VERSION "hnnbnnnynnnnnnnnnnnnnnnnnnnnnnnnnnnnnnnnnn/4/%%%/4/'%**4nnn///"

NS_ :

BS_:

BU_: BAP_Tester Fahrerdisplay_Kombi HUD ICAS1_X_Gateway ICAS3_Gateway ICC_IO_Node Kombi SmartLight_01 ZR_MIB_TOP_ab_Gen3

BO_ 1153 MainUnit_01: 8 ICAS3_Gateway
	SG_ DSSS_Warning : 16|5@1+ (1,0) [0|31] ""  ICAS1_X_Gateway
	SG_ HMI_WLC1_Systemzustand_intern : 40|3@1+ (1,0) [0|7] ""  ICAS1_X_Gateway
	SG_ HMI_WLC2_Systemzustand_intern : 43|3@1+ (1,0) [0|7] ""  ICAS1_X_Gateway
	SG_ INF_Nachlaufzeit : 52|10@1+ (1,0) [0|509] "Minut"  ICAS1_X_Gateway
	SG_ MIB_ASW_Diagnose : 7|1@1+ (1,0) [0|1] ""  ICAS1_X_Gateway
	SG_ MIB_Tongenerator_PH_verfuegbar : 9|3@1+ (1,0) [0|7] ""  ICAS1_X_Gateway
	SG_ MMI_Counter_Bedienevent : 12|4@1+ (1,0) [0|15] ""  ICAS1_X_Gateway
	SG_ MMI_Gurt_Mic_ref : 28|1@1+ (1,0) [0|1] ""  ICAS1_X_Gateway
	SG_ MMI_SDS_aktiv : 23|1@1+ (1,0) [0|1] ""  ICAS1_X_Gateway
	SG_ MMI_Telefon_aktiv : 27|1@1+ (1,0) [0|1] ""  ICAS1_X_Gateway
	SG_ MU_SecondDisplay : 24|3@1+ (1,0) [0|7] ""  ICAS1_X_Gateway
	SG_ MU_Update_Time : 32|8@1+ (0.1,0) [0|25.5] "Hours"  ICAS1_X_Gateway
	SG_ Nav_FoD_Status : 4|3@1+ (1,0) [0|7] ""  ICAS1_X_Gateway,Kombi
	SG_ ZR_AppConnect_Zustand : 31|1@1+ (1,0) [0|1] ""  ICAS1_X_Gateway
	SG_ ZR_Kindersicherung_RSE : 21|1@1+ (1,0) [0|1] ""  ICAS1_X_Gateway
	SG_ ZR_Lichter_Tag : 8|1@1+ (1,0) [0|1] ""  ICAS1_X_Gateway
	SG_ ZR_LoGeWa_Event_Kombiwarnung : 0|4@1+ (1,0) [0|15] ""  ICAS1_X_Gateway,Kombi
	SG_ ZR_Parken_Sondermodus : 48|4@1+ (1,0) [0|15] ""  ICAS1_X_Gateway
	SG_ ZR_RSE_aktivieren : 22|1@1+ (1,0) [0|1] ""  ICAS1_X_Gateway

BO_ 1639 Mem_BFS_01: 8 ICAS1_X_Gateway
	SG_ BFS_Fond_Bed_Ack : 12|1@1+ (1,0) [0|1] ""  Vector__XXX
	SG_ BFS_FSV_ausgeklappt : 42|1@1+ (1,0) [0|1] ""  Vector__XXX
	SG_ BFS_GHV_aktiv : 27|1@1+ (1,0) [0|1] ""  Vector__XXX
	SG_ BFS_Gurtbringer_Sperre : 15|1@1+ (1,0) [0|1] ""  Vector__XXX
	SG_ BFS_Klapptisch_offen : 14|1@1+ (1,0) [0|1] ""  Vector__XXX
	SG_ BFS_KSS_Fahrt_aktiv : 28|1@1+ (1,0) [0|1] ""  Vector__XXX
	SG_ BFS_KSV_aktiv : 22|1@1+ (1,0) [0|1] ""  Vector__XXX
	SG_ BFS_Lehne_nicht_verriegelt : 13|1@1+ (1,0) [0|1] ""  Vector__XXX
	SG_ BFS_LHV_aktiv : 25|1@1+ (1,0) [0|1] ""  Vector__XXX
	SG_ BFS_LKV_aktiv : 23|1@1+ (1,0) [0|1] ""  Vector__XXX
	SG_ BFS_LNV_aktiv : 20|1@1+ (1,0) [0|1] ""  Vector__XXX
	SG_ BFS_LWV_aktiv : 26|1@1+ (1,0) [0|1] ""  Vector__XXX
	SG_ BFS_MMB_glob_stop : 41|1@1+ (1,0) [0|1] ""  Vector__XXX
	SG_ BFS_MMB_lokal_Stop : 29|1@1+ (1,0) [0|1] ""  Vector__XXX
	SG_ BFS_MMB_storage : 32|4@1+ (1,0) [0|15] ""  Vector__XXX
	SG_ BFS_MMB_storage_beep : 39|1@1+ (1,0) [0|1] ""  Kombi
	SG_ BFS_MMB_store : 40|1@1+ (1,0) [0|1] ""  Vector__XXX
	SG_ BFS_MMB_store_LED_on : 38|1@1+ (1,0) [0|1] ""  Vector__XXX
	SG_ BFS_MMB_tast : 37|1@1+ (1,0) [0|1] ""  Vector__XXX
	SG_ BFS_MMB_tipp : 36|1@1+ (1,0) [0|1] ""  Vector__XXX
	SG_ BFS_Ruhestellung_Status : 30|1@1+ (1,0) [0|1] ""  Vector__XXX
	SG_ BFS_Seat_Locked : 31|1@1+ (1,0) [0|1] ""  Vector__XXX
	SG_ BFS_SHV_aktiv : 19|1@1+ (1,0) [0|1] ""  Vector__XXX
	SG_ BFS_Sitzfahrt_aktiv : 17|1@1+ (1,0) [0|1] ""  Vector__XXX
	SG_ BFS_Sitzsym_Fahrt_aktiv : 16|1@1+ (1,0) [0|1] ""  Vector__XXX
	SG_ BFS_SLV_aktiv : 18|1@1+ (1,0) [0|1] ""  Vector__XXX
	SG_ BFS_SNV_aktiv : 21|1@1+ (1,0) [0|1] ""  Vector__XXX
	SG_ BFS_STV_aktiv : 24|1@1+ (1,0) [0|1] ""  Vector__XXX

BO_ 1178 Mem_FS_01: 8 ICAS1_X_Gateway
	SG_ FS_BFS_Fond_Verst_enable : 44|1@1+ (1,0) [0|1] ""  Vector__XXX
	SG_ FS_BFS_KSS_Anfahrt : 28|1@1+ (1,0) [0|1] ""  Vector__XXX
	SG_ FS_BFS_Sitzsym_Anfahrt : 16|1@1+ (1,0) [0|1] ""  Vector__XXX
	SG_ FS_EE_BFS_enable : 45|1@1+ (1,0) [0|1] ""  Vector__XXX
	SG_ FS_EE_Fond_BFS_enable : 43|1@1+ (1,0) [0|1] ""  Vector__XXX
	SG_ FS_EE_Fond_FS_enable : 42|1@1+ (1,0) [0|1] ""  Vector__XXX
	SG_ FS_Fond_Bed_enable : 12|1@1+ (1,0) [0|1] ""  Vector__XXX
	SG_ FS_GHV_aktiv : 27|1@1+ (1,0) [0|1] ""  Vector__XXX
	SG_ FS_Gurtbringer_Sperre : 15|1@1+ (1,0) [0|1] ""  Vector__XXX
	SG_ FS_KSV_aktiv : 22|1@1+ (1,0) [0|1] ""  Vector__XXX
	SG_ FS_Lehne_nicht_verriegelt : 13|1@1+ (1,0) [0|1] ""  Vector__XXX
	SG_ FS_LHV_aktiv : 25|1@1+ (1,0) [0|1] ""  Vector__XXX
	SG_ FS_LKV_aktiv : 23|1@1+ (1,0) [0|1] ""  Vector__XXX
	SG_ FS_LNV_aktiv : 20|1@1+ (1,0) [0|1] ""  Vector__XXX
	SG_ FS_LWV_aktiv : 26|1@1+ (1,0) [0|1] ""  Vector__XXX
	SG_ FS_MMB_glob_stop : 41|1@1+ (1,0) [0|1] ""  Vector__XXX
	SG_ FS_MMB_lokal_Stop : 29|1@1+ (1,0) [0|1] ""  Vector__XXX
	SG_ FS_MMB_storage : 32|4@1+ (1,0) [0|15] ""  Vector__XXX
	SG_ FS_MMB_storage_beep : 39|1@1+ (1,0) [0|1] ""  Kombi
	SG_ FS_MMB_store : 40|1@1+ (1,0) [0|1] ""  Vector__XXX
	SG_ FS_MMB_store_LED_on : 38|1@1+ (1,0) [0|1] ""  Vector__XXX
	SG_ FS_MMB_tast : 37|1@1+ (1,0) [0|1] ""  Vector__XXX
	SG_ FS_MMB_tipp : 36|1@1+ (1,0) [0|1] ""  Vector__XXX
	SG_ FS_SHV_aktiv : 19|1@1+ (1,0) [0|1] ""  Vector__XXX
	SG_ FS_Sitzfahrt_aktiv : 17|1@1+ (1,0) [0|1] ""  Vector__XXX
	SG_ FS_SLV_aktiv : 18|1@1+ (1,0) [0|1] ""  Vector__XXX
	SG_ FS_SNV_aktiv : 21|1@1+ (1,0) [0|1] ""  Vector__XXX
	SG_ FS_Spezialposition_anfahren : 14|1@1+ (1,0) [0|1] ""  Vector__XXX
	SG_ FS_STV_aktiv : 24|1@1+ (1,0) [0|1] ""  Vector__XXX

BO_ 1171 MFG_01: 8 ICAS1_X_Gateway
	SG_ MF_Abzugssperre : 14|1@1+ (1,0) [0|1] ""  Vector__XXX
	SG_ MF_Alarm_Blinker : 50|1@1+ (1,0) [0|1] ""  Vector__XXX
	SG_ MF_Alarm_Blinkertakt : 49|1@1+ (1,0) [0|1] ""  Vector__XXX
	SG_ MF_Anlassersperre : 15|1@1+ (1,0) [0|1] ""  Vector__XXX
	SG_ MF_Blk_li : 32|1@1+ (1,0) [0|1] ""  Vector__XXX
	SG_ MF_Blk_re : 33|1@1+ (1,0) [0|1] ""  Vector__XXX
	SG_ MF_BT_entriegeln : 63|1@1+ (1,0) [0|1] ""  Vector__XXX
	SG_ MF_BT_verriegeln : 62|1@1+ (1,0) [0|1] ""  Vector__XXX
	SG_ MF_Fahrlicht : 25|1@1+ (1,0) [0|1] ""  Vector__XXX
	SG_ MF_Fernbed_ein : 23|1@1+ (1,0) [0|1] ""  Vector__XXX
	SG_ MF_Fernlicht : 35|1@1+ (1,0) [0|1] ""  Vector__XXX
	SG_ MF_FH_BT_hoch : 58|1@1+ (1,0) [0|1] ""  Vector__XXX
	SG_ MF_FH_BT_tief : 59|1@1+ (1,0) [0|1] ""  Vector__XXX
	SG_ MF_FH_FT_hoch : 56|1@1+ (1,0) [0|1] ""  Vector__XXX
	SG_ MF_FH_FT_tief : 57|1@1+ (1,0) [0|1] ""  Vector__XXX
	SG_ MF_Frontintervall : 41|1@1+ (1,0) [0|1] ""  Vector__XXX
	SG_ MF_Frontwaschen : 44|1@1+ (1,0) [0|1] ""  Vector__XXX
	SG_ MF_FT_entriegeln : 61|1@1+ (1,0) [0|1] ""  Vector__XXX
	SG_ MF_FT_verriegeln : 60|1@1+ (1,0) [0|1] ""  Vector__XXX
	SG_ MF_Fussraumbel : 28|1@1+ (1,0) [0|1] ""  Vector__XXX
	SG_ MF_HBFS_entriegeln : 39|1@1+ (1,0) [0|1] ""  Vector__XXX
	SG_ MF_HBFS_verriegeln : 38|1@1+ (1,0) [0|1] ""  Vector__XXX
	SG_ MF_Heckintervall : 46|1@1+ (1,0) [0|1] ""  Vector__XXX
	SG_ MF_Heckwaschen : 47|1@1+ (1,0) [0|1] ""  Vector__XXX
	SG_ MF_HFS_entriegeln : 37|1@1+ (1,0) [0|1] ""  Vector__XXX
	SG_ MF_HFS_verriegeln : 36|1@1+ (1,0) [0|1] ""  Vector__XXX
	SG_ MF_Innenraumbel : 29|1@1+ (1,0) [0|1] ""  Vector__XXX
	SG_ MF_Innenraumbel_Unterdrueck : 30|1@1+ (1,0) [0|1] ""  SmartLight_01
	SG_ MF_interm_Fahrlicht : 54|1@1+ (1,0) [0|1] ""  Vector__XXX
	SG_ MF_interm_Fernlicht : 26|1@1+ (1,0) [0|1] ""  Vector__XXX
	SG_ MF_interm_Takt : 52|1@1+ (1,0) [0|1] ""  Vector__XXX
	SG_ MF_Laderelais : 20|1@1+ (1,0) [0|1] ""  Vector__XXX
	SG_ MF_Lichthupe : 34|1@1+ (1,0) [0|1] ""  Vector__XXX
	SG_ MF_Motorweiterlauf : 13|1@1+ (1,0) [0|1] ""  Vector__XXX
	SG_ MF_nachtr_Stopp_Anf : 45|1@1+ (1,0) [0|1] ""  Vector__XXX
	SG_ MF_Notstart : 31|1@1+ (1,0) [0|1] ""  Vector__XXX
	SG_ MF_Schluessel_scan : 19|1@1+ (1,0) [0|1] ""  Vector__XXX
	SG_ MF_Signalhorn : 55|1@1+ (1,0) [0|1] ""  Vector__XXX
	SG_ MF_Standlicht : 24|1@1+ (1,0) [0|1] ""  Vector__XXX
	SG_ MF_StartStopp_Info : 21|2@1+ (1,0) [0|3] ""  Vector__XXX
	SG_ MF_Summer : 48|1@1+ (1,0) [0|1] ""  Kombi
	SG_ MF_TFL_Abschaltung : 51|1@1+ (1,0) [0|1] ""  Vector__XXX
	SG_ MF_Tippwischen : 40|1@1+ (1,0) [0|1] ""  Vector__XXX
	SG_ MF_Tuerentriegelung_hinten : 53|1@1+ (1,0) [0|1] ""  Vector__XXX
	SG_ MF_Variante : 16|3@1+ (1,0) [0|7] ""  Vector__XXX
	SG_ MF_Warnblinker : 27|1@1+ (1,0) [0|1] ""  Vector__XXX
	SG_ MF_Wischerstufe_1 : 42|1@1+ (1,0) [0|1] ""  Vector__XXX
	SG_ MF_Wischerstufe_2 : 43|1@1+ (1,0) [0|1] ""  Vector__XXX
	SG_ MF_ZV_Lock : 12|1@1+ (1,0) [0|1] ""  Vector__XXX
	SG_ MFG_01_BZ : 8|4@1+ (1,0) [0|15] ""  Vector__XXX
	SG_ MFG_01_CRC : 0|8@1+ (1,0) [0|255] ""  Vector__XXX

BO_ 1164 MFG_03: 8 ICAS1_X_Gateway
	SG_ MF_2BatSOCzugering : 42|1@1+ (1,0) [0|1] ""  Vector__XXX
	SG_ MF_2BattAb : 48|1@1+ (1,0) [0|1] ""  Vector__XXX
	SG_ MF_2BattHlkAnf : 49|1@1+ (1,0) [0|1] ""  Vector__XXX
	SG_ MF_2BattLadWarn : 50|1@1+ (1,0) [0|1] ""  Vector__XXX
	SG_ MF_2BattLlaAnf : 51|1@1+ (1,0) [0|1] ""  Vector__XXX
	SG_ MF_2BattSpannungsAnf : 52|2@1+ (1,0) [0|3] ""  Vector__XXX
	SG_ MF_Batteriediagnose : 29|3@1+ (1,0) [0|7] ""  Vector__XXX
	SG_ MF_Blinker_L_Sta : 35|1@1+ (1,0) [0|1] ""  Vector__XXX
	SG_ MF_Blinker_R_Sta : 36|1@1+ (1,0) [0|1] ""  Vector__XXX
	SG_ MF_ExterneLadungWarn : 55|1@1+ (1,0) [0|1] ""  Vector__XXX
	SG_ MF_Fahrerhinweis : 43|3@1+ (1,0) [0|7] ""  Vector__XXX
	SG_ MF_Generatordiagnose : 38|2@1+ (1,0) [0|3] ""  Vector__XXX
	SG_ MF_Heck_entriegeln : 40|1@1+ (1,0) [0|1] ""  Vector__XXX
	SG_ MF_Heck_verriegeln : 41|1@1+ (1,0) [0|1] ""  Vector__XXX
	SG_ MF_interm_Nebelscheinwerfer : 37|1@1+ (1,0) [0|1] ""  Vector__XXX
	SG_ MF_Lampenausfall : 34|1@1+ (1,0) [0|1] ""  Vector__XXX
	SG_ MF_LSH_Abschaltstufe : 60|3@1+ (1,0) [0|7] ""  Vector__XXX
	SG_ MF_LSH_Einschaltverbot : 63|1@1+ (1,0) [0|1] ""  Vector__XXX
	SG_ MF_LSH_Zielzeit : 56|4@1+ (10,0) [0|130] "Minut"  Vector__XXX
	SG_ MF_NotStartAktiv : 54|1@1+ (1,0) [0|1] ""  Vector__XXX
	SG_ MF_Radiomute : 27|1@1+ (1,0) [0|1] ""  ICAS3_Gateway
	SG_ MF_Relais_2_Batterie : 28|1@1+ (1,0) [0|1] ""  Vector__XXX
	SG_ MF_Tuerverriegelung_hinten : 47|1@1+ (1,0) [0|1] ""  Vector__XXX
	SG_ MF_ZV_Unlock : 46|1@1+ (1,0) [0|1] ""  Vector__XXX
	SG_ MFG_AppConnect_Anf : 32|2@1+ (1,0) [0|3] ""  Vector__XXX
	SG_ MFG_Klappe_Status : 13|3@1+ (1,0) [0|7] ""  Vector__XXX

BO_ 817 MFL_01: 8 ICAS1_X_Gateway
	SG_ MFL_Dummy_0_Signal_1 : 40|8@1+ (1,0) [0|255] ""  Vector__XXX
	SG_ MFL_Dummy_0_Signal_3 : 53|1@1+ (1,0) [0|1] ""  Vector__XXX
	SG_ MFL_ECU_Err : 62|1@1+ (1,0) [0|1] ""  Vector__XXX
	SG_ MFL_Eventcode_1 : 24|4@1+ (1,0) [0|15] ""  Vector__XXX
	SG_ MFL_Eventcode_2 : 28|4@1+ (1,0) [0|15] ""  Vector__XXX
	SG_ MFL_Fehler_Codierung : 52|1@1+ (1,0) [0|1] ""  Vector__XXX
	SG_ MFL_Lokalaktiv : 5|1@1+ (1,0) [0|1] ""  Vector__XXX
	SG_ MFL_LR_HZG_Err : 55|1@1+ (1,0) [0|1] ""  Vector__XXX
	SG_ MFL_LR_HZG_Status : 54|1@1+ (1,0) [0|1] ""  Vector__XXX
	SG_ MFL_M_Taste : 6|1@1+ (1,0) [0|1] ""  Vector__XXX
	SG_ MFL_Marke : 32|4@1+ (1,0) [0|15] ""  Vector__XXX
	SG_ MFL_Paddle_Verbau : 7|1@1+ (1,0) [0|1] ""  Kombi
	SG_ MFL_Response_Err : 63|1@1+ (1,0) [0|1] ""  Vector__XXX
	SG_ MFL_SatModul_links_Err : 50|1@1+ (1,0) [0|1] ""  Vector__XXX
	SG_ MFL_SatModul_rechts_Err : 51|1@1+ (1,0) [0|1] ""  Vector__XXX
	SG_ MFL_Signalhorn : 56|1@1+ (1,0) [0|1] ""  Vector__XXX
	SG_ MFL_Signalhorn_Err : 57|1@1+ (1,0) [0|1] ""  Vector__XXX
	SG_ MFL_Taste_links_Err : 60|1@1+ (1,0) [0|1] ""  Vector__XXX
	SG_ MFL_Taste_rechts_Err : 61|1@1+ (1,0) [0|1] ""  Vector__XXX
	SG_ MFL_Tastencode_1 : 8|8@1+ (1,0) [0|255] ""  Vector__XXX
	SG_ MFL_Tastencode_2 : 16|8@1+ (1,0) [0|255] ""  Vector__XXX
	SG_ MFL_Tip_Down : 48|1@1+ (1,0) [0|1] ""  Vector__XXX
	SG_ MFL_Tip_links_Err : 58|1@1+ (1,0) [0|1] ""  Vector__XXX
	SG_ MFL_Tip_rechts_Err : 59|1@1+ (1,0) [0|1] ""  Vector__XXX
	SG_ MFL_Tip_Up : 49|1@1+ (1,0) [0|1] ""  Vector__XXX
	SG_ MFL_Toggle : 4|1@1+ (1,0) [0|1] ""  Vector__XXX
	SG_ MFL_Variante : 36|4@1+ (1,0) [0|15] ""  Vector__XXX
	SG_ MFL_Zaehler : 0|4@1+ (1,0) [0|15] ""  Vector__XXX

BO_ 560 MFL_02: 8 ICAS1_X_Gateway
	SG_ MFL_Beruehrungserkennung : 12|2@1+ (1,0) [0|3] ""  ICAS3_Gateway
	SG_ MFL_Touch_Event : 14|4@1+ (1,0) [0|15] ""  ICAS3_Gateway

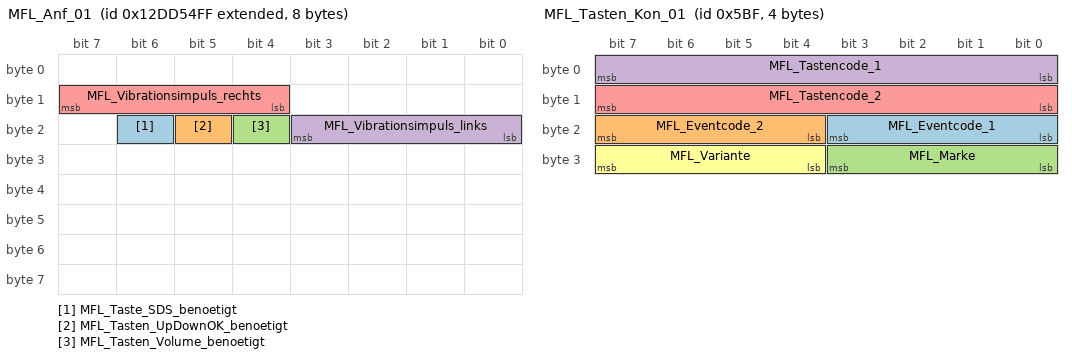
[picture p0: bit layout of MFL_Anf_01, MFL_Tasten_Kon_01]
BO_ 2463978751 MFL_Anf_01: 8 ICAS3_Gateway
	SG_ MFL_Taste_SDS_benoetigt : 22|1@1+ (1,0) [0|1] ""  ICAS1_X_Gateway
	SG_ MFL_Tasten_UpDownOK_benoetigt : 21|1@1+ (1,0) [0|1] ""  ICAS1_X_Gateway
	SG_ MFL_Tasten_Volume_benoetigt : 20|1@1+ (1,0) [0|1] ""  ICAS1_X_Gateway
	SG_ MFL_Vibrationsimpuls_links : 16|4@1+ (1,0) [0|15] ""  ICAS1_X_Gateway
	SG_ MFL_Vibrationsimpuls_rechts : 12|4@1+ (1,0) [0|15] ""  ICAS1_X_Gateway

BO_ 1471 MFL_Tasten_Kon_01: 4 ICAS1_X_Gateway
	SG_ MFL_Eventcode_1 : 16|4@1+ (1,0) [0|15] ""  ICAS3_Gateway,ICC_IO_Node,Kombi,ZR_MIB_TOP_ab_Gen3
	SG_ MFL_Eventcode_2 : 20|4@1+ (1,0) [0|15] ""  ICAS3_Gateway,ICC_IO_Node,Kombi,ZR_MIB_TOP_ab_Gen3
	SG_ MFL_Marke : 24|4@1+ (1,0) [0|15] ""  ICAS3_Gateway,ICC_IO_Node,Kombi,ZR_MIB_TOP_ab_Gen3
	SG_ MFL_Tastencode_1 : 0|8@1+ (1,0) [0|255] ""  ICAS3_Gateway,ICC_IO_Node,Kombi,ZR_MIB_TOP_ab_Gen3
	SG_ MFL_Tastencode_2 : 8|8@1+ (1,0) [0|255] ""  ICAS3_Gateway,ICC_IO_Node,Kombi,ZR_MIB_TOP_ab_Gen3
	SG_ MFL_Variante : 28|4@1+ (1,0) [0|15] ""  ICAS3_Gateway,ICC_IO_Node,Kombi,ZR_MIB_TOP_ab_Gen3

BO_ 958 Motor_14: 8 ICAS1_X_Gateway
	SG_ MO_Aussp_Anlass : 35|1@1+ (1,0) [0|1] ""  Vector__XXX
	SG_ MO_BKV_Unterdruckwarnung : 45|1@1+ (1,0) [0|1] ""  Vector__XXX
	SG_ MO_BLS : 30|1@1+ (1,0) [0|1] ""  Vector__XXX
	SG_ MO_BMS_NV_Anf_stuetzen : 58|1@1+ (1,0) [0|1] ""  Vector__XXX
	SG_ MO_EKlKomLeiRed : 42|2@1+ (1,0) [0|3] ""  Vector__XXX
	SG_ MO_Ext_E_Fahrt_aktiv : 27|1@1+ (1,0) [0|1] ""  Vector__XXX
	SG_ MO_Fahrer_bremst : 28|1@1+ (1,0) [0|1] ""  ZR_MIB_TOP_ab_Gen3
	SG_ MO_FMAus_aktiv : 55|1@1+ (1,0) [0|1] ""  Vector__XXX
	SG_ MO_FMAus_Startvariante : 56|2@1+ (1,0) [0|3] ""  Vector__XXX
	SG_ MO_Freig_Anlass : 36|1@1+ (1,0) [0|1] ""  Vector__XXX
	SG_ MO_Freig_Reku : 16|2@1+ (1,0) [0|3] ""  Vector__XXX
	SG_ MO_Freigabe_Segeln : 46|1@1+ (1,0) [0|1] ""  Vector__XXX
	SG_ MO_Gangposition : 20|4@1+ (1,0) [0|15] ""  Vector__XXX
	SG_ MO_Handshake_STH : 44|1@1+ (1,0) [0|1] ""  Vector__XXX
	SG_ MO_HYB_Fahrbereitschaft : 26|1@1+ (1,0) [0|1] ""  ICAS3_Gateway,Kombi
	SG_ MO_HYB_VM_aktiv : 61|1@1+ (1,0) [0|1] ""  Vector__XXX
	SG_ MO_Interlock : 38|1@1+ (1,0) [0|1] ""  Vector__XXX
	SG_ MO_Kickdown : 40|1@1+ (1,0) [0|1] ""  ZR_MIB_TOP_ab_Gen3
	SG_ MO_Kl_50 : 19|1@1+ (1,0) [0|1] ""  ZR_MIB_TOP_ab_Gen3
	SG_ MO_Kl_75 : 18|1@1+ (1,0) [0|1] ""  ZR_MIB_TOP_ab_Gen3
	SG_ MO_Klima_Eingr : 33|2@1+ (1,0) [0|3] ""  Vector__XXX
	SG_ MO_Konsistenz_Bremsped : 31|1@1+ (1,0) [0|1] ""  Vector__XXX
	SG_ MO_Kuppl_schalter : 37|1@1+ (1,0) [0|1] ""  Vector__XXX
	SG_ MO_Motor_laeuft : 39|1@1+ (1,0) [0|1] ""  Vector__XXX
	SG_ MO_PTC_Status : 47|3@1+ (1,0) [0|7] ""  Vector__XXX
	SG_ MO_QBit_Fahrer_bremst : 29|1@1+ (1,0) [0|1] ""  ZR_MIB_TOP_ab_Gen3
	SG_ MO_QBit_Gangposition : 50|1@1+ (1,0) [0|1] ""  Vector__XXX
	SG_ MO_QBit_KL_75 : 41|1@1+ (1,0) [0|1] ""  Vector__XXX
	SG_ MO_Remotestart_Betrieb : 52|1@1+ (1,0) [0|1] ""  Vector__XXX
	SG_ MO_Remotestart_moeglich : 53|1@1+ (1,0) [0|1] ""  Vector__XXX
	SG_ MO_Signalquelle_Gangposition : 51|1@1+ (1,0) [0|1] ""  Vector__XXX
	SG_ MO_StartStopp_Fahrerwunsch : 24|2@1+ (1,0) [0|3] ""  Vector__XXX
	SG_ MO_StartStopp_Motorstopp : 15|1@1+ (1,0) [0|1] ""  Vector__XXX
	SG_ MO_StartStopp_Status : 12|2@1+ (1,0) [0|3] ""  Vector__XXX
	SG_ MO_StartStopp_Wiederstart : 14|1@1+ (1,0) [0|1] ""  ZR_MIB_TOP_ab_Gen3
	SG_ MO_StartVorauss_erfuellt : 62|2@1+ (1,0) [0|3] ""  Vector__XXX
	SG_ MO_Timeout_ESP : 32|1@1+ (1,0) [0|1] ""  Vector__XXX
	SG_ MO_Zylinderabschaltung : 59|2@1+ (1,0) [0|3] ""  Vector__XXX
	SG_ Motor_14_BZ : 8|4@1+ (1,0) [0|15] ""  Vector__XXX
	SG_ Motor_14_CRC : 0|8@1+ (1,0) [0|255] ""  Vector__XXX

BO_ 1648 Motor_18: 8 ICAS1_X_Gateway
	SG_ MO1_Freigabe_Info_WFS : 12|1@1+ (1,0) [0|1] ""  Vector__XXX
	SG_ MO1_Freigabe_Verfallsinfo_WFS : 42|1@1+ (1,0) [0|1] ""  Vector__XXX
	SG_ MO1_Sperr_Info_WFS : 11|1@1+ (1,0) [0|1] ""  Vector__XXX
	SG_ MO_Abstellzeit : 32|8@1+ (8,0) [0|2024] "Minut"  Vector__XXX
	SG_ MO_Abstellzeit_Status : 40|2@1+ (1,0) [0|3] ""  Vector__XXX
	SG_ MO_ANC_Kennfeld_Anf : 6|2@1+ (1,0) [0|3] ""  Vector__XXX
	SG_ MO_Anzahl_Abgesch_Zyl : 47|3@1+ (1,0) [0|7] ""  Vector__XXX
	SG_ MO_Bremslicht_Reku : 8|1@1+ (1,0) [0|1] ""  Vector__XXX
	SG_ MO_Drehzahl_Warnung : 55|1@1+ (1,0) [0|1] ""  Vector__XXX
	SG_ MO_EPCL : 13|3@1+ (1,0) [0|7] ""  Fahrerdisplay_Kombi,Kombi
	SG_ MO_Ethanol_BS_Texte : 52|3@1+ (1,0) [0|7] ""  Vector__XXX
	SG_ MO_Fahrzeugtyp : 20|3@1+ (1,0) [0|7] ""  Fahrerdisplay_Kombi,Kombi
	SG_ MO_Fehler_Zylabsch : 45|2@1+ (1,0) [0|3] ""  Vector__XXX
	SG_ MO_Hybrid_StartStopp_LED : 43|2@1+ (1,0) [0|3] ""  Vector__XXX
	SG_ MO_max_Ladedruck : 0|6@1+ (0.1,0) [0|6.3] "Bar"  Vector__XXX
	SG_ MO_NMAX_Schaltanzeige : 23|9@1+ (25,0) [0|12775] "MinutInver"  Vector__XXX
	SG_ MO_obere_Drehzahlgrenze : 56|8@1+ (50,0) [50|12750] "MinutInver"  Vector__XXX
	SG_ MO_StartStopp_PopUp : 9|2@1+ (1,0) [0|3] ""  Vector__XXX
	SG_ MO_Zylabsch_Texte : 50|2@1+ (1,0) [0|3] ""  Vector__XXX
	SG_ MO_Zylabsch_Texte_02 : 16|4@1+ (1,0) [0|15] ""  Vector__XXX

BO_ 967 Motor_26: 8 ICAS1_X_Gateway
	SG_ MO_E_Mode : 61|3@1+ (1,0) [0|7] ""  Vector__XXX
	SG_ MO_E_Texte : 36|4@1+ (1,0) [0|15] ""  Vector__XXX
	SG_ MO_E_Warnungen : 28|4@1+ (1,0) [0|15] ""  Vector__XXX
	SG_ MO_EFLEX_Lampe : 8|2@1+ (1,0) [0|3] ""  Vector__XXX
	SG_ MO_Heissleuchte : 50|1@1+ (1,0) [0|1] ""  Vector__XXX
	SG_ MO_ITM_Warnung_Pumpe : 11|1@1+ (1,0) [0|1] ""  Vector__XXX
	SG_ MO_KJS_nicht_bereit : 10|1@1+ (1,0) [0|1] ""  Vector__XXX
	SG_ MO_Kuehlerluefter_1 m0 : 1|7@1+ (1,0) [0|100] "PerCent"  Vector__XXX
	SG_ MO_Kuehlerluefter_2 m1 : 1|7@1+ (1,0) [0|100] "PerCent"  Vector__XXX
	SG_ MO_Kuehlerluefter_MUX M : 0|1@1+ (1,0) [0|1] ""  Vector__XXX
	SG_ MO_OBD2_Lampe : 49|1@1+ (1,0) [0|1] ""  Fahrerdisplay_Kombi,Kombi
	SG_ MO_Oelwarnung_max : 23|1@1+ (1,0) [0|1] ""  Vector__XXX
	SG_ MO_Partikel_Lampe : 51|1@1+ (1,0) [0|1] ""  Vector__XXX
	SG_ MO_RedFahrleistung_Lampe : 52|1@1+ (1,0) [0|1] ""  Kombi
	SG_ MO_Systemlampe : 48|1@1+ (1,0) [0|1] ""  Vector__XXX
	SG_ MO_Tankdeckel_Lampe : 57|1@1+ (1,0) [0|1] ""  Vector__XXX
	SG_ MO_Text_Motorstart : 32|4@1+ (1,0) [0|15] ""  Vector__XXX
	SG_ MO_Text_Partikelfil_Reg : 41|1@1+ (1,0) [0|1] ""  Vector__XXX
	SG_ MO_Text_Tankdeckelwarn : 58|1@1+ (1,0) [0|1] ""  Vector__XXX
	SG_ MO_Vorglueh_Lampe : 59|1@1+ (1,0) [0|1] ""  Vector__XXX
	SG_ MO_Zustand_HWP : 20|2@1+ (1,0) [0|3] ""  Vector__XXX
	SG_ OLEV_Oelstand_nicht_vorhanden : 42|1@1+ (1,0) [0|1] ""  Vector__XXX
	SG_ OLEV_Systemstoerung : 22|1@1+ (1,0) [0|1] ""  Vector__XXX
	SG_ WIV_Anzeige_aktiv : 12|1@1+ (1,0) [0|1] ""  Vector__XXX
	SG_ WIV_laufender_Motor : 27|1@1+ (1,0) [0|1] ""  Vector__XXX
	SG_ WIV_nachfuellanzeige_ein : 54|1@1+ (1,0) [0|1] ""  Vector__XXX
	SG_ WIV_nicht_betriebswarm : 25|1@1+ (1,0) [0|1] ""  Vector__XXX
	SG_ WIV_Oeldr_Warn_Motor : 60|1@1+ (1,0) [0|1] ""  Vector__XXX
	SG_ WIV_Oeldyn_avl : 40|1@1+ (1,0) [0|1] ""  Vector__XXX
	SG_ WIV_Oelmenge : 43|5@1+ (125,0) [0|3875] "MilliLiter"  Vector__XXX
	SG_ WIV_Oelmin_Warn : 13|1@1+ (1,0) [0|1] ""  Vector__XXX
	SG_ WIV_Oelstand : 16|4@1+ (12.5,0) [0|100] "PerCent"  Vector__XXX
	SG_ WIV_Oelstand_nicht_vorhanden : 53|1@1+ (1,0) [0|1] ""  Vector__XXX
	SG_ WIV_Oelsystem_aktiv : 24|1@1+ (1,0) [0|1] ""  Vector__XXX
	SG_ WIV_Schieflage : 15|1@1+ (1,0) [0|1] ""  Vector__XXX
	SG_ WIV_Sensorfehler : 14|1@1+ (1,0) [0|1] ""  Vector__XXX
	SG_ WIV_Ueberfuell_deaktiv : 55|1@1+ (1,0) [0|1] ""  Vector__XXX
	SG_ WIV_Ueberfuell_Warn : 26|1@1+ (1,0) [0|1] ""  Vector__XXX
	SG_ WIV_Unterfuell_Warn : 56|1@1+ (1,0) [0|1] ""  Vector__XXX

BO_ 966 Motor_26_SOK_Signatur: 8 ICAS1_X_Gateway
	SG_ SOK_Motor_26_Signatur : 0|64@1+ (1,0) [0|18446744073709551616] ""  Vector__XXX

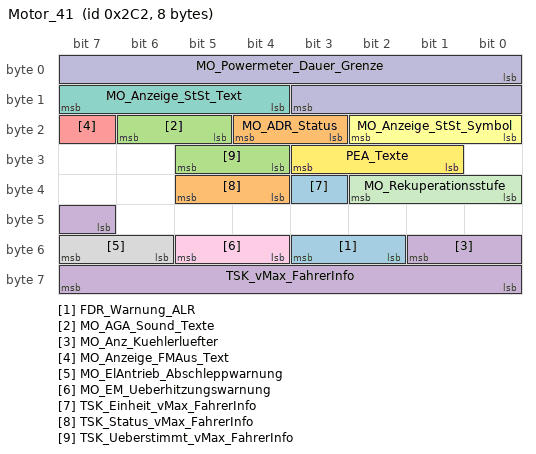
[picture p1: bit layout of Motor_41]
BO_ 706 Motor_41: 8 ICAS1_X_Gateway
	SG_ FDR_Warnung_ALR : 50|2@1+ (1,0) [0|3] ""  Kombi
	SG_ MO_ADR_Status : 19|2@1+ (1,0) [0|3] ""  Vector__XXX
	SG_ MO_AGA_Sound_Texte : 21|2@1+ (1,0) [0|3] ""  Vector__XXX
	SG_ MO_Anz_Kuehlerluefter : 47|3@1+ (1,0) [0|7] ""  Vector__XXX
	SG_ MO_Anzeige_FMAus_Text : 23|1@1+ (1,0) [0|1] ""  Vector__XXX
	SG_ MO_Anzeige_StSt_Symbol : 16|3@1+ (1,0) [0|7] ""  Vector__XXX
	SG_ MO_Anzeige_StSt_Text : 12|4@1+ (1,0) [0|15] ""  Vector__XXX
	SG_ MO_ElAntrieb_Abschleppwarnung : 54|2@1+ (1,0) [0|3] ""  Kombi
	SG_ MO_EM_Ueberhitzungswarnung : 52|2@1+ (1,0) [0|3] ""  Kombi
	SG_ MO_Powermeter_Dauer_Grenze : 0|12@1+ (1,0) [0|4093] "None"  Vector__XXX
	SG_ MO_Rekuperationsstufe : 32|3@1+ (1,0) [0|7] ""  Kombi
	SG_ PEA_Texte : 25|3@1+ (1,0) [0|7] ""  Vector__XXX
	SG_ TSK_Einheit_vMax_FahrerInfo : 35|1@1+ (1,0) [0|1] ""  Vector__XXX
	SG_ TSK_Status_vMax_FahrerInfo : 36|2@1+ (1,0) [0|3] ""  Vector__XXX
	SG_ TSK_Ueberstimmt_vMax_FahrerInfo : 28|2@1+ (1,0) [0|3] ""  Vector__XXX
	SG_ TSK_vMax_FahrerInfo : 56|8@1+ (1,15) [16|270] ""  Vector__XXX

BO_ 267 Motor_51_Auth: 48 ICAS1_X_Gateway
	SG_ MO_Entkopplung_Sollschlupf : 48|7@1+ (20,0) [0|2480] "MinutInver"  Vector__XXX
	SG_ MO_Fahrpedalgradient : 21|8@1+ (25,0) [0|6350] "PerCentPerSecon"  Vector__XXX
	SG_ MO_Fahrpedalrohwert_01 : 12|8@1+ (0.4,0) [0|101.6] "PerCent"  ZR_MIB_TOP_ab_Gen3
	SG_ MO_Moment_im_Leerlauf : 37|1@1+ (1,0) [0|1] ""  Vector__XXX
	SG_ MO_QBit_Fahrpedalwerte_01 : 20|1@1+ (1,0) [0|1] ""  Vector__XXX
	SG_ MO_rel_Saugrohrdruck : 30|6@1+ (18,0) [0|1116] "MilliBar"  Vector__XXX
	SG_ MO_rel_Saugrohrdruck_gem_err : 36|1@1+ (1,0) [0|1] ""  Vector__XXX
	SG_ MO_Schubabschaltung : 38|1@1+ (1,0) [0|1] ""  Vector__XXX
	SG_ MO_Sig_Fahrpedalgradient : 29|1@1+ (1,0) [0|1] ""  Vector__XXX
	SG_ MO_Solldrehz_Leerlauf : 40|8@1+ (10,0) [0|2540] "MinutInver"  Vector__XXX
	SG_ MO_StartStopp_StoppVorbereitung : 39|1@1+ (1,0) [0|1] ""  Vector__XXX
	SG_ MO_Status_MaxDrzEingriff : 238|3@1+ (1,0) [0|7] ""  Vector__XXX
	SG_ MO_Status_MaxDrzEingriff_sek : 244|3@1+ (1,0) [0|7] ""  Vector__XXX
	SG_ MO_Status_MinDrzEingriff : 235|3@1+ (1,0) [0|7] ""  Vector__XXX
	SG_ MO_Status_MinDrzEingriff_sek : 241|3@1+ (1,0) [0|7] ""  Vector__XXX
	SG_ MO_temporaere_Fahrerabwesenheit : 55|1@1+ (1,0) [0|1] ""  Vector__XXX
	SG_ Motor_51_BZ : 8|4@1+ (1,0) [0|15] ""  Vector__XXX
	SG_ Motor_51_CRC : 0|8@1+ (1,0) [0|255] ""  Vector__XXX
	SG_ SOK_Motor_51_Signatur : 352|32@1+ (1,0) [0|4294967295] ""  Vector__XXX
	SG_ TSK_a_Soll_gradientenbegrenzt : 57|7@1+ (0.1,-7.2) [-7.2|5.4] "MeterPerSeconSquar"  Vector__XXX
	SG_ TSK_ax_Getriebe_02 : 112|9@1+ (0.024,-2.016) [-2.016|10.224] "MeterPerSeconSquar"  Vector__XXX
	SG_ TSK_Freig_Verzoeg_Anf : 94|1@1+ (1,0) [0|1] ""  Vector__XXX
	SG_ TSK_Hauptschalter_GRA_ACC : 106|2@1+ (1,0) [0|3] ""  Kombi
	SG_ TSK_Kategorie_Verzoegerungsfkt : 144|2@1+ (1,0) [0|3] ""  Vector__XXX
	SG_ TSK_Limiter_ausgewaehlt : 95|1@1+ (1,0) [0|1] ""  Vector__XXX
	SG_ TSK_Notstopp_Anf : 233|2@1+ (1,0) [0|3] ""  Vector__XXX
	SG_ TSK_Radbremsmom : 76|12@1+ (8,0) [0|32760] "NewtoMeter"  Vector__XXX
	SG_ TSK_Radsollmoment : 128|16@1+ (0.5,-16383) [-16383|16383.5] "NewtoMeter"  Vector__XXX
	SG_ TSK_SRBM_Anf_ASIL : 108|3@1+ (1,0) [0|7] ""  Vector__XXX
	SG_ TSK_SRBM_max_Gradient : 248|7@1+ (50,0) [0|6250] "NewtoMeterPerSecon"  Vector__XXX
	SG_ TSK_Standby_Anf_ESP : 92|1@1+ (1,0) [0|1] ""  Vector__XXX
	SG_ TSK_Status : 88|3@1+ (1,0) [0|7] ""  Vector__XXX
	SG_ TSK_v_Begrenzung_aktiv : 91|1@1+ (1,0) [0|1] ""  Vector__XXX
	SG_ TSK_zul_Regelabw : 122|6@1+ (0.024,0) [0|1.512] "MeterPerSeconSquar"  Vector__XXX
	SG_ TSK_Zwangszusch_ESP : 121|1@1+ (1,0) [0|1] ""  Vector__XXX

BO_ 330 Motor_52: 32 ICAS1_X_Gateway
	SG_ Ladezustand_02 : 152|8@1+ (0.5,0) [0|100] "PerCent"  Kombi,ZR_MIB_TOP_ab_Gen3
	SG_ Ladezustand_gering : 160|2@1+ (1,0) [0|3] ""  Kombi
	SG_ MO_Anzeige_Drehmoment : 42|11@1+ (1,0) [0|2045] "NewtoMeter"  Vector__XXX
	SG_ MO_Anzeige_Leistung : 53|11@1+ (0.6,0) [0|1227] "KiloWatt"  Vector__XXX
	SG_ MO_Anzeige_Verbr_Einheit : 33|2@1+ (1,0) [0|3] ""  Vector__XXX
	SG_ MO_Anzeigedrehz : 88|12@1+ (3,0) [0|12282] "MinutInver"  Vector__XXX
	SG_ MO_Effizienzmodus : 100|1@1+ (1,0) [0|1] ""  Vector__XXX
	SG_ MO_ePerformance : 136|8@1+ (0.4,-0.4) [0|100.8] "PerCent"  Kombi
	SG_ MO_ePowermeter : 128|8@1+ (0.4,-0.4) [0|100.8] "PerCent"  Vector__XXX
	SG_ MO_Fehler_Oeldrucksensor : 101|1@1+ (1,0) [0|1] ""  Vector__XXX
	SG_ MO_Hochschaltdrehz : 21|12@1+ (3,0) [3|12282] "MinutInver"  Vector__XXX
	SG_ MO_Istgang : 72|4@1+ (1,0) [0|15] ""  Vector__XXX
	SG_ MO_KVS : 112|15@1+ (1,0) [0|32767] "MicroLiter"  Vector__XXX
	SG_ MO_KVS_Ueberlauf : 127|1@1+ (1,0) [0|1] ""  Vector__XXX
	SG_ MO_Ladedruck : 103|9@1+ (0.01,0) [0|5.1] "Bar"  Vector__XXX
	SG_ MO_Oeldruck : 80|8@1+ (0.04,0) [0|10] "Bar"  Vector__XXX
	SG_ MO_OnePedalDriving_Warnung : 192|2@1+ (1,0) [0|3] ""  Fahrerdisplay_Kombi,Kombi
	SG_ MO_Powermeter : 180|12@1+ (1,0) [0|4092] ""  Kombi
	SG_ MO_Powermeter_Elm_02 : 168|12@1+ (0.05,-102.4) [-100|100] "PerCent"  Vector__XXX
	SG_ MO_rel_Ladedruck : 64|8@1+ (0.4,0) [0|100] "PerCent"  Vector__XXX
	SG_ MO_Schaltblitz_Anz : 35|7@1+ (1,0) [0|100] "PerCent"  Vector__XXX
	SG_ MO_Schaltempf_verfbar : 102|1@1+ (1,0) [0|1] ""  Vector__XXX
	SG_ MO_Sollgang : 76|4@1+ (1,0) [0|15] ""  Vector__XXX
	SG_ MO_Zust_Antrieb : 144|4@1+ (1,0) [0|15] ""  Vector__XXX
	SG_ MO_Zust_Betriebsstrategie : 148|3@1+ (1,0) [0|7] ""  Vector__XXX
	SG_ Motor_52_BZ : 8|4@1+ (1,0) [0|15] ""  Kombi
	SG_ Motor_52_CRC : 0|8@1+ (1,0) [0|255] ""  Kombi

BO_TX_BU_ 1153 :ICAS3_Gateway,ZR_MIB_TOP_ab_Gen3;
BO_TX_BU_ 1639 :ICAS1_X_Gateway;
BO_TX_BU_ 1178 :ICAS1_X_Gateway;
BO_TX_BU_ 1171 :ICAS1_X_Gateway;
BO_TX_BU_ 1164 :ICAS1_X_Gateway;
BO_TX_BU_ 817 :ICAS1_X_Gateway;
BO_TX_BU_ 560 :ICAS1_X_Gateway;
BO_TX_BU_ 2463978751 :ICAS3_Gateway;
BO_TX_BU_ 1471 :ICAS1_X_Gateway;
BO_TX_BU_ 958 :ICAS1_X_Gateway;
BO_TX_BU_ 1648 :ICAS1_X_Gateway;
BO_TX_BU_ 967 :ICAS1_X_Gateway;
BO_TX_BU_ 966 :ICAS1_X_Gateway;
BO_TX_BU_ 706 :ICAS1_X_Gateway;
BO_TX_BU_ 267 :ICAS1_X_Gateway;
BO_TX_BU_ 330 :ICAS1_X_Gateway;
CM_ BO_ 1639 "MLBevo";
CM_ BO_ 1178 "ab MQB 7.2";
CM_ BO_ 1171 "ab MQB 7.2 gï?½ltig";
CM_ BO_ 1648 "Kombischnittstelle";
CM_ BO_ 967 "MQB - vorher Motor_06 / Umbenennung wg. ID-Wechsel";
CM_ SG_ 1153 DSSS_Warning "DSSS - Driving Safety Support System Meldungen";
CM_ SG_ 1153 HMI_WLC1_Systemzustand_intern "ï?½bertragung der HMI Einstellung fï?½r den WLC1 Systemzustand";
CM_ SG_ 1153 HMI_WLC2_Systemzustand_intern "ï?½bertragung der HMI Einstellung fï?½r den WLC2 Systemzustand";
CM_ SG_ 1153 INF_Nachlaufzeit "signal from ICAS3 to ICAS1 to request a prolonged shutdown of HV";
CM_ SG_ 1153 MIB_ASW_Diagnose "Diagnose Rï?½ckmeldung vom MIB zu Heckradar Entry. ASW Warnton Verfï?½gbarkeit.";
CM_ SG_ 1153 MIB_Tongenerator_PH_verfuegbar "Verfï?½gbarkeit des Tongenerators im MIB fï?½r die Nutzung durch die Parkhilfe";
CM_ SG_ 1153 MMI_Counter_Bedienevent "Signal wird inkrementiert, wenn Bedienevent stattgefunden hat.";
CM_ SG_ 1153 MMI_Gurt_Mic_ref "Referenzsignal fï?½r das Gurtmikrofon Steuergerï?½t zur Signalisierung ob der Downlink aktiv oder inaktiv ist";
CM_ SG_ 1153 MMI_SDS_aktiv "Signal wird gesetzt, solange die Sprachbedienung aktiv ist.";
CM_ SG_ 1153 MU_SecondDisplay "Dient zur ï?½berwachung der zweiten LVDS Leitung.";
CM_ SG_ 1153 MU_Update_Time "Ermï?½glicht auslesen der Historiendaten, wann ein Update lief";
CM_ SG_ 1153 Nav_FoD_Status "FoD Status der Navigation";
CM_ SG_ 1153 ZR_AppConnect_Zustand "Ist Zustand des AppConnect Kontextes im MIB";
CM_ SG_ 1153 ZR_Kindersicherung_RSE "Sperren der Rearseat Unit (Komplette Weckfï?½higkeit)";
CM_ SG_ 1153 ZR_Lichter_Tag "Berechnete Kennzeichnung des Sonnenstandes ï?½ber bzw. oder unter Horizont.";
CM_ SG_ 1153 ZR_LoGeWa_Event_Kombiwarnung "Event fï?½r Kombiwarnung";
CM_ SG_ 1153 ZR_Parken_Sondermodus "Rï?½ckkanal zum pilotierten Parken zur Signalisierung Status Sondermodus";
CM_ SG_ 1153 ZR_RSE_aktivieren "Weckfï?½higkeit der RSE";
CM_ SG_ 1639 BFS_Fond_Bed_Ack "Bestï?½tigung Beifahrersitzverstellung vom Fond";
CM_ SG_ 1639 BFS_FSV_ausgeklappt "Zustandssignalisierung der el. mech. Fuï?½stï?½tze (eingeklappt oder ausgeklappt)";
CM_ SG_ 1639 BFS_GHV_aktiv "Verstellung Gurthoehe\n";
CM_ SG_ 1639 BFS_Gurtbringer_Sperre "Freigabesignal fï?½r den Gurtzubringer";
CM_ SG_ 1639 BFS_Klapptisch_offen "Signalisiert eine Verstelleinschrï?½nkung des Beifahrersitz  (fï?½r BAP Visualisierung)";
CM_ SG_ 1639 BFS_KSS_Fahrt_aktiv "Komfortseitensichtfahrt (BFS)";
CM_ SG_ 1639 BFS_KSV_aktiv "Kopfstuetzenverstellung BFS\n";
CM_ SG_ 1639 BFS_Lehne_nicht_verriegelt "Fahrer Sitz Lehne Verstellung Verriegelt Status\n\nVerwendung nur im  Bentley";
CM_ SG_ 1639 BFS_LHV_aktiv "Verstellung Lordose Hï?½he\n";
CM_ SG_ 1639 BFS_LKV_aktiv "Verstellung Lehnenkopf\n";
CM_ SG_ 1639 BFS_LNV_aktiv "Verstellung Lehnenneigung\n";
CM_ SG_ 1639 BFS_LWV_aktiv "Lordose W Verstellung\n";
CM_ SG_ 1639 BFS_MMB_glob_stop "Abbruch Memoryverstellung";
CM_ SG_ 1639 BFS_MMB_lokal_Stop "mit dem lokal Stop moechte man, dass ein Sitz mit Pneumatik - Lordose sich im Memoryfall wie ein Sitz mit elektromechanischer Lordose verhaelt. Nur lokler Abbruch im TIP-Betrieb.";
CM_ SG_ 1639 BFS_MMB_storage "Speichern auf Memoryposition";
CM_ SG_ 1639 BFS_MMB_storage_beep "Quittierungston Sitzmemory BFS (Anforderung Kombi)\n\n";
CM_ SG_ 1639 BFS_MMB_store "Speichern der Sitzposition\n";
CM_ SG_ 1639 BFS_MMB_store_LED_on "LED fï?½r Speichern\n";
CM_ SG_ 1639 BFS_MMB_tast "Memoryverstellung im Tastbetrieb";
CM_ SG_ 1639 BFS_MMB_tipp "Memoryverstellung im Tippbetrieb";
CM_ SG_ 1639 BFS_Ruhestellung_Status "dient der Signalisierung fï?½r eine Verstelleinschrï?½nkung, da der Sitz sich in Ruhestellung befindet.";
CM_ SG_ 1639 BFS_Seat_Locked "Anzeige des gesperrten Beifahrersitzes aufgrund ungï?½ltiger Sitzposition.";
CM_ SG_ 1639 BFS_SHV_aktiv "Sitzhï?½henverstellung\n";
CM_ SG_ 1639 BFS_Sitzfahrt_aktiv "Aktive Sitzfahrt";
CM_ SG_ 1639 BFS_Sitzsym_Fahrt_aktiv "Sitzsymetriefahrt\n";
CM_ SG_ 1639 BFS_SLV_aktiv "Sitzlï?½ngsverstellung\n";
CM_ SG_ 1639 BFS_SNV_aktiv "Verstellung Sitzneigung\n";
CM_ SG_ 1639 BFS_STV_aktiv "Sitztiefeverstellung\n";
CM_ SG_ 1178 FS_BFS_Fond_Verst_enable "Verstellung Fond (vom MMI)\n";
CM_ SG_ 1178 FS_BFS_KSS_Anfahrt "Komfortseitensicht Anfahrt BFS";
CM_ SG_ 1178 FS_BFS_Sitzsym_Anfahrt "Sitzsymetrie Anfahrt BFS";
CM_ SG_ 1178 FS_EE_BFS_enable "EasyEntry Freigabe fï?½r Befahrersitz.";
CM_ SG_ 1178 FS_EE_Fond_BFS_enable "EE Fond rechts\n\n";
CM_ SG_ 1178 FS_EE_Fond_FS_enable "EE Fond links\n";
CM_ SG_ 1178 FS_Fond_Bed_enable "Freigabe fï?½r Fondsitzverstellungen";
CM_ SG_ 1178 FS_GHV_aktiv "Verstellung Gurthï?½he\n";
CM_ SG_ 1178 FS_Gurtbringer_Sperre "Freigabesignal fï?½r den Gurtzubringer";
CM_ SG_ 1178 FS_KSV_aktiv "Verstellung Kopfstï?½tze\n";
CM_ SG_ 1178 FS_Lehne_nicht_verriegelt "Fahrer Sitz Lehne Verstellung Verriegelt Status\n\nVerwendung nur im Bentley";
CM_ SG_ 1178 FS_LHV_aktiv "Verstellung Lordose Hï?½he\n";
CM_ SG_ 1178 FS_LKV_aktiv "Verstellung Lehnenkopf\n";
CM_ SG_ 1178 FS_LNV_aktiv "Verstellung Lehnenneigung\n";
CM_ SG_ 1178 FS_LWV_aktiv "Verstellung Lordose W\n";
CM_ SG_ 1178 FS_MMB_glob_stop "Abbruch Memoryverstellung";
CM_ SG_ 1178 FS_MMB_lokal_Stop "mit dem lokal Stop moechte man, dass ein Sitz mit Pneumatik - Lordose sich im Memoryfall wie ein Sitz mit elektromechanischer Lordose verhaelt. Nur lokler Abbruch im TIP-Betrieb.";
CM_ SG_ 1178 FS_MMB_storage "Memory-Positionstaste, Funkschlï?½ssel-Memory-ID, Benutzerkonto-Nummer";
CM_ SG_ 1178 FS_MMB_storage_beep "Quittierungston Sitzmemory FS (Anforderung Kombi)";
CM_ SG_ 1178 FS_MMB_store "Memoryposition Speichern";
CM_ SG_ 1178 FS_MMB_store_LED_on "LED fï?½r Speichern\n";
CM_ SG_ 1178 FS_MMB_tast "Memoryverstellung im Tastbetrieb";
CM_ SG_ 1178 FS_MMB_tipp "Memoryverstellung im Tippbetrieb";
CM_ SG_ 1178 FS_SHV_aktiv "Verstellung Sitzhï?½he\n\n";
CM_ SG_ 1178 FS_Sitzfahrt_aktiv "Aktive Sitzfahrt Fahrersitz\n";
CM_ SG_ 1178 FS_SLV_aktiv "Sitzlï?½ngsverstellung\n";
CM_ SG_ 1178 FS_SNV_aktiv "Verstellung Sitzneigung\n";
CM_ SG_ 1178 FS_Spezialposition_anfahren "paralell zu diesem Signal wird eine Botschaft auf den KCAN gesendet in der spezielle Anforderungen fï?½r den Empfï?½nger stehen. \nDieses Signal dient zusï?½tzlich der Checksummenabsicherung bei einer Remotverstellung ";
CM_ SG_ 1178 FS_STV_aktiv "Verstellung Sitztiefe\n";
CM_ SG_ 1171 MF_Abzugssperre "Schlï?½sselabzugssperre";
CM_ SG_ 1171 MF_Alarm_Blinker "Taxialarmblinken, wie DWA ohne Fanfare";
CM_ SG_ 1171 MF_Alarm_Blinkertakt "Ansteuerung Blinker bei Alarm. Signal wird getaktet.\n0 = Blinker fï?½r Alarm aus\n1 = Blinker fï?½r Alarm ein";
CM_ SG_ 1171 MF_Anlassersperre "Notarzt 230V-Steckdose";
CM_ SG_ 1171 MF_Blk_li "Versehrte oder Fahrschule; Prio ï?½ber Fernbedienung ein";
CM_ SG_ 1171 MF_Blk_re "Versehrte oder Fahrschule; Prio ï?½ber Fernbedienung ein";
CM_ SG_ 1171 MF_BT_entriegeln "Beifahrertï?½r entriegeln";
CM_ SG_ 1171 MF_BT_verriegeln "Beifahrertï?½r verriegeln";
CM_ SG_ 1171 MF_Fahrlicht "statisch oder auch mit Blink_modi fï?½r interm.  Fahrlicht";
CM_ SG_ 1171 MF_Fernbed_ein "Fernbedienung fï?½r Petri+Lehr; Versehrte und Fahrschule";
CM_ SG_ 1171 MF_Fernlicht "Versehrte oder Fahrschule; Oder-Verknï?½pfung";
CM_ SG_ 1171 MF_FH_BT_hoch "Versehrte";
CM_ SG_ 1171 MF_FH_BT_tief "Versehrte";
CM_ SG_ 1171 MF_FH_FT_hoch "Versehrte";
CM_ SG_ 1171 MF_FH_FT_tief "Versehrte";
CM_ SG_ 1171 MF_Frontintervall "Versehrte oder Fahrschule; Oder-Verknï?½pfung";
CM_ SG_ 1171 MF_Frontwaschen "Versehrte oder Fahrschule; Oder-Verknï?½pfung";
CM_ SG_ 1171 MF_FT_entriegeln "Fahrertï?½r entriegeln";
CM_ SG_ 1171 MF_FT_verriegeln "Fahrertï?½r verriegeln";
CM_ SG_ 1171 MF_Fussraumbel "Fussraumbeleuchtung, Fahrschule";
CM_ SG_ 1171 MF_HBFS_entriegeln "Hinten Beifahrertï?½r entriegeln";
CM_ SG_ 1171 MF_HBFS_verriegeln "Hinten Beifahrertï?½r verriegeln";
CM_ SG_ 1171 MF_Heckintervall "Versehrte oder Fahrschule; Oder-Verknï?½pfung";
CM_ SG_ 1171 MF_Heckwaschen "Versehrte oder Fahrschule; Oder-Verknï?½pfung";
CM_ SG_ 1171 MF_HFS_entriegeln "Hinten Fahrertï?½r entriegeln";
CM_ SG_ 1171 MF_HFS_verriegeln "Hinten Fahrertï?½r verriegeln";
CM_ SG_ 1171 MF_Innenraumbel "sï?½mtliche Beleuchtungen akitivieren (Fussraum, Tï?½r u.a.)";
CM_ SG_ 1171 MF_Innenraumbel_Unterdrueck "Unterdrï?½ckung des Innenlichts/Fussraumbeleuchtung, sowie Schlieï?½blinken";
CM_ SG_ 1171 MF_interm_Fahrlicht "Ansteuerung intermittierendes Abblendlicht";
CM_ SG_ 1171 MF_interm_Fernlicht "mit Blink_modi fï?½r SoSi oder Taxialarm";
CM_ SG_ 1171 MF_interm_Takt "Taktung von intermittierenden Fernlicht/Fahrlicht bei einer Einsatzfahrt\n0 = Licht aus\n1 = Licht ein";
CM_ SG_ 1171 MF_Laderelais "Signal fï?½r die Auswertung zur Anzeige der Batterie-Schwach-Anzeige im Kombi";
CM_ SG_ 1171 MF_Lichthupe "Versehrte oder Fahrschule; Oder-Verknuepfung\n";
CM_ SG_ 1171 MF_Motorweiterlauf "Motorstop Behoerdenfahrzeug";
CM_ SG_ 1171 MF_nachtr_Stopp_Anf "Dieses Signal dient dem Motor als Trigger, dass ein nachtrï?½glicher Motorstopp eingeleitet werden kann, wenn es die Bedingungen des StSt Koordinators dies zulassen.";
CM_ SG_ 1171 MF_Notstart "Signal zeigt an, dass ein Notstart ï?½ber DBMC erfolgte.\n\nVerwendung in Verbindung mit Signal MF_Variante = DBMC.";
CM_ SG_ 1171 MF_Schluessel_scan "Anforderung eines Innenraumscans - Schlï?½sselsuche";
CM_ SG_ 1171 MF_Signalhorn "Versehrte, Fahrschule oder Taxi (bei Alarm)";
CM_ SG_ 1171 MF_Standlicht "statisch oder auch mit Blink_modi fï?½r Taxialarm";
CM_ SG_ 1171 MF_StartStopp_Info "Stopp-Freigabe und Start-Anforderung an den Start-Stopp-Koordinator";
CM_ SG_ 1171 MF_Summer "Warnsummer fï?½r Funkhauptschalter und Fahrschulpedal";
CM_ SG_ 1171 MF_TFL_Abschaltung "Abschaltung des Tagfahrlicht\n0 = keine Auswirkung\n1 = Tagfahrlicht deaktiviert";
CM_ SG_ 1171 MF_Tippwischen "Versehrte oder Fahrschule; Oder-Verknï?½pfung";
CM_ SG_ 1171 MF_Tuerentriegelung_hinten "Bei von innen verriegelten Fahrzeug Tï?½ren hinten entriegeln\n0 = keine Auswirkung\n1 = Tï?½ren hinten entriegeln\n";
CM_ SG_ 1171 MF_Variante "Sonderfahrzeugvariante\n0 = keine Sonderfunktion \n1 = Sondersignalfahrzeug\n2 = Taxi \n3 = Fahrhilfe \n4 = Fahrschule+Extra \n5 = SSF\n6 =  DBMC\n7 = Arbeitsmaschine";
CM_ SG_ 1171 MF_Warnblinker "Versehrte";
CM_ SG_ 1171 MF_Wischerstufe_1 "Versehrte oder Fahrschule; Oder-Verknï?½pfung";
CM_ SG_ 1171 MF_Wischerstufe_2 "Versehrte oder Fahrschule; Oder-Verknï?½pfung";
CM_ SG_ 1171 MF_ZV_Lock "Verriegelungsanforderung durch MFG analog Meldung einer Locktasterbetï?½tigung durch TSG.";
CM_ SG_ 1171 MFG_01_BZ "4bit Botschaftszï?½hler, wird in jeder Sendebotschaft inkrementiert\n";
CM_ SG_ 1171 MFG_01_CRC "Fï?½r MLB:\n'Berechnung siehe Lastenheft 'Kommunikationsabsicherung fï?½r FlexRay und CAN''\n\nAb MQB und MLBevo:\n'Berechnung siehe Lastenheft 'End-to-End Kommunikationsabsicherung''\n\nEndwerte siehe Begleitdokument 'S-PDU Kennungsfolgen'";
CM_ SG_ 1164 MF_2BatSOCzugering "Anzeige bei geringer Ladung der Zweitbatterie";
CM_ SG_ 1164 MF_2BattAb "Batterie Ab Warnung der Zweitbatterie";
CM_ SG_ 1164 MF_2BattHlkAnf "Anforderung einer HLK - Stufe an das BEM";
CM_ SG_ 1164 MF_2BattLadWarn "Anzeige das bei Motorlauf die Zweitbatterie entladen wird im KI";
CM_ SG_ 1164 MF_2BattLlaAnf "Anforderung einer Drehzahlanhebung an das BEM";
CM_ SG_ 1164 MF_2BattSpannungsAnf "Mindestspannugnsanforderung der Zusatbatterie an den BEM";
CM_ SG_ 1164 MF_Batteriediagnose "Erstellt fï?½r Zusatzbatterie Crafter";
CM_ SG_ 1164 MF_Blinker_L_Sta "Status Blinker links Sonderaufbauten";
CM_ SG_ 1164 MF_Blinker_R_Sta "Status Blinker rechts Sonderaufbauten";
CM_ SG_ 1164 MF_ExterneLadungWarn "Warnung bei Motorlauf das externer Ladestecker gesteckt ist im KI";
CM_ SG_ 1164 MF_Fahrerhinweis "Fahrerhinweis Kombiinstrument";
CM_ SG_ 1164 MF_Generatordiagnose "Neu erstellt fï?½r Crafter";
CM_ SG_ 1164 MF_Heck_entriegeln "Entriegelung Heck ï?½ber KFG";
CM_ SG_ 1164 MF_Heck_verriegeln "Verriegelung Heck ï?½ber KFG";
CM_ SG_ 1164 MF_interm_Nebelscheinwerfer "Intermittierender Nebelscheinwerfer bei einer Einsatzfahrt";
CM_ SG_ 1164 MF_Lampenausfall "Meldung Lampenausfall Aufbauhersteller";
CM_ SG_ 1164 MF_LSH_Abschaltstufe "Abschaltstufen der Luftstandheizung an der Zweitbatterie. Das Signal dient der Steuerung des Klima SG an der ersten Batterie und der LSH an der zweiten Batterie durch das Zweitbatterie Em im KFG";
CM_ SG_ 1164 MF_LSH_Einschaltverbot "Statussignal fï?½r das Einschaltverbot der Luftstandheizung an der Zweitbatterie, Steuerung durch das Zweitbatterie EM im KFG.\n0 volle Verfuegbarkeit Standheizung/-lueftung\n1 Standheizung/-lueftung nicht aktivierbar";
CM_ SG_ 1164 MF_LSH_Zielzeit "Definition der Zielzeit fï?½r die Luftstandheizung an der zweiten Batterie, Steuerung durch das Zweitbatterie EM im KFG.";
CM_ SG_ 1164 MF_NotStartAktiv "Anzeige Notstart Aktiv fï?½r den Zeitraum der Schlieï?½ung des Notstartrelais";
CM_ SG_ 1164 MF_Radiomute "Wird bei Sonderfahrzeugen wie Polizei dafï?½r verwendet, um das Radio bei einem eingehenden Funkspruch zu muten.";
CM_ SG_ 1164 MF_Relais_2_Batterie "Zeigt den Zustand des vom KFG angesteuerten Laderelais einer verbauten 2. Batterie an";
CM_ SG_ 1164 MF_Tuerverriegelung_hinten "Internes Verriegeln der hinteren Tï?½ren";
CM_ SG_ 1164 MF_ZV_Unlock "Globales entriegeln ï?½ber KFG";
CM_ SG_ 1164 MFG_AppConnect_Anf "AppConnect Anforderung durch das KFG";
CM_ SG_ 1164 MFG_Klappe_Status "Einstellung der Luftklappenposition an der Luftstandheizung";
CM_ SG_ 817 MFL_ECU_Err "MFL-ï?½C Fehler";
CM_ SG_ 817 MFL_Eventcode_1 "Siehe Q-LAH MFL-Protokoll";
CM_ SG_ 817 MFL_Eventcode_2 "Siehe Q-LAH MFL-Protokoll";
CM_ SG_ 817 MFL_Fehler_Codierung "Erkennung dass MFL nicht codiert ist.";
CM_ SG_ 817 MFL_Lokalaktiv "Zeigt an ob das SG nach Klemme15 AUS und nach entsprechender MAX Aktivzeit noch aktiv war";
CM_ SG_ 817 MFL_LR_HZG_Err "Lenkradheizung Fehler";
CM_ SG_ 817 MFL_LR_HZG_Status "Status Lenkradheizung";
CM_ SG_ 817 MFL_M_Taste "Taster fï?½r Umschaltung Automatik/manuelles Schalten (Tiptronic)";
CM_ SG_ 817 MFL_Marke "Marke fï?½r markenspezifische Variantennummer des MFL";
CM_ SG_ 817 MFL_Paddle_Verbau "Signalisiert den Zustand des Tipp-Paddle-Verbaus";
CM_ SG_ 817 MFL_Response_Err "siehe LIN2.0-Specification\n(Darf nicht ï?½ber ein Fehlergueltigkeitsbit abgesichtert werden!)";
CM_ SG_ 817 MFL_SatModul_links_Err "Schalter Tastermodul links Fehler";
CM_ SG_ 817 MFL_SatModul_rechts_Err "Schalter Tastermodul rechts Fehler";
CM_ SG_ 817 MFL_Signalhorn "Signalhorn nicht betaetigt/betaetigt";
CM_ SG_ 817 MFL_Signalhorn_Err "Signalhorn Fehler";
CM_ SG_ 817 MFL_Taste_links_Err "MFL_Tastenblock links Fehler";
CM_ SG_ 817 MFL_Taste_rechts_Err "MFL_Tastenblock rechts Fehler";
CM_ SG_ 817 MFL_Tastencode_1 "Beschreibt die Funktion einer fest zugeordneten Taste/Walze auf dem MFL. Bei Betï?½tigung ï?½ndert sich der Wert von 0x0 auf den jeweiligen Tastencode.";
CM_ SG_ 817 MFL_Tastencode_2 "Beschreibt die Funktion einer fest zugeordneten Taste/Walze auf dem MFL. Ist MFL_Tastencode_1 wegen Betï?½tigung einer Taste/Walze bereits mit einem Wert ungleich 0x0 belegt, so ï?½ndert sich bei Betï?½tigung einer weiteren Taste/Walze der Wert dieses Signals v";
CM_ SG_ 817 MFL_Tip_Down "MFL-Tiptronic Tasten vom MFL fï?½r Getriebe\n0x0 = kein Tip_Down\n0x1 = Tip_Down";
CM_ SG_ 817 MFL_Tip_links_Err "Tiptronic links Fehler";
CM_ SG_ 817 MFL_Tip_rechts_Err "Tiptronic rechts Fehler";
CM_ SG_ 817 MFL_Tip_Up "MFL-Tiptronic Tasten vom MFL fï?½r Getriebe\n0x0 = kein Tip_Up\n0x1 = Tip_Up";
CM_ SG_ 817 MFL_Toggle "Watchdog Toggle-Bit";
CM_ SG_ 817 MFL_Variante "Markenspezifische Variantennummer des MFL";
CM_ SG_ 560 MFL_Beruehrungserkennung "Das Signal beschreibt die Berï?½hrung der Bedieninseln des Touch-MFL (nicht berï?½hrt = Init, links, rechts oder beidseitig).";
CM_ SG_ 560 MFL_Touch_Event "Touch_Events fï?½r Informationen einer Funktionsauslï?½sung auf dem MFL, welches dann fï?½r bspw. ein akustisches Signal zentral umgesetzt werden kï?½nnen.";
CM_ SG_ 2463978751 MFL_Taste_SDS_benoetigt "Taste beleuchtet, Tastencode wird gesendet";
CM_ SG_ 2463978751 MFL_Tasten_UpDownOK_benoetigt "Taste beleuchtet, Tastencodes werden gesendet";
CM_ SG_ 2463978751 MFL_Tasten_Volume_benoetigt "Taste beleuchtet, Tastencodes werden gesendet";
CM_ SG_ 2463978751 MFL_Vibrationsimpuls_links "Fï?½r haptisches Feedback zur Bedienung der MFL-Tasteninsel.\nWird zyklisch abgespielt, solange Signal anliegt. Die Zeit bis zu den nï?½chsten vollen 100ms ist im MFL mit Pause gespeichert. Ist die Impulsanforderung kï?½rzer als die Lï?½nge des Impulses, wird der";
CM_ SG_ 2463978751 MFL_Vibrationsimpuls_rechts "Als haptisches Feedback zur Bedienung der MFL-Tasteninsel.\nWird zyklisch abgespielt, solange Signal anliegt. Die Zeit bis zu den nï?½chsten vollen 100ms ist im MFL mit Pause gespeichert. Ist die Impulsanforderung kï?½rzer als die Lï?½nge des Impulses, wird der";
CM_ SG_ 1471 MFL_Eventcode_1 "Siehe Q-LAH MFL-Protokoll";
CM_ SG_ 1471 MFL_Eventcode_2 "Siehe Q-LAH MFL-Protokoll";
CM_ SG_ 1471 MFL_Marke "Marke fï?½r markenspezifische Variantennummer des MFL";
CM_ SG_ 1471 MFL_Tastencode_1 "Beschreibt die Funktion einer fest zugeordneten Taste/Walze auf dem MFL. Bei Betï?½tigung ï?½ndert sich der Wert von 0x0 auf den jeweiligen Tastencode.";
CM_ SG_ 1471 MFL_Tastencode_2 "Beschreibt die Funktion einer fest zugeordneten Taste/Walze auf dem MFL. Ist MFL_Tastencode_1 wegen Betï?½tigung einer Taste/Walze bereits mit einem Wert ungleich 0x0 belegt, so ï?½ndert sich bei Betï?½tigung einer weiteren Taste/Walze der Wert dieses Signals v";
CM_ SG_ 1471 MFL_Variante "Markenspezifische Variantennummer des MFL";
CM_ SG_ 958 MO_Aussp_Anlass "Das Signal zeigt an, ob die Wiederholstartsperre aktiv ist. D. h. eine Ansteuerung des Anlassers wird auch bei erfï?½llten Startvoraussetzungen (HS: Interlock betï?½tigt bzw. AT: P/N eingelegt und Bremse betï?½tigt) nicht erfolgen.";
CM_ SG_ 958 MO_BKV_Unterdruckwarnung "ï?½ber die Unterdruckwarnung signalisiert das MSG dem ESP, dass kein ausreichender Unterdruck fï?½r den BKV zur Verfï?½gung gestellt werden kann.";
CM_ SG_ 958 MO_BLS "Ungefiltertes Rohsignal des Bremslichtschalters, nur wenn HW-Eingang bestï?½ckt und ausgewertet wird. Bei Motoren ohne genutzten HW-Eingang wird kein Ersatzwert (bspw. SW-Signal ï?½ber CAN) ausgegeben!\nBei AUDI muss das Signal wg. Bremslichtfunktion immer be";
CM_ SG_ 958 MO_BMS_NV_Anf_stuetzen "Garantierte Unterstï?½tzung des Zusatzspeichers ist erforderlich. Zusatzspeicher muss an das Versorgungsnezt angebunden werden. ";
CM_ SG_ 958 MO_EKlKomLeiRed "Anforderung an die Klimasteuerung, die Leistungsaufnahme des E-Kompressors bei schlechtem SOC und in bestimmten Fahrsituationen zu begrenzen. (Das bereits bestehende Signal 'Klimakompressor aus' als stets umzusetzende Anforderung bleibt unverï?½ndert besteh";
CM_ SG_ 958 MO_Ext_E_Fahrt_aktiv "Funktionsrï?½ckmeldung zum erw. E-Fahr-Betrieb ï?½ber Lampe/LED im E-Mode-Taster";
CM_ SG_ 958 MO_Fahrer_bremst "Redundante Bremsinformation vom Motor.\n\nMLB:\nAUDI D4: Zykluszeit: 10ms (siehe Zykluszeit schnell/Cycletime Fast)\nIm AUDI B8 wird in diesem Bit der Wert der ESP-CAN-Information 'ESP_Fahrer_bremst' ausgegeben.\n\nAchtung:\nReduktion der Zykluszeit Motor";
CM_ SG_ 958 MO_FMAus_aktiv "Das Signal gibt Rï?½ckmeldung ob Freilauf Motor aus aktiv ist. Beleibt auch 0km/h (unterhalb der StartStopp Schwelle) weiterhin aktiv.";
CM_ SG_ 958 MO_FMAus_Startvariante "Startvariante beim Motorstart aus der Freilauf-Motor-AUS Phase";
CM_ SG_ 958 MO_Freig_Anlass "Bit wird gesetzt, wenn der Motor beim Automatikstart gestartet werden darf (Motorstillstand, Emissionsmaï?½nahmen sind erfï?½llt).";
CM_ SG_ 958 MO_Freig_Reku "Empfehlung des Motor-SG's zur Spannungsabsenkung/-anhebung fï?½r den Rekuperationsbetrieb";
CM_ SG_ 958 MO_Freigabe_Segeln "Freigabebit des Segelbetriebs im Getriebe. Bedingt durch bestimmte Diagnosen und Adaptionen des MSGs, die nur im Schub mï?½glich sind, darf nicht jede Schubphase fï?½r einen Segelbetrieb genutzt werden. Eine Freigabe bleibt auch auï?½erhalb einer Schubphase bes";
CM_ SG_ 958 MO_Gangposition "MLB:\nStellung des Wï?½hlhebels in der Schaltgasse des Handschaltgetriebes.\nMLBevo: \nAusweitung der Bedienung auch auf Automatikgetriebe;\nRouting des Signals GE_Fahrstufe: \n1. Position_R (dez. 6) auf MO_Gangposition: Gang_R (dez. 13) wegen Entfall Signa";
CM_ SG_ 958 MO_Handshake_STH "Es gilt: Signalspec MO_Handshake v1.0\n\nHandshake zwischen MSG und STH. Wenn das MSG die EKP aufgrund einer STH-Anforderung ansteuert und kein Fehlereintrag bzgl. EKP/KPE/NDR vorliegt, wird das Bit gesetzt.";
CM_ SG_ 958 MO_HYB_Fahrbereitschaft "Signal steuert u.a. in der Lenkhilfe zusammen mit weiteren Informationen den Modewechsel in den 'Drivemode'\nGrï?½ne Anzeige im Kombiinstrument zur Signalisierung der Bereitschaft des Hybridsystems.";
CM_ SG_ 958 MO_HYB_VM_aktiv "0 = VMotor wird nicht aktiv gehalten (nVM < n_min und keine LL-Regelung aktiv)\n1 = VMotor aktiv (ab der ersten Einspritzung; gilt auch fï?½r Schubbetrieb, wenn VMotor spï?½testens durch LLRegelung befeuert wï?½rde)\nVerwendet zur Bestimmung des Ist-Zustandes";
CM_ SG_ 958 MO_Interlock "Das Motorsteuergerï?½t gibt die Information aus, ab wann der Kupplungsschalter durch das Motorsteuergerï?½t als getreten gesehen wird.\nBei Systemen fï?½r Start Stopp muss das Interlocksignal fï?½r einen Start durch das MSG generiert werden, sobald der Schalthebe";
CM_ SG_ 958 MO_Kickdown "Es gilt: Signalspec MO_Kickdown v1.0";
CM_ SG_ 958 MO_Kl_50 "Klemme 50: Startausfï?½hrung durch Ritzelstarter\n\nMLB: nicht von allen Motoren gesendet\nMQB/MLBevo: gesendet von allen Motoren";
CM_ SG_ 958 MO_Kl_75 "Klemme X\n";
CM_ SG_ 958 MO_Klima_Eingr "Eingriffe des Motor bei der Klima";
CM_ SG_ 958 MO_Konsistenz_Bremsped "MLB:\n\nAUDI D4: Zykluszeit: 10ms (siehe Zykluszeit schnell/Cycletime Fast)\nSiehe 'Funktionsspezifikation Bremslichtinfo B8'\n\nAchtung:\nReduktion der Zykluszeit Motor_03 auf 10ms geplant.\nProjektabhï?½ngig soll kï?½nftig mit 10ms gesendet werden.\nEmpfï?½ng";
CM_ SG_ 958 MO_Kuppl_schalter "MLB:\nDas Motorsteuergerï?½t gibt die Information aus, ab wann der Kupplungsschalter durch das Motorsteuergerï?½t als getreten gesehen wird\n0x0: Schalter sagt betï?½tigt (Ausgekuppelt)\n0x1: Schalter sagt nicht betï?½tigt (Eingekuppelt)\n\nMQB:\nNur Handschalter";
CM_ SG_ 958 MO_Motor_laeuft "Das Motorsteuergerï?½t gibt die Information aus, ab wann der Motor verbrennungsbedingt autark lï?½uft und durch zuschaltbare Nebenaggregate mechanisch belastbar ist (z.B. durch Generator, Klimakompressor, etc.).\n\nDie 'Motor lï?½uft' Information wird ausgegebe";
CM_ SG_ 958 MO_PTC_Status "Status-Rï?½ckmeldung vom MSG zum aktuellen PTC-Status (stufiges PTC, Relais am MSG). Bei Ansteuerung eines stufigen PTC durch ein anderes SG beschreibt das Signal die vom MSG freigegebene PTC-Stufe.";
CM_ SG_ 958 MO_QBit_Fahrer_bremst "MLB:\nAUDI D4: Zykluszeit: 10ms (siehe Zykluszeit schnell/Cycletime Fast)\n\nAchtung:\nReduktion der Zykluszeit Motor_03 auf 10ms geplant.\nProjektabhï?½ngig soll kï?½nftig mit 10ms gesendet werden.\nEmpfï?½nger die in weiteren Konzern-Projekten eingesetzt werd";
CM_ SG_ 958 MO_QBit_Gangposition "Qualitï?½tsbit zum Signal MO_Gangposition";
CM_ SG_ 958 MO_QBit_KL_75 "Q - Bit fï?½r das KL 75 Signal zur Vermeidung der fehlerhaften Erkennung von Motorstarts. \nWird auf 1 gesetzt, solange das Motorsteuergerï?½t KL15 = AUS erkannt hat.";
CM_ SG_ 958 MO_Remotestart_Betrieb "Das MSG ist fï?½r den Remotestart-Betrieb bereit. Nach Empfang der Motorstartanforderung fï?½r RSt-Betrieb durch BCM wird der Fahrzeugmotor gestartet und solange der Motor lï?½uft, bleibt dieses Bit aktiv. Dieses Signal ist nur zur Verwendung durch das BCM zur ";
CM_ SG_ 958 MO_Remotestart_moeglich "Wenn Bit gesetzt, wï?½rde das MSG bei entsprechender Anforderung durch das BCM den Remotestartbetrieb einleiten, d.h. das MSG ist remotestartfï?½hig und es liegen aktuell keine relevanten Fehler oder andere Abbruchgrï?½nde vor.";
CM_ SG_ 958 MO_Signalquelle_Gangposition "Signalquelle des Signals MO_Gangposition\n0: Signalquelle Gangpositionssensor\n1: Signalquelle Modellwert (v/n)";
CM_ SG_ 958 MO_StartStopp_Fahrerwunsch "Fahreraktivitï?½t Start/Stop";
CM_ SG_ 958 MO_StartStopp_Motorstopp "Motor-Stopp durch Start/Stopp-Koordinator\nHYBRID:\nWenn MO_Hybridfahrzeug = 1 gilt:\nVerbrennungsmotor durch Hybrid-Koordinator im MSG ausgeschaltet. \nDie definierten Start/Stopp-Signale beziehen sich nur auf den Verbrennungsmotor!";
CM_ SG_ 958 MO_StartStopp_Status "Aktivitï?½tsstatus Start/Stopp-Koordinator\nHYBRID:\nWenn MO_Hybridfahrzeug = 1 gilt:\nSignal bezieht sich nur auf den Verbrennungsmotor, nicht auf den Hybridantrieb\n";
CM_ SG_ 958 MO_StartStopp_Wiederstart "Motorwiederstart durch Start/Stopp-Koordinator\nHYBRID:\nWenn MO_Hybridfahrzeug =1 gilt:\nWarnung vor Spannungseinbruch beim Zustart des Verbrennungsmotors. \n-nicht relevant, da derzeit kein Start ï?½ber 12V-Starter geplant-\nDieses Signal wird nur vom Hyb";
CM_ SG_ 958 MO_StartVorauss_erfuellt "Dient der Fallunterscheidung bei ZAT-Betï?½tigung im Zustand 'KL15 ein' (bei nicht gesetztem Signal folgt KL15 aus, bei gesetztem Signal folgt setzen KL50-Anf.)\n\n0: Signal nicht bedient \n1: Voraussetzungen zur Antriebsstrangaktivierung / Startvoraussetzu";
CM_ SG_ 958 MO_Timeout_ESP "500 ms Timeout auf Bremsen-Botschaft ist >= 1 mal aufgelaufen, Lï?½schen des Bits nach Neustart (KL15).\n\nMLB:\nAUDI D4: Zykluszeit: 10ms (siehe Zykluszeit schnell/Cycletime Fast)\n\nAchtung:\nReduktion der Zykluszeit Motor_03 auf 10ms geplant.\nProjektabh";
CM_ SG_ 958 MO_Zylinderabschaltung "Status Zylinderabschaltung Motor";
CM_ SG_ 958 Motor_14_CRC "Ab MQB und MLBevo:\n'Berechnung siehe Lastenheft 'End-to-End Kommunikationsabsicherung'\n\nEndwerte siehe Begleitdokument 'S-PDU Kennungsfolgen'";
CM_ SG_ 1648 MO1_Freigabe_Info_WFS "WFS-Freigabeinformation";
CM_ SG_ 1648 MO1_Freigabe_Verfallsinfo_WFS "WFS-Freigabeverfallsinformation";
CM_ SG_ 1648 MO1_Sperr_Info_WFS "WFS-Sperrinformation";
CM_ SG_ 1648 MO_Abstellzeit "Abstelldauer nach letztem KL15 aus\n\nHinweis: \nEhemaliger Fehlerwert 0xFF wird senderseitig nicht unterstï?½tzt. \nDiesen Wert aus Kompatibilitï?½tsgrï?½nden nicht neu belegen!";
CM_ SG_ 1648 MO_Abstellzeit_Status "Statusinformation zur Abstellzeit\n0: Die dem Status zugeordnete Variable konnte noch nicht berechnet werden. \n1: Die dem Status zugehï?½rige Variable wurde korrekt berechnet. \n2: Der Wert der zugehï?½rigen Variablen ist nur ein Minimalwert. \n3: Der Wert d";
CM_ SG_ 1648 MO_ANC_Kennfeld_Anf "Anforderung ANC Kennfeldumschaltung";
CM_ SG_ 1648 MO_Anzahl_Abgesch_Zyl "Gibt die Anzahl der abgeschalteten Zylinder an. In ï?½bergangszustï?½nden wird der Zielbetriebszustand angezeigt.";
CM_ SG_ 1648 MO_Bremslicht_Reku "Bremslicht (ggf. bei Rekuperation durch E-Motor) wird angesteuert";
CM_ SG_ 1648 MO_Drehzahl_Warnung "Warnhinweis zum Kombi im Fall einer fehlerbehafteten Drehzahlbegrenzung";
CM_ SG_ 1648 MO_EPCL "Die Anforderung der EPC-Lampe vom MSG ans Kombi soll durch das Bus-Signal MO_EPCL gemï?½ï?½ folgender Logik erfolgen:\nMO_EPCL = 0 dez -> EPC Lampe aus, kein Text\nMO_EPCL = 1 dez -> gelbe EPC-Symbolik, Text ï?½Antrieb: Stï?½rung! Bitte Service aufsuchenï?½\nMO_EPC";
CM_ SG_ 1648 MO_Ethanol_BS_Texte "Ethanol Brennstoff-Texte im Kombi\n\n0 = kein Text\n1 = E85 Warm_Up\n2 = FlexFuel Warnung 3.Stufe (Too cold for ethanol)\n3 = Warmfahrempfehlung MQB / FlexFuel Warnung 1.Stufe (Refuel with gasoline)\n4 = FlexFuel Warnung 2. Stufe (Refuel with gasoline)\n5";
CM_ SG_ 1648 MO_Fahrzeugtyp "Unterscheidet die Fahrzeugtypen bzgl. der Antriebsart";
CM_ SG_ 1648 MO_Fehler_Zylabsch "Fehlerstatus der Funktion Zylinderabschaltung ";
CM_ SG_ 1648 MO_Hybrid_StartStopp_LED "Ansteuerung der Funktions-LED der Hybrid Taste bzw. Start/Stop Deaktivierungstaste.\nDer Start/Stopp-Master (derzeit im MSG) (oder ein kï?½nftiger Hybrid-Master) soll die Ansteuerung senden.";
CM_ SG_ 1648 MO_max_Ladedruck "maximal mï?½glicher Ladedruck (zur Anpassung des Anzeigebereichs bei absoluter Ladedruckanzeige)";
CM_ SG_ 1648 MO_NMAX_Schaltanzeige "Maximaldrehzahl fï?½r Schaltanzeige";
CM_ SG_ 1648 MO_obere_Drehzahlgrenze "obere Drehzahlgrenze des Motors";
CM_ SG_ 1648 MO_StartStopp_PopUp "Das Signal zeigt an, ob der StSt-Status mittels Deaktivierungstaster geï?½ndert wurde. Ein Wechsel auf die Werte 01 oder 10 lï?½st im Kombi ein entsprechendes PopUp aus. Bei einem Statuswechsel durch andere Signalquellen (z.B. Charisma, fehlerbedingte Abschal";
CM_ SG_ 1648 MO_Zylabsch_Texte "Zylinderabschaltung mode in Kombi, fuer Zylinderabschaltung";
CM_ SG_ 1648 MO_Zylabsch_Texte_02 "ZAS-Anzeige fï?½r den Fahrer im Kombi\n0: kein ZAS (generell keinerlei ZAS-Anzeigen)  (Init fï?½r nicht ZAS-Motor)\n1: ZAS im Vollmotorbetrieb  (Init fï?½r ZAS-Motor)\n2: ZAS im Abschaltbetrieb: 1 Zyl aktiv\n3: ZAS im Abschaltbetrieb: 2 Zyl aktiv\n4: ZAS im Abs";
CM_ SG_ 967 MO_E_Mode "Anforderung der E-Mode Statusanzeige";
CM_ SG_ 967 MO_E_Texte "Anforderung von Hinweistexten des E-Systems separat fï?½r HEV/BEV bzw. erweiterbar fï?½r PHEV";
CM_ SG_ 967 MO_E_Warnungen "Anforderung von Warnanzeigen des E-Systems separat fï?½r HEV/BEV bzw. erweiterbar fï?½r PHEV";
CM_ SG_ 967 MO_EFLEX_Lampe "Um ein Starten mit E100 zu ermï?½glichen, wird Kraftstoff ggf. vorgeheizt. Das Signal dient der Anzeige des Heizungsstatus.\n\nHeizung aus -> Lampe aus\nHeizung ein -> Lampe ein\nHeizung ein und Startversuch -> Lampe blinkend\nHeizung nicht mï?½glich -> Lampe";
CM_ SG_ 967 MO_Heissleuchte "Ansteuerung der Kï?½hlwassertemperatur-Heiï?½leuchte (Sensor nur noch am Motorsteuergerï?½t): Temperaturschaltschwellen mit Hysterese (bei VW D1/Colorado Kombi derzeit noch nicht genutzt).";
CM_ SG_ 967 MO_ITM_Warnung_Pumpe "Textanzeige: 'Motor sofort abstellen, geschaltete Wasserpumpe defekt / klemmt'";
CM_ SG_ 967 MO_KJS_nicht_bereit "Dieses Signal zeigen einen Fehler der Kï?½hlerjalousie mit unbekannter Stellung der Lamellen. ";
CM_ SG_ 967 MO_Kuehlerluefter_1 "Ansteuertastverhaeltnis (PWM) der Kuehlerluefterendstufe 1";
CM_ SG_ 967 MO_Kuehlerluefter_2 "Ansteuertastverhaeltnis (PWM) der Kuehlerluefterendstufe 2";
CM_ SG_ 967 MO_Kuehlerluefter_MUX "Multiplexer fï?½r das Signal 'MO_Kuehlerlï?½fter'";
CM_ SG_ 967 MO_OBD2_Lampe "OBD bzw. MIL-Lampe wird vom Motorsteuergerï?½t angesteuert, die Information im Signal GE_OBD_Status wird vom Motorsteuergerï?½t an das Kombi weitergereicht";
CM_ SG_ 967 MO_Oelwarnung_max "ï?½lstandswarnung mit der Aufforderung zum ï?½lwechsel.\nHintergrund: Bei Kraftstoffeintrag (B20) ins ï?½l verbleibt der RME-Anteil irreversibel im ï?½l.";
CM_ SG_ 967 MO_Partikel_Lampe "Partikelfilter-Lampe wird eingeschaltet";
CM_ SG_ 967 MO_RedFahrleistung_Lampe "Ansteuerung der Turtle-Mode Lampe fï?½r E-Traktion Fahrzeuge";
CM_ SG_ 967 MO_Systemlampe "EGas Systemlampe (EPC) oder Vorglï?½hlampe im Kombi, Kombi steuert immer gleiche\nLED an, nur ï?½ber Ziffernblatt wird die EPC von der Vorglï?½hlampe differenziert";
CM_ SG_ 967 MO_Tankdeckel_Lampe "Ansteuerung Tankdeckel-Warnlampe Kombiinstrument (nur Ottomotoren) z.Zt. Vorhalt VW";
CM_ SG_ 967 MO_Text_Motorstart "Anzeigetexte fï?½r Start/Stopp und Motor-Start\n0xB Fehler_Kupplungsschalter nur fï?½r PAG-MLB";
CM_ SG_ 967 MO_Text_Partikelfil_Reg "ï?½ber dieses Bit im Kombi wird ein Klartextanzeige erzeugt werden: 'Partikelfilter benï?½tigt Regeneration'.\n";
CM_ SG_ 967 MO_Text_Tankdeckelwarn "Textbit der Tankdeckelwarnung, z.Zt. Vorhalt VW";
CM_ SG_ 967 MO_Vorglueh_Lampe "Vorglï?½hlampe im Kombi, Kombi steuert immer gleiche LED an. \nMit Einfï?½hrung des Einheits-Kombis sind getrennte Signalwege fï?½r Vorglï?½hlampe und EPCL notwendig.";
CM_ SG_ 967 MO_Zustand_HWP "Rï?½ckmeldung des  Ansteuerzustand der Hauptwasserpumpe an das Klima-SG .\nDer Zustand 'HWP fï?½rdert' wird ï?½bermittelt, wenn die Schaufeln der Hauptwasserpumpe frei drehen kï?½nnen und die Motordrehzahl und damit die Wasserpumpendrehzahl grï?½ï?½er als Null ist. B";
CM_ SG_ 967 OLEV_Oelstand_nicht_vorhanden "Kein aktueller ï?½lstand vorhanden";
CM_ SG_ 967 OLEV_Systemstoerung "Systemstï?½rung im ï?½lsystem";
CM_ SG_ 967 WIV_Anzeige_aktiv "Peilstabsanzeigefunktion aktiv";
CM_ SG_ 967 WIV_laufender_Motor "Messung bei laufendem Motor nicht mï?½glich";
CM_ SG_ 967 WIV_nachfuellanzeige_ein "Steuert das Aufblenden der Nachfï?½llanzeige im Kombi, nach Klemme 15 ein und geï?½ffneter Motorhaube";
CM_ SG_ 967 WIV_nicht_betriebswarm "Motor nicht betriebswarm, Messung ungenau";
CM_ SG_ 967 WIV_Oeldr_Warn_Motor "Lï?½st im Kombiinstrument die rote Prio1-ï?½ldruckwarnung (inkl. 3xBeep) aus.\nnur MLB: die Warnauslï?½sung erfolgt nur bei gleichzeitig gesetztem 'WIV_Enable_Oeldr_Motor'";
CM_ SG_ 967 WIV_Oeldyn_avl "ï?½lstand aus dynamischer Messung vorhanden";
CM_ SG_ 967 WIV_Oelmenge "ï?½lmenge zwischen Min und Max";
CM_ SG_ 967 WIV_Oelmin_Warn "Signal gibt an wenn der ï?½lstand die Min-Schwelle unterschritten hat";
CM_ SG_ 967 WIV_Oelstand "8 Segmente zur Balkenanzeige des ï?½lstands";
CM_ SG_ 967 WIV_Oelstand_nicht_vorhanden "Kein aktueller ï?½lstand vorhanden";
CM_ SG_ 967 WIV_Oelsystem_aktiv "Gesamtï?½lsystem aktiv (entspricht ï?½lsensor verbaut) und das ï?½lstand-Untermenu im MMI aktiv";
CM_ SG_ 967 WIV_Schieflage "Fahrzeug steht nicht waagerecht, Messung ungenau";
CM_ SG_ 967 WIV_Sensorfehler "ï?½lstand/ï?½ltemperatursensor (TOG) defekt";
CM_ SG_ 967 WIV_Ueberfuell_deaktiv "Unterdrï?½ckung der Warnung im Kombi die durch Signal WIV_Ueberfuel_Warn ausgelï?½st wird";
CM_ SG_ 967 WIV_Ueberfuell_Warn "ï?½lstand hat die ï?½berfï?½llschwelle ï?½berschritten";
CM_ SG_ 967 WIV_Unterfuell_Warn "ï?½lstand hat die Unterfï?½llschwelle unterschritten";
CM_ SG_ 966 SOK_Motor_26_Signatur "Signatur im Rahmen der durch SOK geschï?½tzten Broadcast-Kommunikation\n\nGeschï?½tzte Funktion: ORU\nGeschï?½tzte Botschaft: Motor_26";
CM_ SG_ 706 FDR_Warnung_ALR "Warnmeldungen der Allradverteilung";
CM_ SG_ 706 MO_ADR_Status "Status der Arbeitsdrehzahlregelung";
CM_ SG_ 706 MO_AGA_Sound_Texte "Textausgabe des aktuellen Sound-Zustandes der Abgasklappensteuerung";
CM_ SG_ 706 MO_Anz_Kuehlerluefter "Signal bei aktivem Kï?½hlerlï?½fternachlauf (Motor aus) im Allgemeinen fï?½r die Anzeige im Kombi-Instument zur Information des Kunden ï?½ber diesen Lï?½fterlauf";
CM_ SG_ 706 MO_Anzeige_FMAus_Text "Fehlerstatus des FMAus-Systems (z.B. Fehler im Zusatzspeicher)";
CM_ SG_ 706 MO_Anzeige_StSt_Symbol "Steuert die Anzeige der StSt-Symbolik im Kombi";
CM_ SG_ 706 MO_Anzeige_StSt_Text "Steuert die Anzeige der StSt-Texte im Kombi";
CM_ SG_ 706 MO_ElAntrieb_Abschleppwarnung "Warnung, wenn ein Mitschleppen der jeweils bezeichneten Achse zu einer Beschï?½digung des elektrischen Antriebs fï?½hren kann.";
CM_ SG_ 706 MO_EM_Ueberhitzungswarnung "Der elektrische Antrieb ist aufgrund eines Fehlers oder dauerhaft sehr hoher Drehzahl ï?½berhitzt.";
CM_ SG_ 706 MO_Powermeter_Dauer_Grenze "Vortrieb Dauer?Leistung\n? dauerhaft verfï?½gbare Vortriebsleistung\n? abhï?½ngig von SOC und Temperatur";
CM_ SG_ 706 MO_Rekuperationsstufe "In Projekten mit variablen oder anwï?½hlbaren Rekuperationsstufen soll dem Fahrer die aktuell ausgewï?½hlte Stufe ï?½ber ein Icon in den Anzeigeinstrumenten visualisiert werden kï?½nnen. Dies dient der Nachvollziehbarkeit fï?½r den Kunden in Bezug auf eine zukï?½nfti";
CM_ SG_ 706 PEA_Texte "Status der Funktion PEA";
CM_ SG_ 706 TSK_Einheit_vMax_FahrerInfo "Einheit zu TSK_vMax_FahrerInfo. Das MSG spiegelt hier KBI_MFA_v_Einheit und stellt den Anzeigewert in dieser Einheit zur Verfï?½gung (kein zyklisches Mux)";
CM_ SG_ 706 TSK_Status_vMax_FahrerInfo "Status der TSK_vMax_FahrerInfo zur Steuerung von PopUps, Fahrzeugstatus und ggf. einer LED. Bei Wert 0 in TSK_vMax_Fahrerinfo soll auf eine unspezifische Begrenzung hingewiesen werden (z.B. wegen Momentenbegrenzung), bei allen anderen Werten soll dieser a";
CM_ SG_ 706 TSK_Ueberstimmt_vMax_FahrerInfo "Information ueber den Zustand wann die vMax-Limitierung vom Fahrer ueberstimmt wird.";
CM_ SG_ 706 TSK_vMax_FahrerInfo "anzuzeigende Begrenzungsgeschwindigkeit bei aktiver HGB";
CM_ SG_ 267 MO_Entkopplung_Sollschlupf "MSG fordert von GSG an, das Anfahrelement (Fahr-/Wandlerkupplung) zu entkoppeln; das GSG soll die gesendete Drehzahl als Schlupf einstellen und ggf. die Regler-Parameter umschalten, damit Rucke aus dem Antrieb nicht im Fahrzeug spï?½rbar werden; nutzbar z.B";
CM_ SG_ 267 MO_Fahrpedalgradient "Das Motorsteuergerï?½t besitzt 2 analoge Fahrpedalsignale. Das Signal des ersten Kanals wird alle 4ms abgetastet. Um Bitschwankungen des A/D-Wandler herauszufiltern wird das Signal entjittert. Anschlieï?½end wird der Gradient berechnet. Entsprechend der Zyklu";
CM_ SG_ 267 MO_Fahrpedalrohwert_01 "AUDI D4: Zykluszeit: 10ms (siehe Zykluszeit schnell/Cycletime Fast)\n\nStellung des Fahrpedales (Rohwert, ohne ï?½berlagerung durch GRA-Eingriffe etc.)\n\nDie Funktionen zur Berechung des Fahrpedalrohwerts laufen im 10ms Raster. Der Fahrpedalwert berechnet ";
CM_ SG_ 267 MO_Moment_im_Leerlauf "Fahrerwunschmoment ist minimal: keine Momentenanforderung durch Fahrpedal, ACC oder GRA+; (Das Signal ist unabhï?½ngig von Momentenerhï?½hungen durch Leerlaufregler oder MSR).\n\nAUDI D4: Zykluszeit: 10ms (siehe Zykluszeit schnell/Cycletime Fast)\n\nAchtung:";
CM_ SG_ 267 MO_QBit_Fahrpedalwerte_01 "AUDI D4: Zykluszeit: 10ms (siehe Zykluszeit schnell/Cycletime Fast)\n\nQBit fï?½r beide Fahrpedalwerte des Motors (Fahrpedalrohsignal fï?½r ESP, EPB, ACC; Fahrpedalwert fï?½r Getriebe)\n\nAchtung:\nReduktion der Zykluszeit Motor_03 auf 10ms geplant.\nProjektabh";
CM_ SG_ 267 MO_rel_Saugrohrdruck "Der Wert gibt an, um wieviel mbar der Saugrohrdruck unterhalb des Umgebungsdrucks liegt. ï?½berdruck im Saugrohr wird nicht ausgegeben.\n0: Saugrohrdruck=Umgebungsdruck";
CM_ SG_ 267 MO_rel_Saugrohrdruck_gem_err "0: mind. eine Modellrechnung wird zur Berechnung des relativen Saugdrucks herangezogen\n1: Relativer Saugrohrdruck wird ausschlieï?½lich ï?½ber Messgrï?½ï?½en bestimmt";
CM_ SG_ 267 MO_Schubabschaltung "ESP plausibilisiert Unterdrucksensor nur bei aktiver Schubabschaltung\n\nMLBevo:\nSignal wird nur in MLBevo Projekten mit PDKII Getriebe bedient. In allen anderen MLBevo Projekten wird das Signal mit '0' bedient\nPDKII berï?½cksichtigt Verzugszeiten, die in";
CM_ SG_ 267 MO_Sig_Fahrpedalgradient "Kennzeichnet das Vorzeichen des Signal 'Fahrpedalgradient'. Die Ausgabe erfolgt nur parallel statisch mit gesendetem Signal: 'Steuerungsbit Fahrpedalgradient' ";
CM_ SG_ 267 MO_Solldrehz_Leerlauf "Leerlaufsolldrehzahl, die im Motor eingestellt ist (Bei Parallelhybrid im E-Fahr-Betrieb Leerlaufsolldrehzahl der E-Maschine). Der Motor paï?½t aufgrund der Anforderung von anderen Steuergerï?½ten seine Leerlaufsolldrehzahl an, bspw. Kat-Heizen, Anforderung v";
CM_ SG_ 267 MO_StartStopp_StoppVorbereitung "Zeigt allen aktiven Start-/Stoppteilnehmern einen mï?½glichen Motorstopp im Anhaltevorgang an (Empfï?½nger notwendige Vorbereitungen treffen)\nEs liegen keine Vetos vor.";
CM_ SG_ 267 MO_Status_MaxDrzEingriff "Aktuell drehzahlfï?½hrender Anforderer der Maximaldrehzahl (Begrenzungsregelung) des Pulswechselrichters der Primï?½rachse.";
CM_ SG_ 267 MO_Status_MaxDrzEingriff_sek "Aktuell drehzahlfï?½hrender Anforderer der Maximaldrehzahl (Begrenzungsregelung) des Pulswechselrichters der Sekundï?½rachse.";
CM_ SG_ 267 MO_Status_MinDrzEingriff "Aktuell drehzahlfï?½hrender Anforderer der Minimaldrehzahl (Begrenzungsregelung) des Pulswechselrichters der Primï?½rachse.";
CM_ SG_ 267 MO_Status_MinDrzEingriff_sek "Aktuell drehzahlfï?½hrender Anforderer der Minimaldrehzahl (Begrenzungsregelung) des Pulswechselrichters der Sekundï?½rachse.";
CM_ SG_ 267 MO_temporaere_Fahrerabwesenheit "Das Signal dient zur Signalisierung einer temporï?½ren Abwesenheit des Fahrers. In dieser Zeit ist es ihm mï?½glich, sich durch gewisse ï?½ im Verlassenskonzept definierte ï?½ Fahreraktionen im aktuellen Fahrzyklus zurï?½ckzumelden.\nDas Signal wird gesetzt, sobald";
CM_ SG_ 267 Motor_51_BZ "4bit Botschaftszï?½hler, wird mit jeder Sendebotschaft inkrementiert";
CM_ SG_ 267 Motor_51_CRC "Fï?½r MLB:\nBerechnung siehe Lastenheft 'Kommunikationsabsicherung fï?½r FlexRay und CAN'\nAb MQB und MLBevo:\nBerechnung siehe Lastenheft 'End-to-End Kommunikationsabsicherung'\n\nEndwerte siehe Begleitdokument 'S-PDU Kennungsfolgen'";
CM_ SG_ 267 SOK_Motor_51_Signatur "Signatur im Rahmen der durch SOK geschï?½tzten Broadcast-Kommunikation\n\nGeschï?½tzte Funktion: Bremsfunktion HDC und Airbag-Funktionen \nGeschï?½tzte Botschaft: Motor_51";
CM_ SG_ 267 TSK_a_Soll_gradientenbegrenzt "TSK Sollbeschleunigung fï?½r Fahrerassistenzsysteme mit aktiver Lï?½ngsfï?½hrung (GRA, ACC, IPA...). Der Wert stellt den ruckbegrenzten Sollwert der TSK-Regelung dar und ist Basis der TSK-Antriebs- und Bremsmomentenvorsteuerung.";
CM_ SG_ 267 TSK_ax_Getriebe_02 "Beschleunigungsanforderung des Beschleunigungsreglers (u. a. fï?½r ACC, GRA, Speed Limiter). Das Signal wird vom Getriebe benutzt, um die von GRA/ACC geforderte Sollbeschleunigung in dem verbrauchsgï?½nstigsten Gang einzustellen.\nMQB: Im MQB wird die Sollbes";
CM_ SG_ 267 TSK_Freig_Verzoeg_Anf "Freigabe der Verzï?½gerungsanforderung der ACC oder ggf. GRA+ Funktion fï?½r ECD Regelung im ESP";
CM_ SG_ 267 TSK_Hauptschalter_GRA_ACC "Stellung des GRA/ACC Hauptschalters. Das Signal wird auch bei Fehlerabschaltungen von GRA/ACC weiterhin bedient und ermï?½glicht fï?½r ACC die Steuerung der ACC-Anzeige auch in Fehlerfï?½llen.";
CM_ SG_ 267 TSK_Kategorie_Verzoegerungsfkt "Zeigt der Bremslichtfunktion an, ob die aktuell verzï?½gerungswirksame Teilnehmerfunktion am TSK als Fahrerassistenzsystem oder als Schubrekuperation zu interpretieren ist.";
CM_ SG_ 267 TSK_Limiter_ausgewaehlt "ACC/GRA-Betrieb nur bei nicht ausgewï?½hltem Limiter mï?½glich";
CM_ SG_ 267 TSK_Notstopp_Anf "Anforderung Notstopp des TSK";
CM_ SG_ 267 TSK_Radbremsmom "Bei der Schnittstelle vom TSK zum ESP soll in Folgeprojekten des B8 und insbesondere bei VW-Projekten die Ansteuerung der Bremse nicht ï?½ber Sollbeschleunigung sondern Bremsmoment erfolgen.  Es handelt sich genauer um das Summenradbremsmoment, welches die ";
CM_ SG_ 267 TSK_Radsollmoment "Sollradmoment vom TSK";
CM_ SG_ 267 TSK_SRBM_Anf_ASIL "ASIL-Level des TSK-Anforderers, der aktuell eine Bremsmomentenanforderung auslï?½st";
CM_ SG_ 267 TSK_SRBM_max_Gradient "In diesem Signal wird der vom TSK maximal geforderte SummenRadBremsMomentengradient gesendet, der von der Bremse bei der Umsetzung der TSK-Verzï?½gerung nicht ï?½berschritten werden darf.";
CM_ SG_ 267 TSK_Standby_Anf_ESP "Mit diesem Bit wird das aktive Bremssystem auf eine anstehende TSK-Verzï?½gerungsanforderung vorbereitet (ï?½berfahren Leerweg, Anlegen Bremsbelï?½ge)";
CM_ SG_ 267 TSK_Status "Betriebszustand des TSK-Reglers";
CM_ SG_ 267 TSK_v_Begrenzung_aktiv "Limiter oder HGB begrenzen die Beschleunigung/das Moment";
CM_ SG_ 267 TSK_zul_Regelabw "Anforderung der zulï?½ssigen Regelabweichung vom Triebstrangkoordinator. Zulï?½ssiger Betrag der Abweichung zwischen angeforderter 'TSK_Sollbeschleunigung_Getriebe' und umzusetzender Sollbeschleunigung  im Getriebe. Im TSK wird, abhï?½ngig vom Arbeitspunkt die ";
CM_ SG_ 267 TSK_Zwangszusch_ESP "Mit diesem Bit wird das ESP/ASR zwangsweise aktiviert. Bei gesetztem Bit ist ein ausgetastetes ESP (oder ASR) wieder aktiviert bzw. wird die Austastung verhindert.";
CM_ SG_ 330 Ladezustand_02 "Aktueller relativer Ladezustand der HV-Batterie\n";
CM_ SG_ 330 Ladezustand_gering "Fahrerwarnung bezï?½glich geringem Ladezustand der HV-Batterie";
CM_ SG_ 330 MO_Anzeige_Drehmoment "Drehmomentssignal fï?½r Sport-HMI im Kombi.";
CM_ SG_ 330 MO_Anzeige_Leistung "Leistungssignal fï?½r Sport-HMI im Kombi.";
CM_ SG_ 330 MO_Anzeige_Verbr_Einheit "Signal steht im Kontext MO_Anzeige_Verbrauch und ï?½bertrï?½gt die Verbrauchseinheit der aktuellen Antriebsart. Signal muss in der gleichen Botschaft wie MO_Anzeige_Verbrauch ï?½bertragen werden";
CM_ SG_ 330 MO_Anzeigedrehz "Optimierte Anzeigedrehzahl wegen sportlicherem Drehzahlmesser im Kombi. \nBei Parallelhybrid: Anzeige VKM- Drehzahl nach Anzeigekonzept\n\nHinweis: Ehemaliger Fehlerwert 0xFFF wird senderseitig nicht unterstï?½tzt. Diesen Wert aus Kompatibilitï?½tsgrï?½nden nic";
CM_ SG_ 330 MO_Effizienzmodus "Bei Handschaltern wird  das Fahrprogramm Effizienz signalisiert. \nBei Automatikgetrieben wird das Fahrprogramm 'D' durch 'E' ersetzt.";
CM_ SG_ 330 MO_ePerformance "Zeigt die elektrische Leistungreserve bei BEV und PHEV Projekten an.\nBei Init und Fehler soll keine Anzeige erfolgen. ";
CM_ SG_ 330 MO_ePowermeter "Anzeige ePowermeter (Fahrreserve elektrisch bis Start Verbrennungsmotor (Verbrenner startet bei 100%))";
CM_ SG_ 330 MO_Fehler_Oeldrucksensor "Steuert  im Kombiinstrument die gelbe zentrale Warnlampe und das Symbol 'gelbe ï?½lkanne'  mit der Textmeldung 'Sensorfehler: Werkstatt aufsuchen' an\n";
CM_ SG_ 330 MO_Hochschaltdrehz "Hochschaltdrehzahl bei manuellem Gangwechsel ï?½ber Lenkrad Tip-Up oder Gangwahlhebel falls dieser in Tippgasse.\nNur AUDI RS-Modelle!";
CM_ SG_ 330 MO_Istgang "Aktueller Gang fï?½r Anzeige Hochschaltempfehlung (gï?½ltig, wenn MO_Schaltempf_verfbar = 1).\n\nAnzeige im Kombi:\nSollgang == Istgang         ==> Anzeige Istgang\nSollgang !=   Istgang         ==> Schaltempfehlung\nSollgang == Istgang == 0 ==> keine Anzeige";
CM_ SG_ 330 MO_KVS "Motorsteuergerï?½tinterner Verbrauchszï?½hler, der vom Kombi zyklisch ausgelesen wird, um die Einspritzmenge zur Verbrauchsmessung aufzusummieren; aus diesem Zï?½hlerstand werden Momentan- und Durchschnittsverbrauch berechnet; das ï?½berlauf-Bit ist zu berï?½cksich";
CM_ SG_ 330 MO_KVS_Ueberlauf "Der motorsteuergerï?½teinterne Verbrauchszï?½hler ist mindestens einmal ï?½bergelaufen. Dieses Bit wird genutzt, um erkennen zu kï?½nnen, daï?½ das Motorsteuergerï?½t aus dem Reset-Zustand hochlï?½uft.";
CM_ SG_ 330 MO_Ladedruck "absoluter Ladedruck";
CM_ SG_ 330 MO_Oeldruck "ï?½ldruck analog zur Anzeige";
CM_ SG_ 330 MO_Powermeter "Anzeigewerte im Kombi\n0       = Unteres Ende Bremsen/grau;\n340   = Unteres Ende CHARGE;\n1020 = READY;\n1870 = Oberes Ende EFFICIENCY;\n3400 = 100%;\n4080 = MAX;";
CM_ SG_ 330 MO_Powermeter_Elm_02 "relatives Moment / relative Leistung der elektrischen Maschine";
CM_ SG_ 330 MO_rel_Ladedruck "relativer Ladedruck (fï?½r Boostanzeige)";
CM_ SG_ 330 MO_Schaltblitz_Anz "Signalisierung der drehzahlabhï?½ngigen Schaltblitzanzeige im Kombiinstrument (0-100%)";
CM_ SG_ 330 MO_Schaltempf_verfbar "Info, ob Schaltempfehlung im Fzg. verfï?½gbar. Statischer Wert, ï?½ndert sich fï?½r ein Fzg. nicht!";
CM_ SG_ 330 MO_Sollgang "Motor sendet den Sollgang in den der Fahrer schalten soll. Wird im Kombi als Hochschaltempfehlung hervorgehoben (gï?½ltig, wenn MO_Schaltempf_verfbar = 1).\n\nAnzeige im Kombi:\nSollgang == Istgang          ==> Anzeige Istgang\nSollgang !=  Istgang         ";
CM_ SG_ 330 MO_Zust_Antrieb "Signalisiert die Zuordnung der Antriebsverbrï?½uche zu den Antriebsmaschinen fï?½r die Restreichweitenberechnung, nicht gleichbedeutend mit Motorlauf EM oder VM bzw. Brennstoffzelle";
CM_ SG_ 330 MO_Zust_Betriebsstrategie "Signalisiert den aktuellen Zustand der Betriebsstrategie";
CM_ SG_ 330 Motor_52_BZ "4bit Botschaftszï?½hler, wird mit jeder Sendebotschaft inkrementiert";
CM_ SG_ 330 Motor_52_CRC "Fï?½r MLB:\nBerechnung siehe Lastenheft 'Kommunikationsabsicherung fï?½r FlexRay und CAN'\nAb MQB und MLBevo:\nBerechnung siehe Lastenheft 'End-to-End Kommunikationsabsicherung'\n\nEndwerte siehe Begleitdokument 'S-PDU Kennungsfolgen'";
BA_DEF_ BO_ "CANFD_BRS" ENUM "0", "1";
BA_DEF_ BO_ "DiagRequest" ENUM "No", "Yes";
BA_DEF_ BO_ "DiagResponse" ENUM "No", "Yes";
BA_DEF_ BO_ "DiagState" ENUM "No", "Yes";
BA_DEF_ BO_ "GenMsgChkConstant" HEX 0 4095;
BA_DEF_ BO_ "GenMsgCycleTime" INT 0 65535;
BA_DEF_ BO_ "GenMsgCycleTimeFast" INT 0 65535;
BA_DEF_ BO_ "GenMsgDelayTime" INT 0 100000;
BA_DEF_ BO_ "GenMsgILSupport" ENUM "No", "Yes";
BA_DEF_ BO_ "GenMsgNrOfRepetition" INT 0 100;
BA_DEF_ BO_ "GenMsgPDUConstants" STRING;
BA_DEF_ BO_ "GenMsgSendType" ENUM "Cyclic", "not_used", "not_used", "not_used", "not_used", "not_used", "not_used", "IfActive", "NoMsgSendType";
BA_DEF_ BO_ "GenMsgStartDelayTime" INT 0 100000;
BA_DEF_ BO_ "MsgType" ENUM "Application", "NM ", "NMH", "TP2.0", "ISO-TP ", "BAP", "EID", "KS", "XCP_PRE_CONFIGURED", "XCP_RUNTIME_CONFIGURED";
BA_DEF_ BO_ "NmMessage" ENUM "No", "Yes";
BA_DEF_ BO_ "NmhMessage" ENUM "No", "Yes";
BA_DEF_ BO_ "VAGTP20_API" HEX 0 255;
BA_DEF_ BO_ "VAGTP20_DynConnection" ENUM "No", "Yes";
BA_DEF_ BO_ "VAGTP20_DynSetup" ENUM "No", "Yes";
BA_DEF_ BO_ "VAGTP20_StatConnection" ENUM "No", "Yes";
BA_DEF_ BO_ "VFrameFormat" ENUM "StandardCAN", "ExtendedCAN", "reserved", "reserved", "reserved", "reserved", "reserved", "reserved", "reserved", "reserved", "reserved", "reserved", "reserved", "reserved", "StandardCAN_FD", "ExtendedCAN_FD";
BA_DEF_ SG_ "Fehlerwert" HEX 0 2147483647;
BA_DEF_ SG_ "GenSigActiveRepetitions" INT -2147483648 2147483647;
BA_DEF_ SG_ "GenSigFuncType" ENUM "NoFunction", "MsgCounter", "CRC-8", "XOR", "XOR-2", "DatedBit", "SW-Kl15", "CHK", "Constant", "Protocol", "CRC-8-SAE_J1850", "CRC-32", "DataLength", "DataID", "MsgCounter16", "SOK-Signatur", "Cluster";
BA_DEF_ SG_ "GenSigInactiveValue" INT -2147483648 2147483647;
BA_DEF_ SG_ "GenSigMissingSourceValue" HEX 0 2147483647;
BA_DEF_ SG_ "GenSigSendType" ENUM "Cyclic", "OnWrite", "OnWriteWithRepetition", "OnChange", "OnChangeWithRepetition", "IfActive", "IfActiveWithRepetition", "NoSigSendType", "OnChangeAndIfActive", "OnChangeAndIfActiveWithRepetition";
BA_DEF_ SG_ "GenSigStartValue" INT -2147483648 2147483647;
BA_DEF_ SG_ "GenSigSwitchedByIgnition" ENUM "No", "Yes";
BA_DEF_ SG_ "NWM-WakeupAllowed" ENUM "No", "Yes";

BA_DEF_REL_ BU_SG_REL_ "GenSigTimeoutTime" INT 0 65535;
BA_DEF_DEF_ "CANFD_BRS" "1";
BA_DEF_DEF_ "DiagRequest" "No";
BA_DEF_DEF_ "DiagResponse" "No";
BA_DEF_DEF_ "DiagState" "No";
BA_DEF_DEF_ "Fehlerwert" 0;
BA_DEF_DEF_ "GenMsgChkConstant" 0;
BA_DEF_DEF_ "GenMsgCycleTime" 0;
BA_DEF_DEF_ "GenMsgCycleTimeFast" 0;
BA_DEF_DEF_ "GenMsgDelayTime" 0;
BA_DEF_DEF_ "GenMsgILSupport" "No";
BA_DEF_DEF_ "GenMsgNrOfRepetition" 0;
BA_DEF_DEF_ "GenMsgPDUConstants" "";
BA_DEF_DEF_ "GenMsgSendType" "NoMsgSendType";
BA_DEF_DEF_ "GenMsgStartDelayTime" 0;
BA_DEF_DEF_ "GenSigActiveRepetitions" 0;
BA_DEF_DEF_ "GenSigFuncType" "NoFunction";
BA_DEF_DEF_ "GenSigInactiveValue" 0;
BA_DEF_DEF_ "GenSigMissingSourceValue" 0;
BA_DEF_DEF_ "GenSigSendType" "NoSigSendType";
BA_DEF_DEF_ "GenSigStartValue" 0;
BA_DEF_DEF_ "GenSigSwitchedByIgnition" "Yes";
BA_DEF_DEF_ "MsgType" "Application";
BA_DEF_DEF_ "NWM-WakeupAllowed" "No";
BA_DEF_DEF_ "NmMessage" "No";
BA_DEF_DEF_ "NmhMessage" "No";
BA_DEF_DEF_ "VAGTP20_API" 0;
BA_DEF_DEF_ "VAGTP20_DynConnection" "No";
BA_DEF_DEF_ "VAGTP20_DynSetup" "No";
BA_DEF_DEF_ "VAGTP20_StatConnection" "No";
BA_DEF_DEF_ "VFrameFormat" "StandardCAN";
BA_DEF_DEF_REL_ "GenSigTimeoutTime" 0;
BA_ "GenMsgCycleTime" BO_ 1153 500;
BA_ "GenMsgCycleTimeFast" BO_ 1153 50;
BA_ "GenMsgDelayTime" BO_ 1153 50;
BA_ "GenMsgILSupport" BO_ 1153 1;
BA_ "GenMsgNrOfRepetition" BO_ 1153 5;
BA_ "GenMsgSendType" BO_ 1153 0;
BA_ "VFrameFormat" BO_ 1153 14;
BA_ "GenMsgCycleTime" BO_ 1639 100;
BA_ "GenMsgDelayTime" BO_ 1639 50;
BA_ "GenMsgILSupport" BO_ 1639 1;
BA_ "GenMsgSendType" BO_ 1639 0;
BA_ "VFrameFormat" BO_ 1639 14;
BA_ "GenMsgCycleTime" BO_ 1178 100;
BA_ "GenMsgDelayTime" BO_ 1178 50;
BA_ "GenMsgILSupport" BO_ 1178 1;
BA_ "GenMsgSendType" BO_ 1178 0;
BA_ "VFrameFormat" BO_ 1178 14;
BA_ "GenMsgChkConstant" BO_ 1171 151;
BA_ "GenMsgCycleTime" BO_ 1171 200;
BA_ "GenMsgDelayTime" BO_ 1171 20;
BA_ "GenMsgILSupport" BO_ 1171 1;
BA_ "GenMsgPDUConstants" BO_ 1171 "0x97,0x97,0x97,0x97,0x97,0x97,0x97,0x97,0x97,0x97,0x97,0x97,0x97,0x97,0x97,0x97";
BA_ "GenMsgSendType" BO_ 1171 0;
BA_ "VFrameFormat" BO_ 1171 14;
BA_ "GenMsgCycleTime" BO_ 1164 200;
BA_ "GenMsgCycleTimeFast" BO_ 1164 50;
BA_ "GenMsgDelayTime" BO_ 1164 20;
BA_ "GenMsgILSupport" BO_ 1164 1;
BA_ "GenMsgNrOfRepetition" BO_ 1164 5;
BA_ "GenMsgSendType" BO_ 1164 0;
BA_ "VFrameFormat" BO_ 1164 14;
BA_ "GenMsgCycleTime" BO_ 817 500;
BA_ "GenMsgCycleTimeFast" BO_ 817 30;
BA_ "GenMsgILSupport" BO_ 817 1;
BA_ "GenMsgSendType" BO_ 817 0;
BA_ "VFrameFormat" BO_ 817 14;
BA_ "GenMsgCycleTime" BO_ 560 100;
BA_ "GenMsgDelayTime" BO_ 560 10;
BA_ "GenMsgILSupport" BO_ 560 1;
BA_ "GenMsgSendType" BO_ 560 0;
BA_ "VFrameFormat" BO_ 560 14;
BA_ "GenMsgCycleTime" BO_ 2463978751 1000;
BA_ "GenMsgCycleTimeFast" BO_ 2463978751 100;
BA_ "GenMsgDelayTime" BO_ 2463978751 50;
BA_ "GenMsgILSupport" BO_ 2463978751 1;
BA_ "GenMsgNrOfRepetition" BO_ 2463978751 5;
BA_ "GenMsgSendType" BO_ 2463978751 0;
BA_ "VFrameFormat" BO_ 2463978751 15;
BA_ "GenMsgDelayTime" BO_ 1471 10;
BA_ "GenMsgILSupport" BO_ 1471 1;
BA_ "VFrameFormat" BO_ 1471 14;
BA_ "GenMsgCycleTime" BO_ 958 100;
BA_ "GenMsgDelayTime" BO_ 958 10;
BA_ "GenMsgILSupport" BO_ 958 1;
BA_ "GenMsgPDUConstants" BO_ 958 "0x1f,0x28,0xc6,0x85,0xe6,0xf8,0xb0,0x19,0x5b,0x64,0x35,0x21,0xe4,0xf7,0x9c,0x24";
BA_ "GenMsgSendType" BO_ 958 0;
BA_ "VFrameFormat" BO_ 958 14;
BA_ "GenMsgCycleTime" BO_ 1648 500;
BA_ "GenMsgDelayTime" BO_ 1648 20;
BA_ "GenMsgILSupport" BO_ 1648 1;
BA_ "GenMsgSendType" BO_ 1648 0;
BA_ "VFrameFormat" BO_ 1648 14;
BA_ "GenMsgCycleTime" BO_ 967 100;
BA_ "GenMsgILSupport" BO_ 967 1;
BA_ "GenMsgSendType" BO_ 967 0;
BA_ "VFrameFormat" BO_ 967 14;
BA_ "GenMsgCycleTime" BO_ 966 100;
BA_ "GenMsgILSupport" BO_ 966 1;
BA_ "GenMsgSendType" BO_ 966 0;
BA_ "VFrameFormat" BO_ 966 14;
BA_ "GenMsgCycleTime" BO_ 706 500;
BA_ "GenMsgDelayTime" BO_ 706 100;
BA_ "GenMsgILSupport" BO_ 706 1;
BA_ "GenMsgSendType" BO_ 706 0;
BA_ "VFrameFormat" BO_ 706 14;
BA_ "GenMsgCycleTime" BO_ 267 20;
BA_ "GenMsgILSupport" BO_ 267 1;
BA_ "GenMsgPDUConstants" BO_ 267 "0x2c,0xb1,0x1a,0x75,0xbb,0x65,0x79,0x47,0x81,0x2b,0xcc,0x96,0x17,0xdb,0xc0,0x94";
BA_ "GenMsgSendType" BO_ 267 0;
BA_ "VFrameFormat" BO_ 267 14;
BA_ "GenMsgCycleTime" BO_ 330 20;
BA_ "GenMsgILSupport" BO_ 330 1;
BA_ "GenMsgSendType" BO_ 330 0;
BA_ "VFrameFormat" BO_ 330 14;
BA_ "GenSigSendType" SG_ 1153 DSSS_Warning 3;
BA_ "GenSigSwitchedByIgnition" SG_ 1153 DSSS_Warning 0;
BA_ "GenSigSendType" SG_ 1153 HMI_WLC1_Systemzustand_intern 3;
BA_ "GenSigStartValue" SG_ 1153 HMI_WLC1_Systemzustand_intern 2;
BA_ "GenSigSwitchedByIgnition" SG_ 1153 HMI_WLC1_Systemzustand_intern 0;
BA_ "GenSigSendType" SG_ 1153 HMI_WLC2_Systemzustand_intern 3;
BA_ "GenSigStartValue" SG_ 1153 HMI_WLC2_Systemzustand_intern 2;
BA_ "GenSigSwitchedByIgnition" SG_ 1153 HMI_WLC2_Systemzustand_intern 0;
BA_ "Fehlerwert" SG_ 1153 INF_Nachlaufzeit 511;
BA_ "GenSigSendType" SG_ 1153 INF_Nachlaufzeit 0;
BA_ "GenSigStartValue" SG_ 1153 INF_Nachlaufzeit 510;
BA_ "GenSigSwitchedByIgnition" SG_ 1153 INF_Nachlaufzeit 0;
BA_ "GenSigSendType" SG_ 1153 MIB_ASW_Diagnose 0;
BA_ "GenSigStartValue" SG_ 1153 MIB_ASW_Diagnose 1;
BA_ "GenSigSwitchedByIgnition" SG_ 1153 MIB_ASW_Diagnose 0;
BA_ "GenSigSendType" SG_ 1153 MIB_Tongenerator_PH_verfuegbar 3;
BA_ "GenSigSwitchedByIgnition" SG_ 1153 MIB_Tongenerator_PH_verfuegbar 0;
BA_ "GenSigSendType" SG_ 1153 MMI_Counter_Bedienevent 0;
BA_ "GenSigSwitchedByIgnition" SG_ 1153 MMI_Counter_Bedienevent 0;
BA_ "GenSigSendType" SG_ 1153 MMI_Gurt_Mic_ref 3;
BA_ "GenSigSwitchedByIgnition" SG_ 1153 MMI_Gurt_Mic_ref 0;
BA_ "GenSigSendType" SG_ 1153 MMI_SDS_aktiv 3;
BA_ "GenSigSwitchedByIgnition" SG_ 1153 MMI_SDS_aktiv 0;
BA_ "GenSigSendType" SG_ 1153 MMI_Telefon_aktiv 3;
BA_ "GenSigSwitchedByIgnition" SG_ 1153 MMI_Telefon_aktiv 0;
BA_ "GenSigSendType" SG_ 1153 MU_SecondDisplay 3;
BA_ "GenSigSwitchedByIgnition" SG_ 1153 MU_SecondDisplay 0;
BA_ "GenSigSendType" SG_ 1153 MU_Update_Time 0;
BA_ "GenSigSwitchedByIgnition" SG_ 1153 MU_Update_Time 0;
BA_ "GenSigSendType" SG_ 1153 Nav_FoD_Status 0;
BA_ "GenSigSwitchedByIgnition" SG_ 1153 Nav_FoD_Status 0;
BA_ "GenSigSendType" SG_ 1153 ZR_AppConnect_Zustand 4;
BA_ "GenSigSwitchedByIgnition" SG_ 1153 ZR_AppConnect_Zustand 0;
BA_ "GenSigSendType" SG_ 1153 ZR_Kindersicherung_RSE 3;
BA_ "GenSigSwitchedByIgnition" SG_ 1153 ZR_Kindersicherung_RSE 0;
BA_ "GenSigSendType" SG_ 1153 ZR_Lichter_Tag 3;
BA_ "GenSigStartValue" SG_ 1153 ZR_Lichter_Tag 1;
BA_ "GenSigSwitchedByIgnition" SG_ 1153 ZR_Lichter_Tag 0;
BA_ "GenSigSendType" SG_ 1153 ZR_LoGeWa_Event_Kombiwarnung 3;
BA_ "GenSigSwitchedByIgnition" SG_ 1153 ZR_LoGeWa_Event_Kombiwarnung 0;
BA_ "GenSigSendType" SG_ 1153 ZR_Parken_Sondermodus 3;
BA_ "GenSigSwitchedByIgnition" SG_ 1153 ZR_Parken_Sondermodus 0;
BA_ "GenSigSendType" SG_ 1153 ZR_RSE_aktivieren 3;
BA_ "GenSigSwitchedByIgnition" SG_ 1153 ZR_RSE_aktivieren 0;
BA_ "GenSigSendType" SG_ 1639 BFS_Fond_Bed_Ack 3;
BA_ "GenSigSwitchedByIgnition" SG_ 1639 BFS_Fond_Bed_Ack 0;
BA_ "GenSigSendType" SG_ 1639 BFS_FSV_ausgeklappt 0;
BA_ "GenSigSwitchedByIgnition" SG_ 1639 BFS_FSV_ausgeklappt 0;
BA_ "GenSigSendType" SG_ 1639 BFS_GHV_aktiv 3;
BA_ "GenSigSwitchedByIgnition" SG_ 1639 BFS_GHV_aktiv 0;
BA_ "GenSigSendType" SG_ 1639 BFS_Gurtbringer_Sperre 0;
BA_ "GenSigSwitchedByIgnition" SG_ 1639 BFS_Gurtbringer_Sperre 0;
BA_ "GenSigSendType" SG_ 1639 BFS_Klapptisch_offen 3;
BA_ "GenSigSwitchedByIgnition" SG_ 1639 BFS_Klapptisch_offen 0;
BA_ "GenSigSendType" SG_ 1639 BFS_KSS_Fahrt_aktiv 3;
BA_ "GenSigSwitchedByIgnition" SG_ 1639 BFS_KSS_Fahrt_aktiv 0;
BA_ "GenSigSendType" SG_ 1639 BFS_KSV_aktiv 3;
BA_ "GenSigSwitchedByIgnition" SG_ 1639 BFS_KSV_aktiv 0;
BA_ "GenSigSendType" SG_ 1639 BFS_Lehne_nicht_verriegelt 3;
BA_ "GenSigSwitchedByIgnition" SG_ 1639 BFS_Lehne_nicht_verriegelt 0;
BA_ "GenSigSendType" SG_ 1639 BFS_LHV_aktiv 3;
BA_ "GenSigSwitchedByIgnition" SG_ 1639 BFS_LHV_aktiv 0;
BA_ "GenSigSendType" SG_ 1639 BFS_LKV_aktiv 3;
BA_ "GenSigSwitchedByIgnition" SG_ 1639 BFS_LKV_aktiv 0;
BA_ "GenSigSendType" SG_ 1639 BFS_LNV_aktiv 3;
BA_ "GenSigSwitchedByIgnition" SG_ 1639 BFS_LNV_aktiv 0;
BA_ "GenSigSendType" SG_ 1639 BFS_LWV_aktiv 3;
BA_ "GenSigSwitchedByIgnition" SG_ 1639 BFS_LWV_aktiv 0;
BA_ "GenSigSendType" SG_ 1639 BFS_MMB_glob_stop 3;
BA_ "GenSigSwitchedByIgnition" SG_ 1639 BFS_MMB_glob_stop 0;
BA_ "GenSigSendType" SG_ 1639 BFS_MMB_lokal_Stop 3;
BA_ "GenSigSwitchedByIgnition" SG_ 1639 BFS_MMB_lokal_Stop 0;
BA_ "GenSigSendType" SG_ 1639 BFS_MMB_storage 3;
BA_ "GenSigSwitchedByIgnition" SG_ 1639 BFS_MMB_storage 0;
BA_ "GenSigSendType" SG_ 1639 BFS_MMB_storage_beep 3;
BA_ "GenSigSwitchedByIgnition" SG_ 1639 BFS_MMB_storage_beep 0;
BA_ "GenSigSendType" SG_ 1639 BFS_MMB_store 3;
BA_ "GenSigSwitchedByIgnition" SG_ 1639 BFS_MMB_store 0;
BA_ "GenSigSendType" SG_ 1639 BFS_MMB_store_LED_on 3;
BA_ "GenSigSwitchedByIgnition" SG_ 1639 BFS_MMB_store_LED_on 0;
BA_ "GenSigSendType" SG_ 1639 BFS_MMB_tast 3;
BA_ "GenSigSwitchedByIgnition" SG_ 1639 BFS_MMB_tast 0;
BA_ "GenSigSendType" SG_ 1639 BFS_MMB_tipp 3;
BA_ "GenSigSwitchedByIgnition" SG_ 1639 BFS_MMB_tipp 0;
BA_ "GenSigSendType" SG_ 1639 BFS_Ruhestellung_Status 3;
BA_ "GenSigSwitchedByIgnition" SG_ 1639 BFS_Ruhestellung_Status 0;
BA_ "GenSigSendType" SG_ 1639 BFS_Seat_Locked 0;
BA_ "GenSigSwitchedByIgnition" SG_ 1639 BFS_Seat_Locked 0;
BA_ "GenSigSendType" SG_ 1639 BFS_SHV_aktiv 3;
BA_ "GenSigSwitchedByIgnition" SG_ 1639 BFS_SHV_aktiv 0;
BA_ "GenSigSendType" SG_ 1639 BFS_Sitzfahrt_aktiv 3;
BA_ "GenSigSwitchedByIgnition" SG_ 1639 BFS_Sitzfahrt_aktiv 0;
BA_ "GenSigSendType" SG_ 1639 BFS_Sitzsym_Fahrt_aktiv 3;
BA_ "GenSigSwitchedByIgnition" SG_ 1639 BFS_Sitzsym_Fahrt_aktiv 0;
BA_ "GenSigSendType" SG_ 1639 BFS_SLV_aktiv 3;
BA_ "GenSigSwitchedByIgnition" SG_ 1639 BFS_SLV_aktiv 0;
BA_ "GenSigSendType" SG_ 1639 BFS_SNV_aktiv 3;
BA_ "GenSigSwitchedByIgnition" SG_ 1639 BFS_SNV_aktiv 0;
BA_ "GenSigSendType" SG_ 1639 BFS_STV_aktiv 3;
BA_ "GenSigSwitchedByIgnition" SG_ 1639 BFS_STV_aktiv 0;
BA_ "GenSigSendType" SG_ 1178 FS_BFS_Fond_Verst_enable 3;
BA_ "GenSigSwitchedByIgnition" SG_ 1178 FS_BFS_Fond_Verst_enable 0;
BA_ "GenSigSendType" SG_ 1178 FS_BFS_KSS_Anfahrt 3;
BA_ "GenSigSwitchedByIgnition" SG_ 1178 FS_BFS_KSS_Anfahrt 0;
BA_ "GenSigSendType" SG_ 1178 FS_BFS_Sitzsym_Anfahrt 3;
BA_ "GenSigSwitchedByIgnition" SG_ 1178 FS_BFS_Sitzsym_Anfahrt 0;
BA_ "GenSigSendType" SG_ 1178 FS_EE_BFS_enable 3;
BA_ "GenSigSwitchedByIgnition" SG_ 1178 FS_EE_BFS_enable 0;
BA_ "GenSigSendType" SG_ 1178 FS_EE_Fond_BFS_enable 3;
BA_ "GenSigSwitchedByIgnition" SG_ 1178 FS_EE_Fond_BFS_enable 0;
BA_ "GenSigSendType" SG_ 1178 FS_EE_Fond_FS_enable 3;
BA_ "GenSigSwitchedByIgnition" SG_ 1178 FS_EE_Fond_FS_enable 0;
BA_ "GenSigSendType" SG_ 1178 FS_Fond_Bed_enable 3;
BA_ "GenSigSwitchedByIgnition" SG_ 1178 FS_Fond_Bed_enable 0;
BA_ "GenSigSendType" SG_ 1178 FS_GHV_aktiv 3;
BA_ "GenSigSwitchedByIgnition" SG_ 1178 FS_GHV_aktiv 0;
BA_ "GenSigSendType" SG_ 1178 FS_Gurtbringer_Sperre 0;
BA_ "GenSigSwitchedByIgnition" SG_ 1178 FS_Gurtbringer_Sperre 0;
BA_ "GenSigSendType" SG_ 1178 FS_KSV_aktiv 3;
BA_ "GenSigSwitchedByIgnition" SG_ 1178 FS_KSV_aktiv 0;
BA_ "GenSigSendType" SG_ 1178 FS_Lehne_nicht_verriegelt 3;
BA_ "GenSigSwitchedByIgnition" SG_ 1178 FS_Lehne_nicht_verriegelt 0;
BA_ "GenSigSendType" SG_ 1178 FS_LHV_aktiv 3;
BA_ "GenSigSwitchedByIgnition" SG_ 1178 FS_LHV_aktiv 0;
BA_ "GenSigSendType" SG_ 1178 FS_LKV_aktiv 3;
BA_ "GenSigSwitchedByIgnition" SG_ 1178 FS_LKV_aktiv 0;
BA_ "GenSigSendType" SG_ 1178 FS_LNV_aktiv 3;
BA_ "GenSigSwitchedByIgnition" SG_ 1178 FS_LNV_aktiv 0;
BA_ "GenSigSendType" SG_ 1178 FS_LWV_aktiv 3;
BA_ "GenSigSwitchedByIgnition" SG_ 1178 FS_LWV_aktiv 0;
BA_ "GenSigSendType" SG_ 1178 FS_MMB_glob_stop 3;
BA_ "GenSigSwitchedByIgnition" SG_ 1178 FS_MMB_glob_stop 0;
BA_ "GenSigSendType" SG_ 1178 FS_MMB_lokal_Stop 3;
BA_ "GenSigSwitchedByIgnition" SG_ 1178 FS_MMB_lokal_Stop 0;
BA_ "GenSigSendType" SG_ 1178 FS_MMB_storage 3;
BA_ "GenSigSwitchedByIgnition" SG_ 1178 FS_MMB_storage 0;
BA_ "GenSigSendType" SG_ 1178 FS_MMB_storage_beep 3;
BA_ "GenSigSwitchedByIgnition" SG_ 1178 FS_MMB_storage_beep 0;
BA_ "GenSigSendType" SG_ 1178 FS_MMB_store 3;
BA_ "GenSigSwitchedByIgnition" SG_ 1178 FS_MMB_store 0;
BA_ "GenSigSendType" SG_ 1178 FS_MMB_store_LED_on 3;
BA_ "GenSigSwitchedByIgnition" SG_ 1178 FS_MMB_store_LED_on 0;
BA_ "GenSigSendType" SG_ 1178 FS_MMB_tast 3;
BA_ "GenSigSwitchedByIgnition" SG_ 1178 FS_MMB_tast 0;
BA_ "GenSigSendType" SG_ 1178 FS_MMB_tipp 3;
BA_ "GenSigSwitchedByIgnition" SG_ 1178 FS_MMB_tipp 0;
BA_ "GenSigSendType" SG_ 1178 FS_SHV_aktiv 3;
BA_ "GenSigSwitchedByIgnition" SG_ 1178 FS_SHV_aktiv 0;
BA_ "GenSigSendType" SG_ 1178 FS_Sitzfahrt_aktiv 3;
BA_ "GenSigSwitchedByIgnition" SG_ 1178 FS_Sitzfahrt_aktiv 0;
BA_ "GenSigSendType" SG_ 1178 FS_SLV_aktiv 3;
BA_ "GenSigSwitchedByIgnition" SG_ 1178 FS_SLV_aktiv 0;
BA_ "GenSigSendType" SG_ 1178 FS_SNV_aktiv 3;
BA_ "GenSigSwitchedByIgnition" SG_ 1178 FS_SNV_aktiv 0;
BA_ "GenSigSendType" SG_ 1178 FS_Spezialposition_anfahren 3;
BA_ "GenSigSwitchedByIgnition" SG_ 1178 FS_Spezialposition_anfahren 0;
BA_ "GenSigSendType" SG_ 1178 FS_STV_aktiv 3;
BA_ "GenSigSwitchedByIgnition" SG_ 1178 FS_STV_aktiv 0;
BA_ "GenSigSendType" SG_ 1171 MF_Abzugssperre 3;
BA_ "GenSigSwitchedByIgnition" SG_ 1171 MF_Abzugssperre 0;
BA_ "GenSigSendType" SG_ 1171 MF_Alarm_Blinker 3;
BA_ "GenSigSwitchedByIgnition" SG_ 1171 MF_Alarm_Blinker 0;
BA_ "GenSigSendType" SG_ 1171 MF_Alarm_Blinkertakt 3;
BA_ "GenSigSwitchedByIgnition" SG_ 1171 MF_Alarm_Blinkertakt 0;
BA_ "GenSigSendType" SG_ 1171 MF_Anlassersperre 3;
BA_ "GenSigSwitchedByIgnition" SG_ 1171 MF_Anlassersperre 0;
BA_ "GenSigSendType" SG_ 1171 MF_Blk_li 3;
BA_ "GenSigSwitchedByIgnition" SG_ 1171 MF_Blk_li 0;
BA_ "GenSigSendType" SG_ 1171 MF_Blk_re 3;
BA_ "GenSigSwitchedByIgnition" SG_ 1171 MF_Blk_re 0;
BA_ "GenSigSendType" SG_ 1171 MF_BT_entriegeln 3;
BA_ "GenSigSwitchedByIgnition" SG_ 1171 MF_BT_entriegeln 0;
BA_ "GenSigSendType" SG_ 1171 MF_BT_verriegeln 3;
BA_ "GenSigSwitchedByIgnition" SG_ 1171 MF_BT_verriegeln 0;
BA_ "GenSigSendType" SG_ 1171 MF_Fahrlicht 3;
BA_ "GenSigSwitchedByIgnition" SG_ 1171 MF_Fahrlicht 0;
BA_ "GenSigSendType" SG_ 1171 MF_Fernbed_ein 3;
BA_ "GenSigSwitchedByIgnition" SG_ 1171 MF_Fernbed_ein 0;
BA_ "GenSigSendType" SG_ 1171 MF_Fernlicht 3;
BA_ "GenSigSwitchedByIgnition" SG_ 1171 MF_Fernlicht 0;
BA_ "GenSigSendType" SG_ 1171 MF_FH_BT_hoch 3;
BA_ "GenSigSwitchedByIgnition" SG_ 1171 MF_FH_BT_hoch 0;
BA_ "GenSigSendType" SG_ 1171 MF_FH_BT_tief 3;
BA_ "GenSigSwitchedByIgnition" SG_ 1171 MF_FH_BT_tief 0;
BA_ "GenSigSendType" SG_ 1171 MF_FH_FT_hoch 3;
BA_ "GenSigSwitchedByIgnition" SG_ 1171 MF_FH_FT_hoch 0;
BA_ "GenSigSendType" SG_ 1171 MF_FH_FT_tief 3;
BA_ "GenSigSwitchedByIgnition" SG_ 1171 MF_FH_FT_tief 0;
BA_ "GenSigSendType" SG_ 1171 MF_Frontintervall 3;
BA_ "GenSigSwitchedByIgnition" SG_ 1171 MF_Frontintervall 0;
BA_ "GenSigSendType" SG_ 1171 MF_Frontwaschen 3;
BA_ "GenSigSwitchedByIgnition" SG_ 1171 MF_Frontwaschen 0;
BA_ "GenSigSendType" SG_ 1171 MF_FT_entriegeln 3;
BA_ "GenSigSwitchedByIgnition" SG_ 1171 MF_FT_entriegeln 0;
BA_ "GenSigSendType" SG_ 1171 MF_FT_verriegeln 3;
BA_ "GenSigSwitchedByIgnition" SG_ 1171 MF_FT_verriegeln 0;
BA_ "GenSigSendType" SG_ 1171 MF_Fussraumbel 3;
BA_ "GenSigSwitchedByIgnition" SG_ 1171 MF_Fussraumbel 0;
BA_ "GenSigSendType" SG_ 1171 MF_HBFS_entriegeln 3;
BA_ "GenSigSwitchedByIgnition" SG_ 1171 MF_HBFS_entriegeln 0;
BA_ "GenSigSendType" SG_ 1171 MF_HBFS_verriegeln 3;
BA_ "GenSigSwitchedByIgnition" SG_ 1171 MF_HBFS_verriegeln 0;
BA_ "GenSigSendType" SG_ 1171 MF_Heckintervall 3;
BA_ "GenSigSwitchedByIgnition" SG_ 1171 MF_Heckintervall 0;
BA_ "GenSigSendType" SG_ 1171 MF_Heckwaschen 3;
BA_ "GenSigSwitchedByIgnition" SG_ 1171 MF_Heckwaschen 0;
BA_ "GenSigSendType" SG_ 1171 MF_HFS_entriegeln 3;
BA_ "GenSigSwitchedByIgnition" SG_ 1171 MF_HFS_entriegeln 0;
BA_ "GenSigSendType" SG_ 1171 MF_HFS_verriegeln 3;
BA_ "GenSigSwitchedByIgnition" SG_ 1171 MF_HFS_verriegeln 0;
BA_ "GenSigSendType" SG_ 1171 MF_Innenraumbel 3;
BA_ "GenSigSwitchedByIgnition" SG_ 1171 MF_Innenraumbel 0;
BA_ "GenSigSendType" SG_ 1171 MF_Innenraumbel_Unterdrueck 3;
BA_ "GenSigSwitchedByIgnition" SG_ 1171 MF_Innenraumbel_Unterdrueck 0;
BA_ "GenSigSendType" SG_ 1171 MF_interm_Fahrlicht 3;
BA_ "GenSigSwitchedByIgnition" SG_ 1171 MF_interm_Fahrlicht 0;
BA_ "GenSigSendType" SG_ 1171 MF_interm_Fernlicht 3;
BA_ "GenSigSwitchedByIgnition" SG_ 1171 MF_interm_Fernlicht 0;
BA_ "GenSigSendType" SG_ 1171 MF_interm_Takt 3;
BA_ "GenSigSwitchedByIgnition" SG_ 1171 MF_interm_Takt 0;
BA_ "GenSigSendType" SG_ 1171 MF_Laderelais 3;
BA_ "GenSigSwitchedByIgnition" SG_ 1171 MF_Laderelais 0;
BA_ "GenSigSendType" SG_ 1171 MF_Lichthupe 3;
BA_ "GenSigSwitchedByIgnition" SG_ 1171 MF_Lichthupe 0;
BA_ "GenSigSendType" SG_ 1171 MF_Motorweiterlauf 3;
BA_ "GenSigSwitchedByIgnition" SG_ 1171 MF_Motorweiterlauf 0;
BA_ "GenSigSendType" SG_ 1171 MF_nachtr_Stopp_Anf 0;
BA_ "GenSigSwitchedByIgnition" SG_ 1171 MF_nachtr_Stopp_Anf 0;
BA_ "GenSigSendType" SG_ 1171 MF_Notstart 3;
BA_ "GenSigSwitchedByIgnition" SG_ 1171 MF_Notstart 0;
BA_ "GenSigSendType" SG_ 1171 MF_Schluessel_scan 3;
BA_ "GenSigSwitchedByIgnition" SG_ 1171 MF_Schluessel_scan 0;
BA_ "GenSigSendType" SG_ 1171 MF_Signalhorn 3;
BA_ "GenSigSwitchedByIgnition" SG_ 1171 MF_Signalhorn 0;
BA_ "GenSigSendType" SG_ 1171 MF_Standlicht 3;
BA_ "GenSigSwitchedByIgnition" SG_ 1171 MF_Standlicht 0;
BA_ "GenSigSendType" SG_ 1171 MF_StartStopp_Info 0;
BA_ "GenSigSwitchedByIgnition" SG_ 1171 MF_StartStopp_Info 0;
BA_ "GenSigSendType" SG_ 1171 MF_Summer 3;
BA_ "GenSigSwitchedByIgnition" SG_ 1171 MF_Summer 0;
BA_ "GenSigSendType" SG_ 1171 MF_TFL_Abschaltung 3;
BA_ "GenSigSwitchedByIgnition" SG_ 1171 MF_TFL_Abschaltung 0;
BA_ "GenSigSendType" SG_ 1171 MF_Tippwischen 3;
BA_ "GenSigSwitchedByIgnition" SG_ 1171 MF_Tippwischen 0;
BA_ "GenSigSendType" SG_ 1171 MF_Tuerentriegelung_hinten 3;
BA_ "GenSigSwitchedByIgnition" SG_ 1171 MF_Tuerentriegelung_hinten 0;
BA_ "GenSigSendType" SG_ 1171 MF_Variante 3;
BA_ "GenSigSwitchedByIgnition" SG_ 1171 MF_Variante 0;
BA_ "GenSigSendType" SG_ 1171 MF_Warnblinker 3;
BA_ "GenSigSwitchedByIgnition" SG_ 1171 MF_Warnblinker 0;
BA_ "GenSigSendType" SG_ 1171 MF_Wischerstufe_1 3;
BA_ "GenSigSwitchedByIgnition" SG_ 1171 MF_Wischerstufe_1 0;
BA_ "GenSigSendType" SG_ 1171 MF_Wischerstufe_2 3;
BA_ "GenSigSwitchedByIgnition" SG_ 1171 MF_Wischerstufe_2 0;
BA_ "GenSigSendType" SG_ 1171 MF_ZV_Lock 3;
BA_ "GenSigSwitchedByIgnition" SG_ 1171 MF_ZV_Lock 0;
BA_ "GenSigFuncType" SG_ 1171 MFG_01_BZ 1;
BA_ "GenSigSendType" SG_ 1171 MFG_01_BZ 0;
BA_ "GenSigSwitchedByIgnition" SG_ 1171 MFG_01_BZ 0;
BA_ "GenSigFuncType" SG_ 1171 MFG_01_CRC 2;
BA_ "GenSigSendType" SG_ 1171 MFG_01_CRC 0;
BA_ "GenSigSwitchedByIgnition" SG_ 1171 MFG_01_CRC 0;
BA_ "GenSigSendType" SG_ 1164 MF_2BatSOCzugering 0;
BA_ "GenSigSendType" SG_ 1164 MF_2BattAb 0;
BA_ "GenSigSendType" SG_ 1164 MF_2BattHlkAnf 0;
BA_ "GenSigSendType" SG_ 1164 MF_2BattLadWarn 0;
BA_ "GenSigSendType" SG_ 1164 MF_2BattLlaAnf 0;
BA_ "GenSigSendType" SG_ 1164 MF_2BattSpannungsAnf 0;
BA_ "Fehlerwert" SG_ 1164 MF_Batteriediagnose 7;
BA_ "GenSigSendType" SG_ 1164 MF_Batteriediagnose 0;
BA_ "GenSigSwitchedByIgnition" SG_ 1164 MF_Batteriediagnose 0;
BA_ "GenSigSendType" SG_ 1164 MF_Blinker_L_Sta 3;
BA_ "GenSigSwitchedByIgnition" SG_ 1164 MF_Blinker_L_Sta 0;
BA_ "GenSigSendType" SG_ 1164 MF_Blinker_R_Sta 3;
BA_ "GenSigSwitchedByIgnition" SG_ 1164 MF_Blinker_R_Sta 0;
BA_ "GenSigSendType" SG_ 1164 MF_ExterneLadungWarn 0;
BA_ "GenSigSendType" SG_ 1164 MF_Fahrerhinweis 0;
BA_ "GenSigSendType" SG_ 1164 MF_Generatordiagnose 0;
BA_ "GenSigStartValue" SG_ 1164 MF_Generatordiagnose 3;
BA_ "GenSigSwitchedByIgnition" SG_ 1164 MF_Generatordiagnose 0;
BA_ "GenSigSendType" SG_ 1164 MF_Heck_entriegeln 0;
BA_ "GenSigSendType" SG_ 1164 MF_Heck_verriegeln 0;
BA_ "GenSigSendType" SG_ 1164 MF_interm_Nebelscheinwerfer 0;
BA_ "GenSigSwitchedByIgnition" SG_ 1164 MF_interm_Nebelscheinwerfer 0;
BA_ "GenSigSendType" SG_ 1164 MF_Lampenausfall 0;
BA_ "GenSigSwitchedByIgnition" SG_ 1164 MF_Lampenausfall 0;
BA_ "GenSigSendType" SG_ 1164 MF_LSH_Abschaltstufe 0;
BA_ "GenSigSwitchedByIgnition" SG_ 1164 MF_LSH_Abschaltstufe 0;
BA_ "GenSigSendType" SG_ 1164 MF_LSH_Einschaltverbot 0;
BA_ "GenSigSwitchedByIgnition" SG_ 1164 MF_LSH_Einschaltverbot 0;
BA_ "Fehlerwert" SG_ 1164 MF_LSH_Zielzeit 15;
BA_ "GenSigSendType" SG_ 1164 MF_LSH_Zielzeit 0;
BA_ "GenSigStartValue" SG_ 1164 MF_LSH_Zielzeit 14;
BA_ "GenSigSwitchedByIgnition" SG_ 1164 MF_LSH_Zielzeit 0;
BA_ "GenSigSendType" SG_ 1164 MF_NotStartAktiv 0;
BA_ "GenSigSendType" SG_ 1164 MF_Radiomute 3;
BA_ "GenSigSwitchedByIgnition" SG_ 1164 MF_Radiomute 0;
BA_ "GenSigSendType" SG_ 1164 MF_Relais_2_Batterie 3;
BA_ "GenSigSwitchedByIgnition" SG_ 1164 MF_Relais_2_Batterie 0;
BA_ "GenSigSendType" SG_ 1164 MF_Tuerverriegelung_hinten 3;
BA_ "GenSigSwitchedByIgnition" SG_ 1164 MF_Tuerverriegelung_hinten 0;
BA_ "GenSigSendType" SG_ 1164 MF_ZV_Unlock 0;
BA_ "GenSigSwitchedByIgnition" SG_ 1164 MF_ZV_Unlock 0;
BA_ "GenSigSendType" SG_ 1164 MFG_AppConnect_Anf 4;
BA_ "GenSigSwitchedByIgnition" SG_ 1164 MFG_AppConnect_Anf 0;
BA_ "GenSigSendType" SG_ 1164 MFG_Klappe_Status 0;
BA_ "GenSigSendType" SG_ 817 MFL_Dummy_0_Signal_1 0;
BA_ "GenSigSwitchedByIgnition" SG_ 817 MFL_Dummy_0_Signal_1 0;
BA_ "GenSigSendType" SG_ 817 MFL_Dummy_0_Signal_3 0;
BA_ "GenSigSwitchedByIgnition" SG_ 817 MFL_Dummy_0_Signal_3 0;
BA_ "Fehlerwert" SG_ 817 MFL_ECU_Err 1;
BA_ "GenSigSendType" SG_ 817 MFL_ECU_Err 0;
BA_ "GenSigSwitchedByIgnition" SG_ 817 MFL_ECU_Err 0;
BA_ "GenSigSendType" SG_ 817 MFL_Eventcode_1 0;
BA_ "GenSigSwitchedByIgnition" SG_ 817 MFL_Eventcode_1 0;
BA_ "GenSigSendType" SG_ 817 MFL_Eventcode_2 0;
BA_ "GenSigSwitchedByIgnition" SG_ 817 MFL_Eventcode_2 0;
BA_ "Fehlerwert" SG_ 817 MFL_Fehler_Codierung 1;
BA_ "GenSigSendType" SG_ 817 MFL_Fehler_Codierung 0;
BA_ "GenSigSwitchedByIgnition" SG_ 817 MFL_Fehler_Codierung 0;
BA_ "GenSigSendType" SG_ 817 MFL_Lokalaktiv 0;
BA_ "GenSigSwitchedByIgnition" SG_ 817 MFL_Lokalaktiv 0;
BA_ "Fehlerwert" SG_ 817 MFL_LR_HZG_Err 1;
BA_ "GenSigSendType" SG_ 817 MFL_LR_HZG_Err 0;
BA_ "GenSigSwitchedByIgnition" SG_ 817 MFL_LR_HZG_Err 0;
BA_ "GenSigSendType" SG_ 817 MFL_LR_HZG_Status 0;
BA_ "GenSigSwitchedByIgnition" SG_ 817 MFL_LR_HZG_Status 0;
BA_ "GenSigSendType" SG_ 817 MFL_M_Taste 0;
BA_ "GenSigFuncType" SG_ 817 MFL_Marke 8;
BA_ "GenSigSendType" SG_ 817 MFL_Marke 0;
BA_ "GenSigSwitchedByIgnition" SG_ 817 MFL_Marke 0;
BA_ "GenSigSendType" SG_ 817 MFL_Paddle_Verbau 0;
BA_ "GenSigSwitchedByIgnition" SG_ 817 MFL_Paddle_Verbau 0;
BA_ "Fehlerwert" SG_ 817 MFL_Response_Err 1;
BA_ "GenSigSendType" SG_ 817 MFL_Response_Err 0;
BA_ "GenSigSwitchedByIgnition" SG_ 817 MFL_Response_Err 0;
BA_ "Fehlerwert" SG_ 817 MFL_SatModul_links_Err 1;
BA_ "GenSigFuncType" SG_ 817 MFL_SatModul_links_Err 5;
BA_ "GenSigSendType" SG_ 817 MFL_SatModul_links_Err 0;
BA_ "GenSigSwitchedByIgnition" SG_ 817 MFL_SatModul_links_Err 0;
BA_ "Fehlerwert" SG_ 817 MFL_SatModul_rechts_Err 1;
BA_ "GenSigFuncType" SG_ 817 MFL_SatModul_rechts_Err 5;
BA_ "GenSigSendType" SG_ 817 MFL_SatModul_rechts_Err 0;
BA_ "GenSigSwitchedByIgnition" SG_ 817 MFL_SatModul_rechts_Err 0;
BA_ "GenSigSendType" SG_ 817 MFL_Signalhorn 5;
BA_ "GenSigSwitchedByIgnition" SG_ 817 MFL_Signalhorn 0;
BA_ "Fehlerwert" SG_ 817 MFL_Signalhorn_Err 1;
BA_ "GenSigSendType" SG_ 817 MFL_Signalhorn_Err 0;
BA_ "GenSigSwitchedByIgnition" SG_ 817 MFL_Signalhorn_Err 0;
BA_ "Fehlerwert" SG_ 817 MFL_Taste_links_Err 1;
BA_ "GenSigSendType" SG_ 817 MFL_Taste_links_Err 0;
BA_ "GenSigSwitchedByIgnition" SG_ 817 MFL_Taste_links_Err 0;
BA_ "Fehlerwert" SG_ 817 MFL_Taste_rechts_Err 1;
BA_ "GenSigSendType" SG_ 817 MFL_Taste_rechts_Err 0;
BA_ "GenSigSwitchedByIgnition" SG_ 817 MFL_Taste_rechts_Err 0;
BA_ "GenSigSendType" SG_ 817 MFL_Tastencode_1 0;
BA_ "GenSigSwitchedByIgnition" SG_ 817 MFL_Tastencode_1 0;
BA_ "GenSigSendType" SG_ 817 MFL_Tastencode_2 0;
BA_ "GenSigSwitchedByIgnition" SG_ 817 MFL_Tastencode_2 0;
BA_ "GenSigSendType" SG_ 817 MFL_Tip_Down 5;
BA_ "Fehlerwert" SG_ 817 MFL_Tip_links_Err 1;
BA_ "GenSigSendType" SG_ 817 MFL_Tip_links_Err 0;
BA_ "GenSigSwitchedByIgnition" SG_ 817 MFL_Tip_links_Err 0;
BA_ "Fehlerwert" SG_ 817 MFL_Tip_rechts_Err 1;
BA_ "GenSigSendType" SG_ 817 MFL_Tip_rechts_Err 0;
BA_ "GenSigSwitchedByIgnition" SG_ 817 MFL_Tip_rechts_Err 0;
BA_ "GenSigSendType" SG_ 817 MFL_Tip_Up 5;
BA_ "GenSigSendType" SG_ 817 MFL_Toggle 0;
BA_ "GenSigSwitchedByIgnition" SG_ 817 MFL_Toggle 0;
BA_ "GenSigFuncType" SG_ 817 MFL_Variante 8;
BA_ "GenSigSendType" SG_ 817 MFL_Variante 0;
BA_ "GenSigSwitchedByIgnition" SG_ 817 MFL_Variante 0;
BA_ "GenSigSendType" SG_ 817 MFL_Zaehler 0;
BA_ "GenSigSwitchedByIgnition" SG_ 817 MFL_Zaehler 0;
BA_ "GenSigSendType" SG_ 560 MFL_Beruehrungserkennung 3;
BA_ "GenSigSwitchedByIgnition" SG_ 560 MFL_Beruehrungserkennung 0;
BA_ "Fehlerwert" SG_ 560 MFL_Touch_Event 15;
BA_ "GenSigSendType" SG_ 560 MFL_Touch_Event 3;
BA_ "GenSigSwitchedByIgnition" SG_ 560 MFL_Touch_Event 0;
BA_ "GenSigSendType" SG_ 2463978751 MFL_Taste_SDS_benoetigt 0;
BA_ "GenSigSwitchedByIgnition" SG_ 2463978751 MFL_Taste_SDS_benoetigt 0;
BA_ "GenSigSendType" SG_ 2463978751 MFL_Tasten_UpDownOK_benoetigt 0;
BA_ "GenSigSwitchedByIgnition" SG_ 2463978751 MFL_Tasten_UpDownOK_benoetigt 0;
BA_ "GenSigSendType" SG_ 2463978751 MFL_Tasten_Volume_benoetigt 0;
BA_ "GenSigSwitchedByIgnition" SG_ 2463978751 MFL_Tasten_Volume_benoetigt 0;
BA_ "GenSigSendType" SG_ 2463978751 MFL_Vibrationsimpuls_links 4;
BA_ "GenSigSwitchedByIgnition" SG_ 2463978751 MFL_Vibrationsimpuls_links 0;
BA_ "GenSigSendType" SG_ 2463978751 MFL_Vibrationsimpuls_rechts 4;
BA_ "GenSigSwitchedByIgnition" SG_ 2463978751 MFL_Vibrationsimpuls_rechts 0;
BA_ "GenSigSendType" SG_ 1471 MFL_Eventcode_1 1;
BA_ "GenSigSwitchedByIgnition" SG_ 1471 MFL_Eventcode_1 0;
BA_ "GenSigSendType" SG_ 1471 MFL_Eventcode_2 1;
BA_ "GenSigSwitchedByIgnition" SG_ 1471 MFL_Eventcode_2 0;
BA_ "GenSigFuncType" SG_ 1471 MFL_Marke 8;
BA_ "GenSigSendType" SG_ 1471 MFL_Marke 1;
BA_ "GenSigSwitchedByIgnition" SG_ 1471 MFL_Marke 0;
BA_ "GenSigSendType" SG_ 1471 MFL_Tastencode_1 1;
BA_ "GenSigSwitchedByIgnition" SG_ 1471 MFL_Tastencode_1 0;
BA_ "GenSigSendType" SG_ 1471 MFL_Tastencode_2 1;
BA_ "GenSigSwitchedByIgnition" SG_ 1471 MFL_Tastencode_2 0;
BA_ "GenSigFuncType" SG_ 1471 MFL_Variante 8;
BA_ "GenSigSendType" SG_ 1471 MFL_Variante 1;
BA_ "GenSigSwitchedByIgnition" SG_ 1471 MFL_Variante 0;
BA_ "GenSigSendType" SG_ 958 MO_Aussp_Anlass 3;
BA_ "GenSigSwitchedByIgnition" SG_ 958 MO_Aussp_Anlass 0;
BA_ "GenSigSendType" SG_ 958 MO_BKV_Unterdruckwarnung 0;
BA_ "GenSigSwitchedByIgnition" SG_ 958 MO_BKV_Unterdruckwarnung 0;
BA_ "GenSigSendType" SG_ 958 MO_BLS 3;
BA_ "GenSigSwitchedByIgnition" SG_ 958 MO_BLS 0;
BA_ "GenSigSendType" SG_ 958 MO_BMS_NV_Anf_stuetzen 3;
BA_ "GenSigSwitchedByIgnition" SG_ 958 MO_BMS_NV_Anf_stuetzen 0;
BA_ "GenSigSendType" SG_ 958 MO_EKlKomLeiRed 0;
BA_ "GenSigSwitchedByIgnition" SG_ 958 MO_EKlKomLeiRed 0;
BA_ "GenSigSendType" SG_ 958 MO_Ext_E_Fahrt_aktiv 3;
BA_ "GenSigSwitchedByIgnition" SG_ 958 MO_Ext_E_Fahrt_aktiv 0;
BA_ "NWM-WakeupAllowed" SG_ 958 MO_Ext_E_Fahrt_aktiv 1;
BA_ "GenSigSendType" SG_ 958 MO_Fahrer_bremst 3;
BA_ "GenSigSwitchedByIgnition" SG_ 958 MO_Fahrer_bremst 0;
BA_ "GenSigSendType" SG_ 958 MO_FMAus_aktiv 3;
BA_ "GenSigSwitchedByIgnition" SG_ 958 MO_FMAus_aktiv 0;
BA_ "GenSigSendType" SG_ 958 MO_FMAus_Startvariante 3;
BA_ "GenSigSwitchedByIgnition" SG_ 958 MO_FMAus_Startvariante 0;
BA_ "GenSigSendType" SG_ 958 MO_Freig_Anlass 3;
BA_ "GenSigSwitchedByIgnition" SG_ 958 MO_Freig_Anlass 0;
BA_ "GenSigSendType" SG_ 958 MO_Freig_Reku 0;
BA_ "GenSigSwitchedByIgnition" SG_ 958 MO_Freig_Reku 0;
BA_ "GenSigSendType" SG_ 958 MO_Freigabe_Segeln 0;
BA_ "GenSigSwitchedByIgnition" SG_ 958 MO_Freigabe_Segeln 0;
BA_ "Fehlerwert" SG_ 958 MO_Gangposition 15;
BA_ "GenSigSendType" SG_ 958 MO_Gangposition 3;
BA_ "GenSigStartValue" SG_ 958 MO_Gangposition 14;
BA_ "GenSigSwitchedByIgnition" SG_ 958 MO_Gangposition 0;
BA_ "GenSigSendType" SG_ 958 MO_Handshake_STH 0;
BA_ "GenSigSwitchedByIgnition" SG_ 958 MO_Handshake_STH 0;
BA_ "GenSigSendType" SG_ 958 MO_HYB_Fahrbereitschaft 0;
BA_ "GenSigSwitchedByIgnition" SG_ 958 MO_HYB_Fahrbereitschaft 0;
BA_ "GenSigSendType" SG_ 958 MO_HYB_VM_aktiv 3;
BA_ "GenSigSwitchedByIgnition" SG_ 958 MO_HYB_VM_aktiv 0;
BA_ "GenSigSendType" SG_ 958 MO_Interlock 3;
BA_ "GenSigSwitchedByIgnition" SG_ 958 MO_Interlock 0;
BA_ "GenSigSendType" SG_ 958 MO_Kickdown 3;
BA_ "GenSigSwitchedByIgnition" SG_ 958 MO_Kickdown 0;
BA_ "GenSigSendType" SG_ 958 MO_Kl_50 3;
BA_ "GenSigSwitchedByIgnition" SG_ 958 MO_Kl_50 0;
BA_ "GenSigSendType" SG_ 958 MO_Kl_75 3;
BA_ "GenSigSwitchedByIgnition" SG_ 958 MO_Kl_75 0;
BA_ "GenSigSendType" SG_ 958 MO_Klima_Eingr 3;
BA_ "GenSigSwitchedByIgnition" SG_ 958 MO_Klima_Eingr 0;
BA_ "GenSigSendType" SG_ 958 MO_Konsistenz_Bremsped 3;
BA_ "GenSigSwitchedByIgnition" SG_ 958 MO_Konsistenz_Bremsped 0;
BA_ "GenSigSendType" SG_ 958 MO_Kuppl_schalter 3;
BA_ "GenSigSwitchedByIgnition" SG_ 958 MO_Kuppl_schalter 0;
BA_ "GenSigSendType" SG_ 958 MO_Motor_laeuft 3;
BA_ "GenSigSwitchedByIgnition" SG_ 958 MO_Motor_laeuft 0;
BA_ "GenSigSendType" SG_ 958 MO_PTC_Status 0;
BA_ "GenSigSwitchedByIgnition" SG_ 958 MO_PTC_Status 0;
BA_ "GenSigSendType" SG_ 958 MO_QBit_Fahrer_bremst 3;
BA_ "GenSigStartValue" SG_ 958 MO_QBit_Fahrer_bremst 1;
BA_ "GenSigSwitchedByIgnition" SG_ 958 MO_QBit_Fahrer_bremst 0;
BA_ "GenSigSendType" SG_ 958 MO_QBit_Gangposition 3;
BA_ "GenSigStartValue" SG_ 958 MO_QBit_Gangposition 1;
BA_ "GenSigSwitchedByIgnition" SG_ 958 MO_QBit_Gangposition 0;
BA_ "GenSigSendType" SG_ 958 MO_QBit_KL_75 3;
BA_ "GenSigStartValue" SG_ 958 MO_QBit_KL_75 1;
BA_ "GenSigSwitchedByIgnition" SG_ 958 MO_QBit_KL_75 0;
BA_ "GenSigSendType" SG_ 958 MO_Remotestart_Betrieb 3;
BA_ "GenSigSwitchedByIgnition" SG_ 958 MO_Remotestart_Betrieb 0;
BA_ "GenSigSendType" SG_ 958 MO_Remotestart_moeglich 0;
BA_ "GenSigSwitchedByIgnition" SG_ 958 MO_Remotestart_moeglich 0;
BA_ "GenSigSendType" SG_ 958 MO_Signalquelle_Gangposition 0;
BA_ "GenSigSwitchedByIgnition" SG_ 958 MO_Signalquelle_Gangposition 0;
BA_ "GenSigSendType" SG_ 958 MO_StartStopp_Fahrerwunsch 0;
BA_ "GenSigSwitchedByIgnition" SG_ 958 MO_StartStopp_Fahrerwunsch 0;
BA_ "GenSigSendType" SG_ 958 MO_StartStopp_Motorstopp 3;
BA_ "GenSigSwitchedByIgnition" SG_ 958 MO_StartStopp_Motorstopp 0;
BA_ "GenSigSendType" SG_ 958 MO_StartStopp_Status 0;
BA_ "GenSigSwitchedByIgnition" SG_ 958 MO_StartStopp_Status 0;
BA_ "GenSigSendType" SG_ 958 MO_StartStopp_Wiederstart 3;
BA_ "GenSigSwitchedByIgnition" SG_ 958 MO_StartStopp_Wiederstart 0;
BA_ "GenSigSendType" SG_ 958 MO_StartVorauss_erfuellt 3;
BA_ "GenSigStartValue" SG_ 958 MO_StartVorauss_erfuellt 1;
BA_ "GenSigSwitchedByIgnition" SG_ 958 MO_StartVorauss_erfuellt 0;
BA_ "GenSigSendType" SG_ 958 MO_Timeout_ESP 3;
BA_ "GenSigSwitchedByIgnition" SG_ 958 MO_Timeout_ESP 0;
BA_ "GenSigSendType" SG_ 958 MO_Zylinderabschaltung 3;
BA_ "GenSigSwitchedByIgnition" SG_ 958 MO_Zylinderabschaltung 0;
BA_ "GenSigFuncType" SG_ 958 Motor_14_BZ 1;
BA_ "GenSigSendType" SG_ 958 Motor_14_BZ 0;
BA_ "GenSigSwitchedByIgnition" SG_ 958 Motor_14_BZ 0;
BA_ "GenSigFuncType" SG_ 958 Motor_14_CRC 2;
BA_ "GenSigSendType" SG_ 958 Motor_14_CRC 0;
BA_ "GenSigSwitchedByIgnition" SG_ 958 Motor_14_CRC 0;
BA_ "GenSigSendType" SG_ 1648 MO1_Freigabe_Info_WFS 3;
BA_ "GenSigSwitchedByIgnition" SG_ 1648 MO1_Freigabe_Info_WFS 0;
BA_ "GenSigSendType" SG_ 1648 MO1_Freigabe_Verfallsinfo_WFS 3;
BA_ "GenSigSwitchedByIgnition" SG_ 1648 MO1_Freigabe_Verfallsinfo_WFS 0;
BA_ "GenSigSendType" SG_ 1648 MO1_Sperr_Info_WFS 3;
BA_ "GenSigSwitchedByIgnition" SG_ 1648 MO1_Sperr_Info_WFS 0;
BA_ "GenSigSendType" SG_ 1648 MO_Abstellzeit 0;
BA_ "GenSigStartValue" SG_ 1648 MO_Abstellzeit 254;
BA_ "GenSigSwitchedByIgnition" SG_ 1648 MO_Abstellzeit 0;
BA_ "GenSigSendType" SG_ 1648 MO_Abstellzeit_Status 0;
BA_ "GenSigSwitchedByIgnition" SG_ 1648 MO_Abstellzeit_Status 0;
BA_ "GenSigSendType" SG_ 1648 MO_ANC_Kennfeld_Anf 3;
BA_ "GenSigSwitchedByIgnition" SG_ 1648 MO_ANC_Kennfeld_Anf 0;
BA_ "GenSigSendType" SG_ 1648 MO_Anzahl_Abgesch_Zyl 3;
BA_ "GenSigSwitchedByIgnition" SG_ 1648 MO_Anzahl_Abgesch_Zyl 0;
BA_ "GenSigSendType" SG_ 1648 MO_Bremslicht_Reku 3;
BA_ "GenSigSwitchedByIgnition" SG_ 1648 MO_Bremslicht_Reku 0;
BA_ "GenSigSendType" SG_ 1648 MO_Drehzahl_Warnung 0;
BA_ "GenSigSwitchedByIgnition" SG_ 1648 MO_Drehzahl_Warnung 0;
BA_ "GenSigSendType" SG_ 1648 MO_EPCL 3;
BA_ "GenSigSwitchedByIgnition" SG_ 1648 MO_EPCL 0;
BA_ "GenSigSendType" SG_ 1648 MO_Ethanol_BS_Texte 0;
BA_ "GenSigSwitchedByIgnition" SG_ 1648 MO_Ethanol_BS_Texte 0;
BA_ "GenSigFuncType" SG_ 1648 MO_Fahrzeugtyp 8;
BA_ "GenSigSendType" SG_ 1648 MO_Fahrzeugtyp 0;
BA_ "GenSigSwitchedByIgnition" SG_ 1648 MO_Fahrzeugtyp 0;
BA_ "GenSigSendType" SG_ 1648 MO_Fehler_Zylabsch 0;
BA_ "GenSigSwitchedByIgnition" SG_ 1648 MO_Fehler_Zylabsch 0;
BA_ "GenSigSendType" SG_ 1648 MO_Hybrid_StartStopp_LED 3;
BA_ "GenSigSwitchedByIgnition" SG_ 1648 MO_Hybrid_StartStopp_LED 0;
BA_ "GenSigFuncType" SG_ 1648 MO_max_Ladedruck 8;
BA_ "GenSigSendType" SG_ 1648 MO_max_Ladedruck 0;
BA_ "GenSigSwitchedByIgnition" SG_ 1648 MO_max_Ladedruck 0;
BA_ "GenSigSendType" SG_ 1648 MO_NMAX_Schaltanzeige 3;
BA_ "GenSigSwitchedByIgnition" SG_ 1648 MO_NMAX_Schaltanzeige 0;
BA_ "GenSigSendType" SG_ 1648 MO_obere_Drehzahlgrenze 0;
BA_ "GenSigSwitchedByIgnition" SG_ 1648 MO_obere_Drehzahlgrenze 0;
BA_ "GenSigSendType" SG_ 1648 MO_StartStopp_PopUp 3;
BA_ "GenSigSwitchedByIgnition" SG_ 1648 MO_StartStopp_PopUp 0;
BA_ "GenSigSendType" SG_ 1648 MO_Zylabsch_Texte 0;
BA_ "GenSigSwitchedByIgnition" SG_ 1648 MO_Zylabsch_Texte 0;
BA_ "GenSigSendType" SG_ 1648 MO_Zylabsch_Texte_02 3;
BA_ "GenSigSwitchedByIgnition" SG_ 1648 MO_Zylabsch_Texte_02 0;
BA_ "GenSigSendType" SG_ 967 MO_E_Mode 0;
BA_ "GenSigSwitchedByIgnition" SG_ 967 MO_E_Mode 0;
BA_ "GenSigSendType" SG_ 967 MO_E_Texte 0;
BA_ "GenSigSwitchedByIgnition" SG_ 967 MO_E_Texte 0;
BA_ "GenSigSendType" SG_ 967 MO_E_Warnungen 0;
BA_ "GenSigSwitchedByIgnition" SG_ 967 MO_E_Warnungen 0;
BA_ "GenSigSendType" SG_ 967 MO_EFLEX_Lampe 0;
BA_ "GenSigSwitchedByIgnition" SG_ 967 MO_EFLEX_Lampe 0;
BA_ "GenSigSendType" SG_ 967 MO_Heissleuchte 0;
BA_ "GenSigSwitchedByIgnition" SG_ 967 MO_Heissleuchte 0;
BA_ "GenSigSendType" SG_ 967 MO_ITM_Warnung_Pumpe 0;
BA_ "GenSigSwitchedByIgnition" SG_ 967 MO_ITM_Warnung_Pumpe 0;
BA_ "Fehlerwert" SG_ 967 MO_KJS_nicht_bereit 1;
BA_ "GenSigSendType" SG_ 967 MO_KJS_nicht_bereit 0;
BA_ "GenSigSwitchedByIgnition" SG_ 967 MO_KJS_nicht_bereit 0;
BA_ "Fehlerwert" SG_ 967 MO_Kuehlerluefter_1 127;
BA_ "GenSigStartValue" SG_ 967 MO_Kuehlerluefter_1 126;
BA_ "GenSigSwitchedByIgnition" SG_ 967 MO_Kuehlerluefter_1 0;
BA_ "Fehlerwert" SG_ 967 MO_Kuehlerluefter_2 127;
BA_ "GenSigStartValue" SG_ 967 MO_Kuehlerluefter_2 126;
BA_ "GenSigSwitchedByIgnition" SG_ 967 MO_Kuehlerluefter_2 0;
BA_ "GenSigSendType" SG_ 967 MO_Kuehlerluefter_MUX 0;
BA_ "GenSigSwitchedByIgnition" SG_ 967 MO_Kuehlerluefter_MUX 0;
BA_ "GenSigSendType" SG_ 967 MO_OBD2_Lampe 0;
BA_ "GenSigSwitchedByIgnition" SG_ 967 MO_OBD2_Lampe 0;
BA_ "GenSigSendType" SG_ 967 MO_Oelwarnung_max 0;
BA_ "GenSigSwitchedByIgnition" SG_ 967 MO_Oelwarnung_max 0;
BA_ "GenSigSendType" SG_ 967 MO_Partikel_Lampe 0;
BA_ "GenSigSwitchedByIgnition" SG_ 967 MO_Partikel_Lampe 0;
BA_ "GenSigSendType" SG_ 967 MO_RedFahrleistung_Lampe 0;
BA_ "GenSigSwitchedByIgnition" SG_ 967 MO_RedFahrleistung_Lampe 0;
BA_ "GenSigSendType" SG_ 967 MO_Systemlampe 0;
BA_ "GenSigSwitchedByIgnition" SG_ 967 MO_Systemlampe 0;
BA_ "GenSigSendType" SG_ 967 MO_Tankdeckel_Lampe 0;
BA_ "GenSigSwitchedByIgnition" SG_ 967 MO_Tankdeckel_Lampe 0;
BA_ "GenSigSendType" SG_ 967 MO_Text_Motorstart 0;
BA_ "GenSigSwitchedByIgnition" SG_ 967 MO_Text_Motorstart 0;
BA_ "GenSigSendType" SG_ 967 MO_Text_Partikelfil_Reg 0;
BA_ "GenSigSwitchedByIgnition" SG_ 967 MO_Text_Partikelfil_Reg 0;
BA_ "GenSigSendType" SG_ 967 MO_Text_Tankdeckelwarn 0;
BA_ "GenSigSwitchedByIgnition" SG_ 967 MO_Text_Tankdeckelwarn 0;
BA_ "GenSigSendType" SG_ 967 MO_Vorglueh_Lampe 0;
BA_ "GenSigSwitchedByIgnition" SG_ 967 MO_Vorglueh_Lampe 0;
BA_ "GenSigSendType" SG_ 967 MO_Zustand_HWP 0;
BA_ "GenSigStartValue" SG_ 967 MO_Zustand_HWP 1;
BA_ "GenSigSwitchedByIgnition" SG_ 967 MO_Zustand_HWP 0;
BA_ "GenSigSendType" SG_ 967 OLEV_Oelstand_nicht_vorhanden 0;
BA_ "GenSigSwitchedByIgnition" SG_ 967 OLEV_Oelstand_nicht_vorhanden 0;
BA_ "GenSigSendType" SG_ 967 OLEV_Systemstoerung 0;
BA_ "GenSigSwitchedByIgnition" SG_ 967 OLEV_Systemstoerung 0;
BA_ "GenSigSendType" SG_ 967 WIV_Anzeige_aktiv 0;
BA_ "GenSigSwitchedByIgnition" SG_ 967 WIV_Anzeige_aktiv 0;
BA_ "GenSigSendType" SG_ 967 WIV_laufender_Motor 0;
BA_ "GenSigSwitchedByIgnition" SG_ 967 WIV_laufender_Motor 0;
BA_ "GenSigSendType" SG_ 967 WIV_nachfuellanzeige_ein 0;
BA_ "GenSigSwitchedByIgnition" SG_ 967 WIV_nachfuellanzeige_ein 0;
BA_ "GenSigSendType" SG_ 967 WIV_nicht_betriebswarm 0;
BA_ "GenSigSwitchedByIgnition" SG_ 967 WIV_nicht_betriebswarm 0;
BA_ "GenSigSendType" SG_ 967 WIV_Oeldr_Warn_Motor 0;
BA_ "GenSigSwitchedByIgnition" SG_ 967 WIV_Oeldr_Warn_Motor 0;
BA_ "GenSigSendType" SG_ 967 WIV_Oeldyn_avl 0;
BA_ "GenSigSwitchedByIgnition" SG_ 967 WIV_Oeldyn_avl 0;
BA_ "GenSigSendType" SG_ 967 WIV_Oelmenge 0;
BA_ "GenSigSwitchedByIgnition" SG_ 967 WIV_Oelmenge 0;
BA_ "GenSigSendType" SG_ 967 WIV_Oelmin_Warn 0;
BA_ "GenSigSwitchedByIgnition" SG_ 967 WIV_Oelmin_Warn 0;
BA_ "GenSigSendType" SG_ 967 WIV_Oelstand 0;
BA_ "GenSigSwitchedByIgnition" SG_ 967 WIV_Oelstand 0;
BA_ "GenSigSendType" SG_ 967 WIV_Oelstand_nicht_vorhanden 0;
BA_ "GenSigSwitchedByIgnition" SG_ 967 WIV_Oelstand_nicht_vorhanden 0;
BA_ "GenSigSendType" SG_ 967 WIV_Oelsystem_aktiv 0;
BA_ "GenSigSwitchedByIgnition" SG_ 967 WIV_Oelsystem_aktiv 0;
BA_ "GenSigSendType" SG_ 967 WIV_Schieflage 0;
BA_ "GenSigSwitchedByIgnition" SG_ 967 WIV_Schieflage 0;
BA_ "GenSigSendType" SG_ 967 WIV_Sensorfehler 0;
BA_ "GenSigSwitchedByIgnition" SG_ 967 WIV_Sensorfehler 0;
BA_ "GenSigSendType" SG_ 967 WIV_Ueberfuell_deaktiv 0;
BA_ "GenSigSwitchedByIgnition" SG_ 967 WIV_Ueberfuell_deaktiv 0;
BA_ "GenSigSendType" SG_ 967 WIV_Ueberfuell_Warn 0;
BA_ "GenSigSwitchedByIgnition" SG_ 967 WIV_Ueberfuell_Warn 0;
BA_ "GenSigSendType" SG_ 967 WIV_Unterfuell_Warn 0;
BA_ "GenSigSwitchedByIgnition" SG_ 967 WIV_Unterfuell_Warn 0;
BA_ "GenSigFuncType" SG_ 966 SOK_Motor_26_Signatur 15;
BA_ "GenSigSendType" SG_ 966 SOK_Motor_26_Signatur 0;
BA_ "GenSigSwitchedByIgnition" SG_ 966 SOK_Motor_26_Signatur 0;
BA_ "GenSigSendType" SG_ 706 FDR_Warnung_ALR 3;
BA_ "GenSigSwitchedByIgnition" SG_ 706 FDR_Warnung_ALR 0;
BA_ "GenSigSendType" SG_ 706 MO_ADR_Status 3;
BA_ "GenSigSwitchedByIgnition" SG_ 706 MO_ADR_Status 0;
BA_ "GenSigSendType" SG_ 706 MO_AGA_Sound_Texte 3;
BA_ "GenSigSwitchedByIgnition" SG_ 706 MO_AGA_Sound_Texte 0;
BA_ "GenSigSendType" SG_ 706 MO_Anz_Kuehlerluefter 0;
BA_ "GenSigSwitchedByIgnition" SG_ 706 MO_Anz_Kuehlerluefter 0;
BA_ "GenSigSendType" SG_ 706 MO_Anzeige_FMAus_Text 3;
BA_ "GenSigSwitchedByIgnition" SG_ 706 MO_Anzeige_FMAus_Text 0;
BA_ "GenSigSendType" SG_ 706 MO_Anzeige_StSt_Symbol 3;
BA_ "GenSigSwitchedByIgnition" SG_ 706 MO_Anzeige_StSt_Symbol 0;
BA_ "GenSigSendType" SG_ 706 MO_Anzeige_StSt_Text 3;
BA_ "GenSigSwitchedByIgnition" SG_ 706 MO_Anzeige_StSt_Text 0;
BA_ "GenSigSendType" SG_ 706 MO_ElAntrieb_Abschleppwarnung 3;
BA_ "GenSigSwitchedByIgnition" SG_ 706 MO_ElAntrieb_Abschleppwarnung 0;
BA_ "GenSigSendType" SG_ 706 MO_EM_Ueberhitzungswarnung 3;
BA_ "GenSigSwitchedByIgnition" SG_ 706 MO_EM_Ueberhitzungswarnung 0;
BA_ "Fehlerwert" SG_ 706 MO_Powermeter_Dauer_Grenze 4095;
BA_ "GenSigSendType" SG_ 706 MO_Powermeter_Dauer_Grenze 3;
BA_ "GenSigStartValue" SG_ 706 MO_Powermeter_Dauer_Grenze 4094;
BA_ "GenSigSwitchedByIgnition" SG_ 706 MO_Powermeter_Dauer_Grenze 0;
BA_ "GenSigSendType" SG_ 706 MO_Rekuperationsstufe 3;
BA_ "GenSigStartValue" SG_ 706 MO_Rekuperationsstufe 7;
BA_ "GenSigSwitchedByIgnition" SG_ 706 MO_Rekuperationsstufe 0;
BA_ "GenSigSendType" SG_ 706 PEA_Texte 3;
BA_ "GenSigSwitchedByIgnition" SG_ 706 PEA_Texte 0;
BA_ "GenSigSendType" SG_ 706 TSK_Einheit_vMax_FahrerInfo 0;
BA_ "GenSigSwitchedByIgnition" SG_ 706 TSK_Einheit_vMax_FahrerInfo 0;
BA_ "GenSigSendType" SG_ 706 TSK_Status_vMax_FahrerInfo 0;
BA_ "GenSigSwitchedByIgnition" SG_ 706 TSK_Status_vMax_FahrerInfo 0;
BA_ "GenSigSendType" SG_ 706 TSK_Ueberstimmt_vMax_FahrerInfo 3;
BA_ "GenSigSwitchedByIgnition" SG_ 706 TSK_Ueberstimmt_vMax_FahrerInfo 0;
BA_ "GenSigSendType" SG_ 706 TSK_vMax_FahrerInfo 0;
BA_ "GenSigSwitchedByIgnition" SG_ 706 TSK_vMax_FahrerInfo 0;
BA_ "GenSigSendType" SG_ 267 MO_Entkopplung_Sollschlupf 0;
BA_ "GenSigStartValue" SG_ 267 MO_Entkopplung_Sollschlupf 126;
BA_ "GenSigSwitchedByIgnition" SG_ 267 MO_Entkopplung_Sollschlupf 0;
BA_ "Fehlerwert" SG_ 267 MO_Fahrpedalgradient 255;
BA_ "GenSigSendType" SG_ 267 MO_Fahrpedalgradient 0;
BA_ "GenSigSwitchedByIgnition" SG_ 267 MO_Fahrpedalgradient 0;
BA_ "Fehlerwert" SG_ 267 MO_Fahrpedalrohwert_01 255;
BA_ "GenSigSendType" SG_ 267 MO_Fahrpedalrohwert_01 0;
BA_ "GenSigSwitchedByIgnition" SG_ 267 MO_Fahrpedalrohwert_01 0;
BA_ "GenSigSendType" SG_ 267 MO_Moment_im_Leerlauf 0;
BA_ "GenSigSwitchedByIgnition" SG_ 267 MO_Moment_im_Leerlauf 0;
BA_ "GenSigSendType" SG_ 267 MO_QBit_Fahrpedalwerte_01 0;
BA_ "GenSigStartValue" SG_ 267 MO_QBit_Fahrpedalwerte_01 1;
BA_ "GenSigSwitchedByIgnition" SG_ 267 MO_QBit_Fahrpedalwerte_01 0;
BA_ "Fehlerwert" SG_ 267 MO_rel_Saugrohrdruck 63;
BA_ "GenSigSendType" SG_ 267 MO_rel_Saugrohrdruck 0;
BA_ "GenSigSwitchedByIgnition" SG_ 267 MO_rel_Saugrohrdruck 0;
BA_ "GenSigSendType" SG_ 267 MO_rel_Saugrohrdruck_gem_err 0;
BA_ "GenSigSwitchedByIgnition" SG_ 267 MO_rel_Saugrohrdruck_gem_err 0;
BA_ "GenSigSendType" SG_ 267 MO_Schubabschaltung 0;
BA_ "GenSigSwitchedByIgnition" SG_ 267 MO_Schubabschaltung 0;
BA_ "GenSigSendType" SG_ 267 MO_Sig_Fahrpedalgradient 0;
BA_ "GenSigSwitchedByIgnition" SG_ 267 MO_Sig_Fahrpedalgradient 0;
BA_ "GenSigSendType" SG_ 267 MO_Solldrehz_Leerlauf 0;
BA_ "GenSigSwitchedByIgnition" SG_ 267 MO_Solldrehz_Leerlauf 0;
BA_ "GenSigSendType" SG_ 267 MO_StartStopp_StoppVorbereitung 0;
BA_ "GenSigSwitchedByIgnition" SG_ 267 MO_StartStopp_StoppVorbereitung 0;
BA_ "GenSigSendType" SG_ 267 MO_Status_MaxDrzEingriff 0;
BA_ "GenSigSwitchedByIgnition" SG_ 267 MO_Status_MaxDrzEingriff 0;
BA_ "GenSigSendType" SG_ 267 MO_Status_MaxDrzEingriff_sek 0;
BA_ "GenSigSwitchedByIgnition" SG_ 267 MO_Status_MaxDrzEingriff_sek 0;
BA_ "GenSigSendType" SG_ 267 MO_Status_MinDrzEingriff 0;
BA_ "GenSigSwitchedByIgnition" SG_ 267 MO_Status_MinDrzEingriff 0;
BA_ "GenSigSendType" SG_ 267 MO_Status_MinDrzEingriff_sek 0;
BA_ "GenSigSwitchedByIgnition" SG_ 267 MO_Status_MinDrzEingriff_sek 0;
BA_ "GenSigSendType" SG_ 267 MO_temporaere_Fahrerabwesenheit 0;
BA_ "GenSigSwitchedByIgnition" SG_ 267 MO_temporaere_Fahrerabwesenheit 0;
BA_ "GenSigFuncType" SG_ 267 Motor_51_BZ 1;
BA_ "GenSigSendType" SG_ 267 Motor_51_BZ 0;
BA_ "GenSigSwitchedByIgnition" SG_ 267 Motor_51_BZ 0;
BA_ "GenSigFuncType" SG_ 267 Motor_51_CRC 2;
BA_ "GenSigSendType" SG_ 267 Motor_51_CRC 0;
BA_ "GenSigSwitchedByIgnition" SG_ 267 Motor_51_CRC 0;
BA_ "GenSigFuncType" SG_ 267 SOK_Motor_51_Signatur 15;
BA_ "GenSigSendType" SG_ 267 SOK_Motor_51_Signatur 0;
BA_ "GenSigSendType" SG_ 267 TSK_a_Soll_gradientenbegrenzt 0;
BA_ "GenSigStartValue" SG_ 267 TSK_a_Soll_gradientenbegrenzt 127;
BA_ "GenSigSwitchedByIgnition" SG_ 267 TSK_a_Soll_gradientenbegrenzt 0;
BA_ "GenSigSendType" SG_ 267 TSK_ax_Getriebe_02 0;
BA_ "GenSigStartValue" SG_ 267 TSK_ax_Getriebe_02 511;
BA_ "GenSigSwitchedByIgnition" SG_ 267 TSK_ax_Getriebe_02 0;
BA_ "GenSigSendType" SG_ 267 TSK_Freig_Verzoeg_Anf 0;
BA_ "GenSigSwitchedByIgnition" SG_ 267 TSK_Freig_Verzoeg_Anf 0;
BA_ "Fehlerwert" SG_ 267 TSK_Hauptschalter_GRA_ACC 3;
BA_ "GenSigSendType" SG_ 267 TSK_Hauptschalter_GRA_ACC 0;
BA_ "GenSigSwitchedByIgnition" SG_ 267 TSK_Hauptschalter_GRA_ACC 0;
BA_ "GenSigSendType" SG_ 267 TSK_Kategorie_Verzoegerungsfkt 0;
BA_ "GenSigSwitchedByIgnition" SG_ 267 TSK_Kategorie_Verzoegerungsfkt 0;
BA_ "GenSigSendType" SG_ 267 TSK_Limiter_ausgewaehlt 0;
BA_ "GenSigSwitchedByIgnition" SG_ 267 TSK_Limiter_ausgewaehlt 0;
BA_ "GenSigSendType" SG_ 267 TSK_Notstopp_Anf 0;
BA_ "GenSigSwitchedByIgnition" SG_ 267 TSK_Notstopp_Anf 0;
BA_ "GenSigSendType" SG_ 267 TSK_Radbremsmom 0;
BA_ "GenSigSwitchedByIgnition" SG_ 267 TSK_Radbremsmom 0;
BA_ "Fehlerwert" SG_ 267 TSK_Radsollmoment 65535;
BA_ "GenSigSendType" SG_ 267 TSK_Radsollmoment 0;
BA_ "GenSigStartValue" SG_ 267 TSK_Radsollmoment 65534;
BA_ "GenSigSwitchedByIgnition" SG_ 267 TSK_Radsollmoment 0;
BA_ "GenSigSendType" SG_ 267 TSK_SRBM_Anf_ASIL 0;
BA_ "GenSigSwitchedByIgnition" SG_ 267 TSK_SRBM_Anf_ASIL 0;
BA_ "Fehlerwert" SG_ 267 TSK_SRBM_max_Gradient 127;
BA_ "GenSigSendType" SG_ 267 TSK_SRBM_max_Gradient 0;
BA_ "GenSigStartValue" SG_ 267 TSK_SRBM_max_Gradient 126;
BA_ "GenSigSwitchedByIgnition" SG_ 267 TSK_SRBM_max_Gradient 0;
BA_ "GenSigSendType" SG_ 267 TSK_Standby_Anf_ESP 0;
BA_ "GenSigSwitchedByIgnition" SG_ 267 TSK_Standby_Anf_ESP 0;
BA_ "GenSigSendType" SG_ 267 TSK_Status 0;
BA_ "GenSigStartValue" SG_ 267 TSK_Status 1;
BA_ "GenSigSwitchedByIgnition" SG_ 267 TSK_Status 0;
BA_ "GenSigSendType" SG_ 267 TSK_v_Begrenzung_aktiv 0;
BA_ "GenSigSwitchedByIgnition" SG_ 267 TSK_v_Begrenzung_aktiv 0;
BA_ "GenSigSendType" SG_ 267 TSK_zul_Regelabw 0;
BA_ "GenSigSwitchedByIgnition" SG_ 267 TSK_zul_Regelabw 0;
BA_ "GenSigSendType" SG_ 267 TSK_Zwangszusch_ESP 0;
BA_ "GenSigSwitchedByIgnition" SG_ 267 TSK_Zwangszusch_ESP 0;
BA_ "Fehlerwert" SG_ 330 Ladezustand_02 255;
BA_ "GenSigSendType" SG_ 330 Ladezustand_02 0;
BA_ "GenSigStartValue" SG_ 330 Ladezustand_02 254;
BA_ "GenSigSwitchedByIgnition" SG_ 330 Ladezustand_02 0;
BA_ "GenSigSendType" SG_ 330 Ladezustand_gering 0;
BA_ "GenSigSwitchedByIgnition" SG_ 330 Ladezustand_gering 0;
BA_ "Fehlerwert" SG_ 330 MO_Anzeige_Drehmoment 2047;
BA_ "GenSigSendType" SG_ 330 MO_Anzeige_Drehmoment 0;
BA_ "GenSigSwitchedByIgnition" SG_ 330 MO_Anzeige_Drehmoment 0;
BA_ "Fehlerwert" SG_ 330 MO_Anzeige_Leistung 2047;
BA_ "GenSigSendType" SG_ 330 MO_Anzeige_Leistung 0;
BA_ "GenSigSwitchedByIgnition" SG_ 330 MO_Anzeige_Leistung 0;
BA_ "GenSigSendType" SG_ 330 MO_Anzeige_Verbr_Einheit 0;
BA_ "GenSigSwitchedByIgnition" SG_ 330 MO_Anzeige_Verbr_Einheit 0;
BA_ "GenSigSendType" SG_ 330 MO_Anzeigedrehz 0;
BA_ "GenSigSwitchedByIgnition" SG_ 330 MO_Anzeigedrehz 0;
BA_ "GenSigSendType" SG_ 330 MO_Effizienzmodus 0;
BA_ "GenSigSwitchedByIgnition" SG_ 330 MO_Effizienzmodus 0;
BA_ "Fehlerwert" SG_ 330 MO_ePerformance 255;
BA_ "GenSigSendType" SG_ 330 MO_ePerformance 0;
BA_ "GenSigSwitchedByIgnition" SG_ 330 MO_ePerformance 0;
BA_ "GenSigSendType" SG_ 330 MO_ePowermeter 0;
BA_ "GenSigSwitchedByIgnition" SG_ 330 MO_ePowermeter 0;
BA_ "Fehlerwert" SG_ 330 MO_Fehler_Oeldrucksensor 1;
BA_ "GenSigSendType" SG_ 330 MO_Fehler_Oeldrucksensor 0;
BA_ "GenSigSwitchedByIgnition" SG_ 330 MO_Fehler_Oeldrucksensor 0;
BA_ "Fehlerwert" SG_ 330 MO_Hochschaltdrehz 4095;
BA_ "GenSigSendType" SG_ 330 MO_Hochschaltdrehz 0;
BA_ "GenSigSwitchedByIgnition" SG_ 330 MO_Hochschaltdrehz 0;
BA_ "GenSigSendType" SG_ 330 MO_Istgang 0;
BA_ "GenSigSwitchedByIgnition" SG_ 330 MO_Istgang 0;
BA_ "GenSigSendType" SG_ 330 MO_KVS 0;
BA_ "GenSigSwitchedByIgnition" SG_ 330 MO_KVS 0;
BA_ "GenSigSendType" SG_ 330 MO_KVS_Ueberlauf 0;
BA_ "GenSigSwitchedByIgnition" SG_ 330 MO_KVS_Ueberlauf 0;
BA_ "Fehlerwert" SG_ 330 MO_Ladedruck 511;
BA_ "GenSigSendType" SG_ 330 MO_Ladedruck 0;
BA_ "GenSigSwitchedByIgnition" SG_ 330 MO_Ladedruck 0;
BA_ "Fehlerwert" SG_ 330 MO_Oeldruck 255;
BA_ "GenSigSendType" SG_ 330 MO_Oeldruck 0;
BA_ "GenSigStartValue" SG_ 330 MO_Oeldruck 254;
BA_ "GenSigSwitchedByIgnition" SG_ 330 MO_Oeldruck 0;
BA_ "GenSigSwitchedByIgnition" SG_ 330 MO_OnePedalDriving_Warnung 0;
BA_ "GenSigSendType" SG_ 330 MO_Powermeter 0;
BA_ "GenSigStartValue" SG_ 330 MO_Powermeter 4093;
BA_ "GenSigSwitchedByIgnition" SG_ 330 MO_Powermeter 0;
BA_ "GenSigSendType" SG_ 330 MO_Powermeter_Elm_02 0;
BA_ "GenSigStartValue" SG_ 330 MO_Powermeter_Elm_02 4094;
BA_ "GenSigSwitchedByIgnition" SG_ 330 MO_Powermeter_Elm_02 0;
BA_ "Fehlerwert" SG_ 330 MO_rel_Ladedruck 255;
BA_ "GenSigSendType" SG_ 330 MO_rel_Ladedruck 0;
BA_ "GenSigSwitchedByIgnition" SG_ 330 MO_rel_Ladedruck 0;
BA_ "Fehlerwert" SG_ 330 MO_Schaltblitz_Anz 127;
BA_ "GenSigSendType" SG_ 330 MO_Schaltblitz_Anz 0;
BA_ "GenSigStartValue" SG_ 330 MO_Schaltblitz_Anz 126;
BA_ "GenSigSwitchedByIgnition" SG_ 330 MO_Schaltblitz_Anz 0;
BA_ "GenSigSendType" SG_ 330 MO_Schaltempf_verfbar 0;
BA_ "GenSigSwitchedByIgnition" SG_ 330 MO_Schaltempf_verfbar 0;
BA_ "GenSigSendType" SG_ 330 MO_Sollgang 0;
BA_ "GenSigSwitchedByIgnition" SG_ 330 MO_Sollgang 0;
BA_ "GenSigSendType" SG_ 330 MO_Zust_Antrieb 0;
BA_ "GenSigSwitchedByIgnition" SG_ 330 MO_Zust_Antrieb 0;
BA_ "GenSigSendType" SG_ 330 MO_Zust_Betriebsstrategie 0;
BA_ "GenSigSwitchedByIgnition" SG_ 330 MO_Zust_Betriebsstrategie 0;
BA_ "GenSigFuncType" SG_ 330 Motor_52_BZ 1;
BA_ "GenSigSwitchedByIgnition" SG_ 330 Motor_52_BZ 0;
BA_ "GenSigFuncType" SG_ 330 Motor_52_CRC 2;
BA_ "GenSigSwitchedByIgnition" SG_ 330 Motor_52_CRC 0;
BA_REL_ "GenSigTimeoutTime" BU_SG_REL_ Fahrerdisplay_Kombi SG_ 330 MO_OnePedalDriving_Warnung 500;
BA_REL_ "GenSigTimeoutTime" BU_SG_REL_ Fahrerdisplay_Kombi SG_ 967 MO_OBD2_Lampe 1000;
BA_REL_ "GenSigTimeoutTime" BU_SG_REL_ Fahrerdisplay_Kombi SG_ 1648 MO_EPCL 5000;
BA_REL_ "GenSigTimeoutTime" BU_SG_REL_ Fahrerdisplay_Kombi SG_ 1648 MO_Fahrzeugtyp 5000;
BA_REL_ "GenSigTimeoutTime" BU_SG_REL_ ICAS1_X_Gateway SG_ 1153 INF_Nachlaufzeit 5000;
BA_REL_ "GenSigTimeoutTime" BU_SG_REL_ ICAS1_X_Gateway SG_ 1153 ZR_Lichter_Tag 5000;
BA_REL_ "GenSigTimeoutTime" BU_SG_REL_ ICAS3_Gateway SG_ 560 MFL_Beruehrungserkennung 1000;
BA_REL_ "GenSigTimeoutTime" BU_SG_REL_ ICAS3_Gateway SG_ 560 MFL_Touch_Event 1000;
BA_REL_ "GenSigTimeoutTime" BU_SG_REL_ ICAS3_Gateway SG_ 958 MO_HYB_Fahrbereitschaft 1000;
BA_REL_ "GenSigTimeoutTime" BU_SG_REL_ ICAS3_Gateway SG_ 1164 MF_Radiomute 2000;
BA_REL_ "GenSigTimeoutTime" BU_SG_REL_ Kombi SG_ 267 TSK_Hauptschalter_GRA_ACC 500;
BA_REL_ "GenSigTimeoutTime" BU_SG_REL_ Kombi SG_ 330 Ladezustand_02 500;
BA_REL_ "GenSigTimeoutTime" BU_SG_REL_ Kombi SG_ 330 Ladezustand_gering 500;
BA_REL_ "GenSigTimeoutTime" BU_SG_REL_ Kombi SG_ 330 MO_OnePedalDriving_Warnung 500;
BA_REL_ "GenSigTimeoutTime" BU_SG_REL_ Kombi SG_ 330 MO_Powermeter 500;
BA_REL_ "GenSigTimeoutTime" BU_SG_REL_ Kombi SG_ 330 MO_ePerformance 500;
BA_REL_ "GenSigTimeoutTime" BU_SG_REL_ Kombi SG_ 330 Motor_52_BZ 500;
BA_REL_ "GenSigTimeoutTime" BU_SG_REL_ Kombi SG_ 330 Motor_52_CRC 500;
BA_REL_ "GenSigTimeoutTime" BU_SG_REL_ Kombi SG_ 706 FDR_Warnung_ALR 5000;
BA_REL_ "GenSigTimeoutTime" BU_SG_REL_ Kombi SG_ 706 MO_EM_Ueberhitzungswarnung 5000;
BA_REL_ "GenSigTimeoutTime" BU_SG_REL_ Kombi SG_ 706 MO_ElAntrieb_Abschleppwarnung 5000;
BA_REL_ "GenSigTimeoutTime" BU_SG_REL_ Kombi SG_ 706 MO_Rekuperationsstufe 5000;
BA_REL_ "GenSigTimeoutTime" BU_SG_REL_ Kombi SG_ 817 MFL_Paddle_Verbau 5000;
BA_REL_ "GenSigTimeoutTime" BU_SG_REL_ Kombi SG_ 958 MO_HYB_Fahrbereitschaft 1000;
BA_REL_ "GenSigTimeoutTime" BU_SG_REL_ Kombi SG_ 967 MO_OBD2_Lampe 1000;
BA_REL_ "GenSigTimeoutTime" BU_SG_REL_ Kombi SG_ 967 MO_RedFahrleistung_Lampe 1000;
BA_REL_ "GenSigTimeoutTime" BU_SG_REL_ Kombi SG_ 1153 Nav_FoD_Status 5000;
BA_REL_ "GenSigTimeoutTime" BU_SG_REL_ Kombi SG_ 1153 ZR_LoGeWa_Event_Kombiwarnung 5000;
BA_REL_ "GenSigTimeoutTime" BU_SG_REL_ Kombi SG_ 1171 MF_Summer 2000;
BA_REL_ "GenSigTimeoutTime" BU_SG_REL_ Kombi SG_ 1178 FS_MMB_storage_beep 1000;
BA_REL_ "GenSigTimeoutTime" BU_SG_REL_ Kombi SG_ 1639 BFS_MMB_storage_beep 1000;
BA_REL_ "GenSigTimeoutTime" BU_SG_REL_ Kombi SG_ 1648 MO_EPCL 5000;
BA_REL_ "GenSigTimeoutTime" BU_SG_REL_ Kombi SG_ 1648 MO_Fahrzeugtyp 5000;
BA_REL_ "GenSigTimeoutTime" BU_SG_REL_ SmartLight_01 SG_ 1171 MF_Innenraumbel_Unterdrueck 2000;
BA_REL_ "GenSigTimeoutTime" BU_SG_REL_ ZR_MIB_TOP_ab_Gen3 SG_ 267 MO_Fahrpedalrohwert_01 500;
BA_REL_ "GenSigTimeoutTime" BU_SG_REL_ ZR_MIB_TOP_ab_Gen3 SG_ 330 Ladezustand_02 500;
BA_REL_ "GenSigTimeoutTime" BU_SG_REL_ ZR_MIB_TOP_ab_Gen3 SG_ 958 MO_Fahrer_bremst 1000;
BA_REL_ "GenSigTimeoutTime" BU_SG_REL_ ZR_MIB_TOP_ab_Gen3 SG_ 958 MO_Kickdown 1000;
BA_REL_ "GenSigTimeoutTime" BU_SG_REL_ ZR_MIB_TOP_ab_Gen3 SG_ 958 MO_QBit_Fahrer_bremst 1000;
VAL_ 1153 DSSS_Warning 0 "No_Warning" 1 "Red_traffic_light_guidance" 2 "Stop_sign_warning" 3 "Rear_end_collision_avoidance_warning" 4 "Intersection_collision_avoidance_warning_right" 5 "Intersection_collision_avoidance_warning_left" 6 "turn_right_collision_avoidance" 7 "turn_left_collision_avoidance" 8 "pedestrian_crossing_right" 9 "pedestrian_crossing_left" 10 "bicycle_collision_right" 11 "bicycle_collision_left" ;
VAL_ 1153 HMI_WLC1_Systemzustand_intern 0 "Wireless_Charger_off" 1 "Wireless_Charger_on" 2 "Wireless_Charger_init" ;
VAL_ 1153 HMI_WLC2_Systemzustand_intern 0 "Wireless_Charger_off" 1 "Wireless_Charger_on" 2 "Wireless_Charger_init" ;
VAL_ 1153 INF_Nachlaufzeit 510 "INIT" 511 "Fehler" ;
VAL_ 1153 MIB_ASW_Diagnose 0 "ASW_Warnton_nicht_verfuegbar" 1 "ASW_Warnton_verfuegbar" ;
VAL_ 1153 MIB_Tongenerator_PH_verfuegbar 0 "Tongenerator_nicht_verfuegbar" 1 "Tongenerator_vorne_verfuegbar" 2 "Tongenerator_hinten_verfuegbar" 3 "Tongenerator_gesamt_verfuegbar" 4 "Tongenerator_im_AMP" ;
VAL_ 1153 MMI_Gurt_Mic_ref 0 "Downlink_inaktiv" 1 "Downlink_aktiv" ;
VAL_ 1153 MMI_SDS_aktiv 0 "inaktiv" 1 "aktiv" ;
VAL_ 1153 MMI_Telefon_aktiv 0 "Telefongespraech_nicht_aktiv" 1 "Telefongespraech_aktiv" ;
VAL_ 1153 MU_SecondDisplay 0 "Init" 1 "gueltige_Karte" 2 "ungueltiges_Signal" 3 "Nicht_Verbaut" ;
VAL_ 1153 Nav_FoD_Status 0 "Init" 1 "Nav_permanently_available" 2 "FoD_Nav_not_activated" 3 "FoD_Nav_activated" 4 "R4N_Nav_not_activated" ;
VAL_ 1153 ZR_AppConnect_Zustand 0 "AppConnect_nicht_in_Anzeige" 1 "AppConnect_in_Anzeige" ;
VAL_ 1153 ZR_Kindersicherung_RSE 0 "inaktiv" 1 "aktiv" ;
VAL_ 1153 ZR_Lichter_Tag 0 "Nacht" 1 "Tag" ;
VAL_ 1153 ZR_LoGeWa_Event_Kombiwarnung 0 "Init" 1 "Unfall" 2 "Traktionsverlust" 3 "Panne" 4 "Sichtbehinderung" 5 "Aquaplaning" 6 "EEBL" 7 "SEF_stat" 8 "SEF_dyn_allgemein" 9 "SEF_dyn_vorne" 10 "SEF_dyn_hinten" 11 "SEF_dyn_links" 12 "SEF_dyn_rechts" 13 "Stauende" ;
VAL_ 1153 ZR_Parken_Sondermodus 0 "Init" 1 "Sondermodus_aktiv" 2 "Sondermodus_nicht_verfuegbar" 3 "WLAN_aus" 4 "WLAN_auscodiert" 15 "keine_WLAN_HW" ;
VAL_ 1153 ZR_RSE_aktivieren 0 "inaktiv" 1 "aktiv" ;
VAL_ 1639 BFS_Fond_Bed_Ack 0 "nicht aktiviert" 1 "aktiviert" ;
VAL_ 1639 BFS_FSV_ausgeklappt 0 "FSV_nicht_ausgeklappt" 1 "FSV_ausgeklappt" ;
VAL_ 1639 BFS_GHV_aktiv 0 "nicht_aktiv" 1 "Gurthoehe Verstellung aktiv" ;
VAL_ 1639 BFS_Gurtbringer_Sperre 0 "Gurtzubringer_freigegeben" 1 "Gurtzubringer_gesperrt" ;
VAL_ 1639 BFS_Klapptisch_offen 0 "inaktiv" 1 "aktiv" ;
VAL_ 1639 BFS_KSS_Fahrt_aktiv 0 "nicht_aktiv" 1 "Komfortseitensichtfahrt aktiv" ;
VAL_ 1639 BFS_KSV_aktiv 0 "nicht_aktiv" 1 "Kopfstuetzenverstellung aktiv" ;
VAL_ 1639 BFS_Lehne_nicht_verriegelt 0 "keine Anzeige" 1 "Lehne_nicht_verriegelt" ;
VAL_ 1639 BFS_LHV_aktiv 0 "inaktiv" 1 "aktiv" ;
VAL_ 1639 BFS_LKV_aktiv 0 "nicht_aktiv" 1 "aktiv" ;
VAL_ 1639 BFS_LNV_aktiv 0 "inaktiv" 1 "aktiv" ;
VAL_ 1639 BFS_LWV_aktiv 0 "nicht_aktiv" 1 "aktiv" ;
VAL_ 1639 BFS_MMB_glob_stop 0 "kein globaler Abbruch" 1 "globaler Abbruch" ;
VAL_ 1639 BFS_MMB_lokal_Stop 0 "kein_Abbruch" 1 "lokaler_Abbruch" ;
VAL_ 1639 BFS_MMB_storage 0 "keine Zuweisung" 1 "P1/FP1 Pos Zuweisung" 2 "P2/FP2 Pos Zuweisung" 3 "P3/FP3 Pos Zuweisung" 4 "P4/FP4 Pos Zuweisung an den im System aktiven Funkschlï?½ssel/FPI ID ï?½ber MMI" 5 "FS1" 6 "FS2" 7 "FS3" 8 "FS4" ;
VAL_ 1639 BFS_MMB_storage_beep 0 "beep_aus" 1 "beep ein" ;
VAL_ 1639 BFS_MMB_store 0 "nicht speichern" 1 "speichern" ;
VAL_ 1639 BFS_MMB_store_LED_on 0 "LED_aus" 1 "LED_ein" ;
VAL_ 1639 BFS_MMB_tast 0 "kein_Tastbetrieb" 1 "Tastbetrieb" ;
VAL_ 1639 BFS_MMB_tipp 0 "kein_Tippbetrieb" 1 "Tippbetrieb" ;
VAL_ 1639 BFS_Ruhestellung_Status 0 "inakiv" 1 "Ruhestellung_aktiv" ;
VAL_ 1639 BFS_Seat_Locked 0 "nicht_gesperrt" 1 "gesperrt" ;
VAL_ 1639 BFS_SHV_aktiv 0 "nicht_aktiv" 1 "Sitzhoehenverstellung aktiv" ;
VAL_ 1639 BFS_Sitzfahrt_aktiv 0 "Init" 1 "Sitz in Bewegung" ;
VAL_ 1639 BFS_Sitzsym_Fahrt_aktiv 0 "inaktiv" 1 "aktiv" ;
VAL_ 1639 BFS_SLV_aktiv 0 "nicht_aktiv" 1 "Sitzlaengsverstellung aktiv" ;
VAL_ 1639 BFS_SNV_aktiv 0 "nicht_aktiv" 1 "Sitzneigungsverstellung aktiv" ;
VAL_ 1639 BFS_STV_aktiv 0 "inaktiv" 1 "Sitztiefeverstellung aktiv" ;
VAL_ 1178 FS_BFS_KSS_Anfahrt 0 "keine Anfahrt KSS BFS" 1 "Anfahrt KSS BFS" ;
VAL_ 1178 FS_BFS_Sitzsym_Anfahrt 0 "keine Sitzsymetrie Anfahrt BFS" 1 "Sitzsymetrie Anfahrt BFS" ;
VAL_ 1178 FS_EE_BFS_enable 0 "keine_EE_Freigabe" 1 "EE_Freigabe" ;
VAL_ 1178 FS_EE_Fond_BFS_enable 0 "EE Fond rechts deaktiv" 1 "EE Fond rechts aktiv (default) vom MMI" ;
VAL_ 1178 FS_EE_Fond_FS_enable 0 "EE Fond links deaktiv" 1 "EE Fond links aktiv (default) vom MMI" ;
VAL_ 1178 FS_Fond_Bed_enable 0 "disable" 1 "enable" ;
VAL_ 1178 FS_GHV_aktiv 0 "nicht_aktiv" 1 "Gurthoehenverstellung aktiv" ;
VAL_ 1178 FS_Gurtbringer_Sperre 0 "Gurtzubringer_freigegeben" 1 "Gurtzubringer_gesperrt" ;
VAL_ 1178 FS_KSV_aktiv 0 "nicht_aktiv" 1 "Kopfstuetzenverstellung aktiv" ;
VAL_ 1178 FS_Lehne_nicht_verriegelt 0 "keine Anzeige" 1 "Lehne_nicht_verriegelt" ;
VAL_ 1178 FS_LHV_aktiv 0 "nicht_aktiv" 1 "Lordose Hï?½he Verstellung aktiv" ;
VAL_ 1178 FS_LKV_aktiv 0 "nicht_aktiv" 1 "Lehnenkopfverstellung aktiv" ;
VAL_ 1178 FS_LNV_aktiv 0 "nicht_aktiv" 1 "Lehnenneigungverstellung aktiv" ;
VAL_ 1178 FS_LWV_aktiv 0 "nicht_aktiv" 1 "Lordose W Verstellung aktiv" ;
VAL_ 1178 FS_MMB_glob_stop 0 "kein_globaler_Abbrucht" 1 "globaler_Abbruch" ;
VAL_ 1178 FS_MMB_lokal_Stop 0 "kein_Abbruch" 1 "lokaler_Abbruch" ;
VAL_ 1178 FS_MMB_storage 0 "keine_Zuweisung" 1 "P1_FP1_Pos_Zuweisung" 2 "P2_FP2_Pos_Zuweisung" 3 "P3_FP3_Pos_Zuweisung" 4 "P4_FP4_Pos_Zuweisung" 5 "FS1_bzw_Benutzerkonto_1" 6 "FS2_bzw_Benutzerkonto_2" 7 "FS3_bzw_Benutzerkonto_3" 8 "FS4_bzw_Benutzerkonto_4" 9 "FS5_bzw_Benutzerkonto_5" 10 "FS6_bzw_Benutzerkonto_6" 11 "FS7_bzw_Benutzerkonto_7" ;
VAL_ 1178 FS_MMB_storage_beep 0 "beep aus" 1 "beep ein" ;
VAL_ 1178 FS_MMB_store 0 "nicht_speichern__kein_keyless_ve" 1 "abspeichern__keyless_verbaut" ;
VAL_ 1178 FS_MMB_store_LED_on 0 "LED_aus" 1 "LED_ein" ;
VAL_ 1178 FS_MMB_tast 0 "kein_Tastbetrieb" 1 "Tastbetrieb__Fingerprintautomati" ;
VAL_ 1178 FS_MMB_tipp 0 "kein_Tippbetrieb" 1 "Tippbetrieb__automatisches_Funks" ;
VAL_ 1178 FS_SHV_aktiv 0 "nicht_aktiv" 1 "Sitzhoehenverstellung aktiv" ;
VAL_ 1178 FS_Sitzfahrt_aktiv 0 "Sitz_nicht_in_Bewegung" 1 "Sitz_in_Bewegung" ;
VAL_ 1178 FS_SLV_aktiv 0 "nicht_aktiv" 1 "Sitzlaengsverstellung aktiv" ;
VAL_ 1178 FS_SNV_aktiv 0 "nicht_aktiv" 1 "Sitzneigungsverstellung_aktiv" ;
VAL_ 1178 FS_Spezialposition_anfahren 0 "Fkt_inaktiv" 1 "Fkt_aktiv" ;
VAL_ 1178 FS_STV_aktiv 0 "nicht_aktiv" 1 "Sitztiefeverstellung aktiv" ;
VAL_ 1171 MF_Abzugssperre 0 "inaktiv" 1 "aktiv" ;
VAL_ 1171 MF_Alarm_Blinker 0 "inaktiv" 1 "aktiv" ;
VAL_ 1171 MF_Alarm_Blinkertakt 0 "inaktiv" 1 "aktiv" ;
VAL_ 1171 MF_Anlassersperre 0 "inaktiv" 1 "aktiv" ;
VAL_ 1171 MF_Blk_li 0 "inaktiv" 1 "aktiv" ;
VAL_ 1171 MF_Blk_re 0 "inaktiv" 1 "aktiv" ;
VAL_ 1171 MF_BT_entriegeln 0 "nicht_entriegeln" 1 "entriegeln" ;
VAL_ 1171 MF_BT_verriegeln 0 "nicht_verriegeln" 1 "verriegeln" ;
VAL_ 1171 MF_Fahrlicht 0 "inaktiv" 1 "aktiv" ;
VAL_ 1171 MF_Fernbed_ein 0 "inaktiv" 1 "aktiv" ;
VAL_ 1171 MF_Fernlicht 0 "inaktiv" 1 "aktiv" ;
VAL_ 1171 MF_FH_BT_hoch 0 "inaktiv" 1 "aktiv" ;
VAL_ 1171 MF_FH_BT_tief 0 "inaktiv" 1 "aktiv" ;
VAL_ 1171 MF_FH_FT_hoch 0 "inaktiv" 1 "aktiv" ;
VAL_ 1171 MF_FH_FT_tief 0 "inaktiv" 1 "aktiv" ;
VAL_ 1171 MF_Frontintervall 0 "inaktiv" 1 "aktiv" ;
VAL_ 1171 MF_Frontwaschen 0 "inaktiv" 1 "aktiv" ;
VAL_ 1171 MF_FT_entriegeln 0 "nicht_entriegeln" 1 "entriegeln" ;
VAL_ 1171 MF_FT_verriegeln 0 "nicht_verriegeln" 1 "verriegeln" ;
VAL_ 1171 MF_Fussraumbel 0 "inaktiv" 1 "aktiv" ;
VAL_ 1171 MF_HBFS_entriegeln 0 "nicht_entriegeln" 1 "entriegeln" ;
VAL_ 1171 MF_HBFS_verriegeln 0 "nicht_verriegeln" 1 "verriegeln" ;
VAL_ 1171 MF_Heckintervall 0 "inaktiv" 1 "aktiv" ;
VAL_ 1171 MF_Heckwaschen 0 "inaktiv" 1 "aktiv" ;
VAL_ 1171 MF_HFS_entriegeln 0 "nicht_entriegeln" 1 "entriegeln" ;
VAL_ 1171 MF_HFS_verriegeln 0 "nicht_verriegeln" 1 "verriegeln" ;
VAL_ 1171 MF_Innenraumbel 0 "inaktiv" 1 "aktiv" ;
VAL_ 1171 MF_Innenraumbel_Unterdrueck 0 "inaktiv" 1 "aktiv" ;
VAL_ 1171 MF_interm_Fahrlicht 0 "inaktiv" 1 "aktiv" ;
VAL_ 1171 MF_interm_Fernlicht 0 "inaktiv" 1 "aktiv" ;
VAL_ 1171 MF_interm_Takt 0 "inaktiv" 1 "aktiv" ;
VAL_ 1171 MF_Laderelais 0 "Relais_offen" 1 "Relais_geschlossen" ;
VAL_ 1171 MF_Lichthupe 0 "inaktiv" 1 "aktiv" ;
VAL_ 1171 MF_Motorweiterlauf 0 "inaktiv" 1 "aktiv" ;
VAL_ 1171 MF_nachtr_Stopp_Anf 0 "nicht_angefordert" 1 "angefordert" ;
VAL_ 1171 MF_Notstart 0 "kein_Notstart" 1 "Notstart" ;
VAL_ 1171 MF_Schluessel_scan 0 "inaktiv" 1 "aktiv" ;
VAL_ 1171 MF_Signalhorn 0 "inaktiv" 1 "aktiv" ;
VAL_ 1171 MF_Standlicht 0 "inaktiv" 1 "aktiv" ;
VAL_ 1171 MF_StartStopp_Info 0 "Motorlauf_nicht_notwendig_(Stoppfreigabe)" 1 "Motoranlauf_nicht_zwingend_notwendig_(Stoppverbot,keine_Startanforderung)" 2 "Motoranlauf_zwingend_notwendig_(Startanforderung)" 3 "Systemfehler" ;
VAL_ 1171 MF_Summer 0 "inaktiv" 1 "aktiv" ;
VAL_ 1171 MF_TFL_Abschaltung 0 "inaktiv" 1 "aktiv" ;
VAL_ 1171 MF_Tippwischen 0 "inaktiv" 1 "aktiv" ;
VAL_ 1171 MF_Tuerentriegelung_hinten 0 "inaktiv" 1 "aktiv" ;
VAL_ 1171 MF_Variante 0 "keine_Sonderfunktion" 1 "Sondersignalfahrzeug" 2 "Taxi" 3 "Fahrhilfe" 4 "Fahrschule_Extra" 5 "SSF" 6 "DBMC" 7 "Arbeitsmaschine" ;
VAL_ 1171 MF_Warnblinker 0 "inaktiv" 1 "aktiv" ;
VAL_ 1171 MF_Wischerstufe_1 0 "inaktiv" 1 "aktiv" ;
VAL_ 1171 MF_Wischerstufe_2 0 "inaktiv" 1 "aktiv" ;
VAL_ 1171 MF_ZV_Lock 0 "Locktaster_nicht_betaetigt" 1 "Locktaster_betaetigt" ;
VAL_ 1164 MF_2BatSOCzugering 0 "inaktiv" 1 "aktiv" ;
VAL_ 1164 MF_2BattAb 0 "inaktiv" 1 "aktiv" ;
VAL_ 1164 MF_2BattHlkAnf 0 "inaktiv" 1 "aktiv" ;
VAL_ 1164 MF_2BattLadWarn 0 "inaktiv" 1 "aktiv" ;
VAL_ 1164 MF_2BattLlaAnf 0 "inaktiv" 1 "aktiv" ;
VAL_ 1164 MF_2BattSpannungsAnf 0 "keine_Anforderung" 1 "Anforderung_Stufe1" 2 "Anforderung_Stufe2" 3 "Anforderung_Stufe3" ;
VAL_ 1164 MF_Batteriediagnose 0 "keine_Anzeige" 1 "Anzeige_Batterieservice" 2 "Anzeige_aberkannte_Batterie" 3 "Anzeige_schwache_Batterie" 4 "Anzeige_Batterie_OK" 5 "Anzeige_Batterie_Laden" 6 "Anzeige_Batterie_Pruefen" 7 "Fehler" ;
VAL_ 1164 MF_Blinker_L_Sta 0 "inaktiv" 1 "aktiv" ;
VAL_ 1164 MF_Blinker_R_Sta 0 "inaktiv" 1 "aktiv" ;
VAL_ 1164 MF_ExterneLadungWarn 0 "inaktiv" 1 "aktiv" ;
VAL_ 1164 MF_Fahrerhinweis 0 "keine_Anzeige" 1 "Warnung_Verrollsicherheit" 2 "Warnung_Fahrzeug_im_Freien" 3 "Warnung_Verlassen_Verriegeln" 4 "reserved" 5 "reserved" 6 "reserved" 7 "reserved" ;
VAL_ 1164 MF_Generatordiagnose 0 "keine_Warnung" 1 "Warnung_Stufe_1" 2 "Warnung_Stufe_2" 3 "Nicht_verbaut" ;
VAL_ 1164 MF_Heck_entriegeln 0 "nicht_entriegeln" 1 "entriegeln" ;
VAL_ 1164 MF_Heck_verriegeln 0 "nicht_verriegeln" 1 "verriegeln" ;
VAL_ 1164 MF_interm_Nebelscheinwerfer 0 "inaktiv" 1 "aktiv" ;
VAL_ 1164 MF_Lampenausfall 0 "iO" 1 "defekt" ;
VAL_ 1164 MF_LSH_Abschaltstufe 0 "Init" 1 "Stufe1" 2 "Stufe2" 3 "Stufe3" 4 "Transportmodus" 7 "Ruhestrommessmodus" ;
VAL_ 1164 MF_LSH_Einschaltverbot 0 "Init_volleVerfuegbarkeit" 1 "Standheizung_bzw_lueftung_nicht_aktivierbar" ;
VAL_ 1164 MF_LSH_Zielzeit 14 "Init" 15 "Fehler" ;
VAL_ 1164 MF_NotStartAktiv 0 "inaktiv" 1 "aktiv" ;
VAL_ 1164 MF_Radiomute 0 "Kein_Mute" 1 "Mute" ;
VAL_ 1164 MF_Relais_2_Batterie 0 "nicht_betaetigt" 1 "betaetigt" ;
VAL_ 1164 MF_Tuerverriegelung_hinten 0 "inaktiv" 1 "aktiv" ;
VAL_ 1164 MF_ZV_Unlock 0 "nicht_entriegeln" 1 "entriegeln" ;
VAL_ 1164 MFG_AppConnect_Anf 0 "AppConnect_keine_Anforderung" 1 "AppConnect_Anforderung" 2 "AppConnect_Darstellungsrueckgabe" ;
VAL_ 1164 MFG_Klappe_Status 0 "Init" 1 "Front" 2 "Heck" 3 "Front_u_Heck" 4 "misch_Front_u_Heck" ;
VAL_ 817 MFL_ECU_Err 0 "normal" 1 "Fehler" ;
VAL_ 817 MFL_Eventcode_1 0 "W_no_event____T_no_event" 1 "W_1_Tick_up__T_pressed_normal" 2 "W_2_Ticks_up__T_touched" 3 "W_3_Ticks_up__T_double_click_nor" 4 "W_4_Ticks_up__T_long_press_nor_1" 5 "W_5_Ticks_up__T_long_press_nor_2" 6 "W_6_Ticks_up__T_long_press_nor_3" 7 "W_7_Ticks_up" 9 "W_7_Ticks_dn__T_pressed_strong" 10 "W_6_Ticks_dn" 11 "W_5_Ticks_dn__T_double_click_str" 12 "W_4_Ticks_dn__T_long_press_str_1" 13 "W_3_Ticks_dn__T_long_press_str_2" 14 "W_2_Ticks_dn__T_long_press_str_3" 15 "W_1_Tick_dn" ;
VAL_ 817 MFL_Eventcode_2 0 "W_no_event____T_no_event" 1 "W_1_Tick_up__T_pressed_normal" 2 "W_2_Ticks_up__T_touched" 3 "W_3_Ticks_up__T_double_click_nor" 4 "W_4_Ticks_up__T_long_press_nor_1" 5 "W_5_Ticks_up__T_long_press_nor_2" 6 "W_6_Ticks_up__T_long_press_nor_3" 7 "W_7_Ticks_up" 9 "W_7_Ticks_dn__T_pressed_strong" 10 "W_6_Ticks_dn" 11 "W_5_Ticks_dn__T_double_click_str" 12 "W_4_Ticks_dn__T_long_press_str_1" 13 "W_3_Ticks_dn__T_long_press_str_2" 14 "W_2_Ticks_dn__T_long_press_str_3" 15 "W_1_Tick_dn" ;
VAL_ 817 MFL_Fehler_Codierung 0 "kein_Fehler" 1 "Fehler" ;
VAL_ 817 MFL_Lokalaktiv 0 "war_nicht_lokal_aktiv" 1 "war_lokal_aktiv" ;
VAL_ 817 MFL_LR_HZG_Err 0 "normal" 1 "Fehler" ;
VAL_ 817 MFL_LR_HZG_Status 0 "inaktiv" 1 "aktiv" ;
VAL_ 817 MFL_M_Taste 0 "nicht_betaetigt" 1 "betaetigt" ;
VAL_ 817 MFL_Marke 0 "VW" 1 "Audi" 2 "Seat" 3 "Skoda" 4 "VW_Nutzf" 5 "Bugatti" 6 "Lamborghini" 7 "Bentley" 8 "Rolls Royce" 9 "Quattro" 10 "kein_Hersteller_1" 11 "kein_Hersteller_2" 12 "kein_Hersteller_3" 13 "kein_Hersteller_4" 14 "Ford" 15 "Porsche" ;
VAL_ 817 MFL_Paddle_Verbau 0 "verbaut" 1 "nicht_verbaut" ;
VAL_ 817 MFL_Response_Err 0 "normal" 1 "Fehler" ;
VAL_ 817 MFL_SatModul_links_Err 0 "kein_Fehler" 1 "Fehler" ;
VAL_ 817 MFL_SatModul_rechts_Err 0 "kein_Fehler" 1 "Fehler" ;
VAL_ 817 MFL_Signalhorn 0 "nicht_betaetigt" 1 "betaetigt" ;
VAL_ 817 MFL_Signalhorn_Err 0 "normal" 1 "Fehler" ;
VAL_ 817 MFL_Taste_links_Err 0 "normal" 1 "Fehler" ;
VAL_ 817 MFL_Taste_rechts_Err 0 "normal" 1 "Fehler" ;
VAL_ 817 MFL_Tastencode_1 0 "Key_Released__No_Key" 1 "Context_Menu" 2 "Menu_Up__Next_Screen" 3 "Menu_Down__Previous_Screen" 4 "Up" 5 "Down" 6 "Up__Down_ThumbWheel" 7 "OK__ThumbWheel_Button" 8 "Cancel__Escape" 9 "Main_Menu" 10 "Side_Menu_left" 11 "Side_Menu_right" 12 "FAS_Menu" 13 "Left__Right_ThumbWheel" 14 "FAS_Menu_ThumbWheel" 16 "Volume_Up" 17 "Volume_Down" 18 "Volume_Up__Down_ThumbWheel" 19 "Volume_ThumbWheel_Button" 20 "Audio_Source" 21 "Arrow_A_Up__Right" 22 "Arrow_A_Down__Left" 23 "Arrow_B_Up__Right" 24 "Arrow_B_Down__Left" 25 "PTT__PushToTalk" 26 "PTT_Cancel" 27 "Route_Info" 28 "Hook" 29 "Hang_Up" 30 "Off_Hook" 31 "Light_On__Off" 32 "Mute" 33 "Joker1" 34 "Joker2" 35 "View" 36 "Arrow_A_Up__Down_ThumbWheel" 37 "Lenkradheizung" 38 "Rekuperation" 39 "Tube_Toggle" 40 "DRS_Drag_Reduction_System" 41 "Stopwatch_Start_Stop" 42 "Stopwatch_Nextlap" 100 "MAP" 101 "MAP_Boost" 102 "Turn_signal_left" 103 "Turn_signal_right" 104 "Turn_signal_off" 105 "Flashlight" 106 "Highbeam" 107 "Washer_button" 108 "Wiper_button_left" 109 "Wiper_button_right" 110 "Wiper_button_cancel" 111 "Exhaust_Sound" 112 "Drive_Select_button" 113 "Sport_button" 114 "ESP_Drift_Selection_ThumbWheel" 115 "PTT_special_vehicle" 116 "TravelAssist" 117 "Launch_Control" 118 "Drift_Mode_Button_Increase" 119 "Drift_Mode_Button_Decrease" 120 "Drift_Mode_Button_Select" 121 "Drive_Mode_Button_Increase" 122 "Drive_Mode_Button_Decrease" 123 "Drive_Mode_Button_Select" 124 "E_Boost_Button_Increase" 125 "E_Boost_Button_Decrease" 126 "E_Boost_Button_Select" 127 "PerformanceHybridButton_Increase" 128 "PerformanceHybridButton_Decrease" 129 "EV_Mode_Button" 130 "HUD_Button" 131 "PASM_Wheel" 132 "PASM_Button" 133 "PTV_Wheel" 134 "PTV_Button" 135 "TC_ESC_Wheel" 136 "TC_ESC_Button" 240 "Startup_Reset" 241 "Initialization" ;
VAL_ 817 MFL_Tastencode_2 0 "Key_Released__No_Key" 1 "Context_Menu" 2 "Menu_Up__Next_Screen" 3 "Menu_Down__Previous_Screen" 4 "Up" 5 "Down" 6 "Up__Down_ThumbWheel" 7 "OK__ThumbWheel_Button" 8 "Cancel__Escape" 9 "Main_Menu" 10 "Side_Menu_left" 11 "Side_Menu_right" 12 "FAS_Menu" 13 "Left__Right_ThumbWheel" 14 "FAS_Menu_ThumbWheel" 16 "Volume_Up" 17 "Volume_Down" 18 "Volume_Up__Down_ThumbWheel" 19 "Volume_ThumbWheel_Button" 20 "Audio_Source" 21 "Arrow_A_Up__Right" 22 "Arrow_A_Down__Left" 23 "Arrow_B_Up__Right" 24 "Arrow_B_Down__Left" 25 "PTT__PushToTalk" 26 "PTT_Cancel" 27 "Route_Info" 28 "Hook" 29 "Hang_Up" 30 "Off_Hook" 31 "Light_On__Off" 32 "Mute" 33 "Joker1" 34 "Joker2" 35 "View" 36 "Arrow_A_Up_Right_Down_Left_ThumbWheel" 37 "Lenkradheizung" 38 "Rekuperation" 39 "Tube_Toggle" 40 "DRS_Drag_Reduction_System" 41 "Stopwatch_Start_Stop" 42 "Stopwatch_Nextlap" 100 "MAP" 101 "MAP_Boost" 102 "Turn_signal_left" 103 "Turn_signal_right" 104 "Turn_signal_off" 105 "Flashlight" 106 "Highbeam" 107 "Washer_button" 108 "Wiper_button_left" 109 "Wiper_button_right" 110 "Wiper_button_cancel" 111 "Exhaust_Sound" 112 "Drive_Select_button" 113 "Sport_button" 114 "ESP_Drift_Selection_ThumbWheel" 115 "PTT_special_vehicle" 116 "TravelAssist" 117 "Launch_Control" 118 "Drift_Mode_Button_Increase" 119 "Drift_Mode_Button_Decrease" 120 "Drift_Mode_Button_Select" 121 "Drive_Mode_Button_Increase" 122 "Drive_Mode_Button_Decrease" 123 "Drive_Mode_Button_Select" 124 "E_Boost_Button_Increase" 125 "E_Boost_Button_Decrease" 126 "E_Boost_Button_Select" 127 "PerformanceHybridButton_Increase" 128 "PerformanceHybridButton_Decrease" 129 "EV_Mode_Button" 130 "HUD_Button" 131 "PASM_Wheel" 132 "PASM_Button" 133 "PTV_Wheel" 134 "PTV_Button" 135 "TC_ESC_Wheel" 136 "TC_ESC_Button" 240 "Startup_Reset" 241 "Initialization" ;
VAL_ 817 MFL_Tip_Down 0 "nicht_betaetigt" 1 "betaetigt" ;
VAL_ 817 MFL_Tip_links_Err 0 "normal" 1 "Fehler" ;
VAL_ 817 MFL_Tip_rechts_Err 0 "normal" 1 "Fehler" ;
VAL_ 817 MFL_Tip_Up 0 "nicht_betaetigt" 1 "betaetigt" ;
VAL_ 560 MFL_Beruehrungserkennung 0 "nicht_beruehrt" 1 "links" 2 "rechts" 3 "beidseitig" ;
VAL_ 560 MFL_Touch_Event 0 "nicht_betaetigt" 1 "Tippen" 2 "Wischen_Slide" 3 "Geste" 4 "Doppeltippen" 5 "Longpress_1" 6 "Longpress_2" 7 "Longpress_3" 8 "Press" 9 "Strongpress" 10 "reserviert" 11 "reserviert" 12 "reserviert" 13 "reserviert" 14 "Taktgeber_Inkrement" 15 "Fehler" ;
VAL_ 2463978751 MFL_Taste_SDS_benoetigt 0 "nicht_benoetigt" 1 "benoetigt" ;
VAL_ 2463978751 MFL_Tasten_UpDownOK_benoetigt 0 "nicht_benoetigt" 1 "benoetigt" ;
VAL_ 2463978751 MFL_Tasten_Volume_benoetigt 0 "nicht_benoetigt" 1 "benoetigt" ;
VAL_ 2463978751 MFL_Vibrationsimpuls_links 0 "Kein_Impuls" 1 "Impuls_1" 2 "Impuls_2" 3 "Impuls_3" 4 "Impuls_4" 5 "Impuls_5" 6 "Impuls_6" 7 "Impuls_7" 8 "Impuls_8" 9 "Impuls_9" 10 "Impuls_10" 11 "Impuls_11" 12 "Impuls_12" 13 "Impuls_13" 14 "Impuls_14" 15 "Impuls_15" ;
VAL_ 2463978751 MFL_Vibrationsimpuls_rechts 0 "Kein_Impuls" 1 "Impuls_1" 2 "Impuls_2" 3 "Impuls_3" 4 "Impuls_4" 5 "Impuls_5" 6 "Impuls_6" 7 "Impuls_7" 8 "Impuls_8" 9 "Impuls_9" 10 "Impuls_10" 11 "Impuls_11" 12 "Impuls_12" 13 "Impuls_13" 14 "Impuls_14" 15 "Impuls_15" ;
VAL_ 1471 MFL_Eventcode_1 0 "W_no_event____T_no_event" 1 "W_1_Tick_up__T_pressed_normal" 2 "W_2_Ticks_up__T_touched" 3 "W_3_Ticks_up__T_double_click_nor" 4 "W_4_Ticks_up__T_long_press_nor_1" 5 "W_5_Ticks_up__T_long_press_nor_2" 6 "W_6_Ticks_up__T_long_press_nor_3" 7 "W_7_Ticks_up" 9 "W_7_Ticks_dn__T_pressed_strong" 10 "W_6_Ticks_dn" 11 "W_5_Ticks_dn__T_double_click_str" 12 "W_4_Ticks_dn__T_long_press_str_1" 13 "W_3_Ticks_dn__T_long_press_str_2" 14 "W_2_Ticks_dn__T_long_press_str_3" 15 "W_1_Tick_dn" ;
VAL_ 1471 MFL_Eventcode_2 0 "W_no_event____T_no_event" 1 "W_1_Tick_up__T_pressed_normal" 2 "W_2_Ticks_up__T_touched" 3 "W_3_Ticks_up__T_double_click_nor" 4 "W_4_Ticks_up__T_long_press_nor_1" 5 "W_5_Ticks_up__T_long_press_nor_2" 6 "W_6_Ticks_up__T_long_press_nor_3" 7 "W_7_Ticks_up" 9 "W_7_Ticks_dn__T_pressed_strong" 10 "W_6_Ticks_dn" 11 "W_5_Ticks_dn__T_double_click_str" 12 "W_4_Ticks_dn__T_long_press_str_1" 13 "W_3_Ticks_dn__T_long_press_str_2" 14 "W_2_Ticks_dn__T_long_press_str_3" 15 "W_1_Tick_dn" ;
VAL_ 1471 MFL_Marke 0 "VW" 1 "Audi" 2 "Seat" 3 "Skoda" 4 "VW_Nutzf" 5 "Bugatti" 6 "Lamborghini" 7 "Bentley" 8 "Rolls Royce" 9 "Quattro" 10 "kein_Hersteller_1" 11 "kein_Hersteller_2" 12 "kein_Hersteller_3" 13 "kein_Hersteller_4" 14 "Ford" 15 "Porsche" ;
VAL_ 1471 MFL_Tastencode_1 0 "Key_Released__No_Key" 1 "Context_Menu" 2 "Menu_Up__Next_Screen" 3 "Menu_Down__Previous_Screen" 4 "Up" 5 "Down" 6 "Up__Down_ThumbWheel" 7 "OK__ThumbWheel_Button" 8 "Cancel__Escape" 9 "Main_Menu" 10 "Side_Menu_left" 11 "Side_Menu_right" 12 "FAS_Menu" 13 "Left__Right_ThumbWheel" 14 "FAS_Menu_ThumbWheel" 16 "Volume_Up" 17 "Volume_Down" 18 "Volume_Up__Down_ThumbWheel" 19 "Volume_ThumbWheel_Button" 20 "Audio_Source" 21 "Arrow_A_Up__Right" 22 "Arrow_A_Down__Left" 23 "Arrow_B_Up__Right" 24 "Arrow_B_Down__Left" 25 "PTT__PushToTalk" 26 "PTT_Cancel" 27 "Route_Info" 28 "Hook" 29 "Hang_Up" 30 "Off_Hook" 31 "Light_On__Off" 32 "Mute" 33 "Joker1" 34 "Joker2" 35 "View" 36 "Arrow_A_Up__Down_ThumbWheel" 37 "Lenkradheizung" 38 "Rekuperation" 39 "Tube_Toggle" 40 "DRS_Drag_Reduction_System" 41 "Stopwatch_Start_Stop" 42 "Stopwatch_Nextlap" 100 "MAP" 101 "MAP_Boost" 102 "Turn_signal_left" 103 "Turn_signal_right" 104 "Turn_signal_off" 105 "Flashlight" 106 "Highbeam" 107 "Washer_button" 108 "Wiper_button_left" 109 "Wiper_button_right" 110 "Wiper_button_cancel" 111 "Exhaust_Sound" 112 "Drive_Select_button" 113 "Sport_button" 114 "ESP_Drift_Selection_ThumbWheel" 115 "PTT_special_vehicle" 116 "TravelAssist" 117 "Launch_Control" 118 "Drift_Mode_Button_Increase" 119 "Drift_Mode_Button_Decrease" 120 "Drift_Mode_Button_Select" 121 "Drive_Mode_Button_Increase" 122 "Drive_Mode_Button_Decrease" 123 "Drive_Mode_Button_Select" 124 "E_Boost_Button_Increase" 125 "E_Boost_Button_Decrease" 126 "E_Boost_Button_Select" 127 "PerformanceHybridButton_Increase" 128 "PerformanceHybridButton_Decrease" 129 "EV_Mode_Button" 130 "HUD_Button" 131 "PASM_Wheel" 132 "PASM_Button" 133 "PTV_Wheel" 134 "PTV_Button" 135 "TC_ESC_Wheel" 136 "TC_ESC_Button" 240 "Startup_Reset" 241 "Initialization" ;
VAL_ 1471 MFL_Tastencode_2 0 "Key_Released__No_Key" 1 "Context_Menu" 2 "Menu_Up__Next_Screen" 3 "Menu_Down__Previous_Screen" 4 "Up" 5 "Down" 6 "Up__Down_ThumbWheel" 7 "OK__ThumbWheel_Button" 8 "Cancel__Escape" 9 "Main_Menu" 10 "Side_Menu_left" 11 "Side_Menu_right" 12 "FAS_Menu" 13 "Left__Right_ThumbWheel" 14 "FAS_Menu_ThumbWheel" 16 "Volume_Up" 17 "Volume_Down" 18 "Volume_Up__Down_ThumbWheel" 19 "Volume_ThumbWheel_Button" 20 "Audio_Source" 21 "Arrow_A_Up__Right" 22 "Arrow_A_Down__Left" 23 "Arrow_B_Up__Right" 24 "Arrow_B_Down__Left" 25 "PTT__PushToTalk" 26 "PTT_Cancel" 27 "Route_Info" 28 "Hook" 29 "Hang_Up" 30 "Off_Hook" 31 "Light_On__Off" 32 "Mute" 33 "Joker1" 34 "Joker2" 35 "View" 36 "Arrow_A_Up_Right_Down_Left_ThumbWheel" 37 "Lenkradheizung" 38 "Rekuperation" 39 "Tube_Toggle" 40 "DRS_Drag_Reduction_System" 41 "Stopwatch_Start_Stop" 42 "Stopwatch_Nextlap" 100 "MAP" 101 "MAP_Boost" 102 "Turn_signal_left" 103 "Turn_signal_right" 104 "Turn_signal_off" 105 "Flashlight" 106 "Highbeam" 107 "Washer_button" 108 "Wiper_button_left" 109 "Wiper_button_right" 110 "Wiper_button_cancel" 111 "Exhaust_Sound" 112 "Drive_Select_button" 113 "Sport_button" 114 "ESP_Drift_Selection_ThumbWheel" 115 "PTT_special_vehicle" 116 "TravelAssist" 117 "Launch_Control" 118 "Drift_Mode_Button_Increase" 119 "Drift_Mode_Button_Decrease" 120 "Drift_Mode_Button_Select" 121 "Drive_Mode_Button_Increase" 122 "Drive_Mode_Button_Decrease" 123 "Drive_Mode_Button_Select" 124 "E_Boost_Button_Increase" 125 "E_Boost_Button_Decrease" 126 "E_Boost_Button_Select" 127 "PerformanceHybridButton_Increase" 128 "PerformanceHybridButton_Decrease" 129 "EV_Mode_Button" 130 "HUD_Button" 131 "PASM_Wheel" 132 "PASM_Button" 133 "PTV_Wheel" 134 "PTV_Button" 135 "TC_ESC_Wheel" 136 "TC_ESC_Button" 240 "Startup_Reset" 241 "Initialization" ;
VAL_ 958 MO_Aussp_Anlass 0 "Anlasser_darf_angesteuert_werden" 1 "Anlasser_ausspuren__Ansteuerung_nicht_moeglich" ;
VAL_ 958 MO_BKV_Unterdruckwarnung 0 "Unterdruckhaushalt_iO" 1 "Unterdruckhaushalt_niO" ;
VAL_ 958 MO_BLS 0 "kein_Bremsen" 1 "Bremse_betaetigt" ;
VAL_ 958 MO_BMS_NV_Anf_stuetzen 0 "nicht_notwendig" 1 "notwendig" ;
VAL_ 958 MO_EKlKomLeiRed 0 "keine_Leistungsbegr" 1 "Leistungsbegr_75" 2 "Leistungsbegr_50" 3 "Leistungsbegr_25" ;
VAL_ 958 MO_Ext_E_Fahrt_aktiv 0 "Rueckmeldung_E_Taster_aus" 1 "Rueckmeldung_E_Taster_ein" ;
VAL_ 958 MO_Fahrer_bremst 0 "kein_Bremsen" 1 "Bremse_betaetigt" ;
VAL_ 958 MO_FMAus_aktiv 0 "inaktiv" 1 "Segeln_mit_Motor_aus_aktiv" ;
VAL_ 958 MO_FMAus_Startvariante 0 "kein_Motorstart" 1 "Motorstart_elektrischer_Starter" 2 "GetriebeAnschleppstart" 3 "GetriebeNotAnschleppstart" ;
VAL_ 958 MO_Freig_Anlass 0 "Start_nicht_zulaessig" 1 "Startfreigabe" ;
VAL_ 958 MO_Freig_Reku 0 "Rekuperations-Modus aus" 1 "Empfehlung Spannungsanhebung" 2 "Empfehlung Spannungsabsenkung" 3 "Rekuperationsmodus aktiv, Spannungsvariation nicht notwendig" ;
VAL_ 958 MO_Freigabe_Segeln 0 "Segelbetrieb_nicht_freigegeben" 1 "Segelbetrieb_freigegeben" ;
VAL_ 958 MO_Gangposition 0 "Gang_N" 1 "Gang_1" 2 "Gang_2" 3 "Gang_3" 4 "Gang_4" 5 "Gang_5" 6 "Gang_6" 7 "Gang_7" 8 "Gang_8" 9 "Automat_P" 10 "Automat_Vorwaerts_S" 11 "Automat_Vorwaerts_D/E" 12 "Zwischenstellung" 13 "Gang_R" 14 "Istgang_nicht_definiert" 15 "Fehler" ;
VAL_ 958 MO_Handshake_STH 0 "keine EKP-Ansteuerung durch STH-Anforderung" 1 "EKP-Ansteuerung durch STH-Anforderung" ;
VAL_ 958 MO_HYB_Fahrbereitschaft 0 "keine_Fahrbereitschaft" 1 "Fahrbereitschaft" ;
VAL_ 958 MO_HYB_VM_aktiv 0 "VM_nicht_aktiv" 1 "VM_aktiv" ;
VAL_ 958 MO_Interlock 0 "Interlockschalter_nicht_betaetigt" 1 "Interlockschalter_betaetigt" ;
VAL_ 958 MO_Kickdown 0 "kein_Kickdown" 1 "Kickdown" ;
VAL_ 958 MO_Kl_50 0 "aus" 1 "KL50_ein_Startausfuehrung_Fahrer" ;
VAL_ 958 MO_Kl_75 0 "Aus" 1 "Ein" ;
VAL_ 958 MO_Klima_Eingr 0 "kein Eingriff" 1 "Klimakompressor ausschalten" 2 "Klimakompressor Leistungsreduzierung" 3 "Klimakompressor aufgrund der Heissleuchtenvorwarnung ausschalten" ;
VAL_ 958 MO_Konsistenz_Bremsped 0 "Bremspedalinformation_plausibel" 1 "Bremspedalinformation_unplausibel" ;
VAL_ 958 MO_Kuppl_schalter 0 "Schalter_sagt_ausgekuppelt" 1 "Schalter_sagt_eingekuppelt" ;
VAL_ 958 MO_Motor_laeuft 0 "Motor_laeuft_nicht" 1 "Motor_laeuft_autark_und_stabil_und_darf_mechanisch_belastet_werden" ;
VAL_ 958 MO_PTC_Status 0 "nicht_unterstuetzt" 1 "Stufe_0" 2 "Stufe_1" 3 "Stufe_2" 4 "Stufe_3" 7 "PTC_am_BCM" ;
VAL_ 958 MO_QBit_Fahrer_bremst 0 "gueltiger_Wert" 1 "Ersatz_Init_oder_Fehlerwert" ;
VAL_ 958 MO_QBit_Gangposition 0 "gueltiger_Wert" 1 "Ersatz_Init_oder_Fehlerwert" ;
VAL_ 958 MO_QBit_KL_75 0 "gueltiger_Wert" 1 "Ersatz_Init_oder_Fehlerwert" ;
VAL_ 958 MO_Remotestart_Betrieb 0 "MSG_nicht_bereit_fuer_RS_Betrieb" 1 "MSG_bereit_fuer_oder_im_RS_Betrieb" ;
VAL_ 958 MO_Remotestart_moeglich 0 "Remotestart_nicht_moeglich" 1 "Remotestart_moeglich" ;
VAL_ 958 MO_Signalquelle_Gangposition 0 "Sensorsignal" 1 "Modellsignal" ;
VAL_ 958 MO_StartStopp_Fahrerwunsch 0 "Init" 1 "Stoppverbot_durch_Fahrer" 2 "Stoppfreigabe_durch_Fahrer" 3 "Stoppanforderung_durch_Fahrer" ;
VAL_ 958 MO_StartStopp_Motorstopp 0 "Motor_Stop_inaktiv" 1 "Motor_Stop_aktiv" ;
VAL_ 958 MO_StartStopp_Status 0 "System_in_diesem_KL15_Zyklus_nicht_verfuegbar" 1 "System_aktiv_keine_Freigabe_durch_StartStop_Koordinator" 2 "System_aktiv_alle_Freigaben_liegen_vor" 3 "System_aktiv_mindestens_eine_Freigabe_fehlt" ;
VAL_ 958 MO_StartStopp_Wiederstart 0 "Wiederstart_inaktiv" 1 "Wiederstart_aktiv" ;
VAL_ 958 MO_StartVorauss_erfuellt 0 "Signal_nicht_bedient" 1 "StartVorauss_nicht_ueberpruefbar" 2 "StartVorauss_nicht_erfuellt" 3 "StartVorauss_erfuellt" ;
VAL_ 958 MO_Timeout_ESP 0 "Empfang_iO" 1 "Timeout" ;
VAL_ 958 MO_Zylinderabschaltung 0 "Vollmotorbetrieb_VMB" 1 "Uebergang_HMB_in_VMB" 2 "Uebergang_VMB_in_HMB" 3 "Halbmotorbetrieb_HMB" ;
VAL_ 1648 MO1_Freigabe_Info_WFS 0 "ungueltig" 1 "gueltig" ;
VAL_ 1648 MO1_Freigabe_Verfallsinfo_WFS 0 "verfaellt_nicht" 1 "verfaellt" ;
VAL_ 1648 MO1_Sperr_Info_WFS 0 "nicht_gesperrt" 1 "gesperrt" ;
VAL_ 1648 MO_Abstellzeit 254 "Init" 255 "reserviert" ;
VAL_ 1648 MO_Abstellzeit_Status 0 "Abstellzeit_nicht_berechnet" 1 "Abstellzeit_berechnet" 2 "Abstellzeit_Minimalwert" 3 "Abstellzeit_ungueltig" ;
VAL_ 1648 MO_ANC_Kennfeld_Anf 0 "Kennfeld_1" 1 "Uebergang_Kennfeld_2_nach_1" 2 "Uebergang_Kennfeld_1_nach_2" 3 "Kennfeld_2" ;
VAL_ 1648 MO_Anzahl_Abgesch_Zyl 0 "Vollmotorbetrieb" 1 "1_Zylinder_abgeschaltet" 2 "2_Zylinder_abgeschaltet" 3 "3_Zylinder_abgeschaltet" 4 "4_Zylinder_abgeschaltet" 5 "5_Zylinder_abgeschaltet" 6 "6_Zylinder_abgeschaltet" 7 "8_Zylinder_abgeschaltet" ;
VAL_ 1648 MO_Bremslicht_Reku 0 "Aus" 1 "Ein" ;
VAL_ 1648 MO_Drehzahl_Warnung 0 "keinen_Warnhinweis_anzeigen" 1 "Warnhinweis_anzeigen" ;
VAL_ 1648 MO_EPCL 0 "EPCL_aus_kein_Text" 1 "EPCL_gelb_Stoerung" 2 "EPCL_gelb_Leistungsbeschraenkung" 3 "EPCL_rot_Fzg_sicher_abstellen" ;
VAL_ 1648 MO_Ethanol_BS_Texte 0 "kein_Text" 1 "E85_Warm_Up" 2 "FlexFuel_Warnung_Stufe_3" 3 "Warmfahrempfehlung_MQB__FlexFuel_Warnung_Stufe_1" 4 "FlexFuel_Warnung_Stufe_2" 5 "FlexFuel_Warnung_Stufe_4" 6 "E25_Warm_Up" ;
VAL_ 1648 MO_Fahrzeugtyp 0 "Verbrenner_Fahrzeug" 1 "Hybrid" 2 "E_Fahrzeug" 3 "E_Fahrzeug_mit_Range_Extender" 4 "Brennstoffzellenfahrzeug" 5 "tbd" 6 "tbd" 7 "tbd" ;
VAL_ 1648 MO_Fehler_Zylabsch 0 "kein_Fehler" 1 "Notlauf_Vollmotorbetrieb" 2 "Notlauf_mindestens_einem_abgesch_Zylinder" ;
VAL_ 1648 MO_Hybrid_StartStopp_LED 0 "LED_aus_und_Blinken_aus" 1 "LED_ein_und_Blinken_aus" 2 "LED_ein_und_Blinken_ein_50_percent" 3 "reserviert" ;
VAL_ 1648 MO_obere_Drehzahlgrenze 0 "Init" ;
VAL_ 1648 MO_StartStopp_PopUp 0 "Statuswechsel_ohne_Taster (Init)" 1 "StSt_per_Taster_deaktiviert" 2 "StSt_per_Taster_aktiviert" 3 "nicht verwendet" ;
VAL_ 1648 MO_Zylabsch_Texte 0 "keine_Texte" 1 "Zylinderabschaltung_deaktivieren" 2 "Zylinderabschaltung_aktivieren" 3 "Zylinderabschaltung_unruhig" ;
VAL_ 1648 MO_Zylabsch_Texte_02 0 "ein_ZAS_generell_keine_ZAS_Anzeigen" 1 "ZAS_im_VMB" 2 "ZAS_im_ASB_1_Zyl_aktiv" 3 "ZAS_im_ASB_2_Zyl_aktiv" 4 "ZAS_im_ASB_3_Zyl_aktiv" 5 "ZAS_im_ASB_4_Zyl_aktiv" 6 "ZAS_im_ASB_5_Zyl_aktiv" 7 "ZAS_im_ASB_6_Zyl_aktiv" 8 "ZAS_im_ASB_8_Zyl_aktiv" 9 "ZAS_im_ASB_12_Zyl_aktiv" 13 "Uebergangsbetrieb" 14 "keine_ZAS_Anzeige_ggf_Stopp_Schub_Betrieb" 15 "ZAS_Stoerungs_Anzeige" ;
VAL_ 967 MO_E_Mode 0 "keine_Anzeige" 1 "E_Mode_passiv" 2 "E_Mode_aktiv" 3 "E_Mode_inaktiv_nicht_verfuegbar" 4 "E_Mode_aktiv_nicht_verfuegbar" 5 "reserviert_keine_Anzeige" 6 "reserviert_keine_Anzeige" 7 "reserviert_keine_Anzeige" ;
VAL_ 967 MO_E_Texte 0 "keine_Anzeige" 1 "Batterie_fast_leer" 2 "Ladestecker_nicht_fahrbereit" 3 "VM_Betrieb_erforderlich" 4 "Batterie_laedt_Nicht_ausschalten" 5 "Bitte_Bremse_treten" 6 "manueller_Neustart_erforderlich" 7 "Stopp_Fahrzeug_nicht_abschleppen" 8 "kein_Neustart_Haube_nicht_oeffnen" 9 "Motorstart_im_naechsten_Zyklus" 10 "VM_erforderlich_EVMode_abwaehlen" 11 "laengerer_VMBetrieb_Bordbuch" 12 "Tank_leer_VM_nicht_verfuegbar" 13 "Bitte_warten_Motor_startet" 14 "kein_Start_Batterietemperatur" 15 "Ende_elektrische_Reichweite_erreicht" ;
VAL_ 967 MO_E_Warnungen 0 "keine_Anzeige" 1 "Fehler_Elektrosystem_Anhalten" 2 "Fehler_Elektrosystem_Werkstatt" 3 "Elektrosystem_ueberhitzt_Stopp" 4 "Fehler_Hybridsystem_Anhalten" 5 "Fehler_Hybridsystem_Werkstatt" 6 "Fehler_Wasserstoffsystem_Anhalte" 7 "Fehler_Wasserstoffsystem_Werksta" 8 "reserviert_keine_Anzeige" 9 "reserviert_keine_Anzeige" 10 "reserviert_keine_Anzeige" 11 "reserviert_keine_Anzeige" 12 "reserviert_keine_Anzeige" 13 "reserviert_keine_Anzeige" 14 "reserviert_keine_Anzeige" 15 "reserviert_keine_Anzeige" ;
VAL_ 967 MO_EFLEX_Lampe 0 "Lampe_aus" 1 "Lampe_ein" 2 "Lampe_blinkend" 3 "Lampe_blinkend_mit_Akustik" ;
VAL_ 967 MO_Heissleuchte 0 "Lampe aus" 1 "Lampe ein" ;
VAL_ 967 MO_ITM_Warnung_Pumpe 0 "keine_Warnung" 1 "ITM_Warnung" ;
VAL_ 967 MO_KJS_nicht_bereit 0 "kein_Fehler" 1 "Fehler" ;
VAL_ 967 MO_Kuehlerluefter_1 126 "Init" 127 "Fehler" ;
VAL_ 967 MO_Kuehlerluefter_2 126 "Init" 127 "Fehler" ;
VAL_ 967 MO_Kuehlerluefter_MUX 0 "Kuehlerluefter_1" 1 "Kuehlerluefter_2" ;
VAL_ 967 MO_OBD2_Lampe 0 "Lampe aus" 1 "Lampe ein" ;
VAL_ 967 MO_Oelwarnung_max 0 "keine_Warnung" 1 "Warnfall_aktiv" ;
VAL_ 967 MO_Partikel_Lampe 0 "Lampe aus" 1 "Lampe ein" ;
VAL_ 967 MO_RedFahrleistung_Lampe 0 "Lampe_aus" 1 "Lampe_ein" ;
VAL_ 967 MO_Systemlampe 0 "Lampe aus" 1 "Lampe ein" ;
VAL_ 967 MO_Tankdeckel_Lampe 0 "Lampe aus" 1 "Lampe ein" ;
VAL_ 967 MO_Text_Motorstart 0 "keine_Anzeige" 1 "Motor_im_Stoppbetrieb" 2 "StartStopp_sicherheitsbedingt_deaktiviert" 3 "System_fordert_Wiederstart" 4 "Aufforderung_Motorstart" 5 "Motorlauf_noetig" 6 "Motorlaufwarnung" 9 "Unerwuenschter_Motorstillstand" 10 "Motorstart_nicht_moeglich" 11 "Fehler_Kupplungsschalter" 12 "Motor_startet" 13 "Kupplung_betaetigen" 14 "Waehlhebel_in_PN_Position" 15 "Bremse_treten" ;
VAL_ 967 MO_Text_Tankdeckelwarn 0 "kein_Text" 1 "Anzeige_Text_Tankdeckelwarnung_im_Kombi" ;
VAL_ 967 MO_Vorglueh_Lampe 0 "Lampe_aus" 1 "Lampe_ein" ;
VAL_ 967 MO_Zustand_HWP 0 "HWP_nicht_schaltbar" 1 "HWP_foerdert_nicht" 2 "HWP_foerdert" 3 "reserviert" ;
VAL_ 967 OLEV_Oelstand_nicht_vorhanden 0 "ï?½lstand vorhanden" 1 "ï?½lstand nicht vorhanden" ;
VAL_ 967 OLEV_Systemstoerung 0 "ï?½lsystem i.O." 1 "Systemstï?½rung ï?½lsystem" ;
VAL_ 967 WIV_Anzeige_aktiv 0 "Anzeige aus" 1 "WIV Anzeige aktiv" ;
VAL_ 967 WIV_laufender_Motor 0 "Messung_moeglich" 1 "Messung_nicht_moeglich" ;
VAL_ 967 WIV_nachfuellanzeige_ein 0 "keine_Nachfuellanzeige" 1 "Nachfuellanzeige" ;
VAL_ 967 WIV_nicht_betriebswarm 0 "Motor_warm" 1 "Motor_nicht_betriebswarm" ;
VAL_ 967 WIV_Oeldr_Warn_Motor 0 "keine_Warnung" 1 "niedrige_Oeldruckstufe_nicht_erreicht" ;
VAL_ 967 WIV_Oeldyn_avl 0 "Oeldyn_nicht_vorhanden" 1 "Oeldyn_vorhanden" ;
VAL_ 967 WIV_Oelmin_Warn 0 "in_Ordnung" 1 "Warnung" ;
VAL_ 967 WIV_Oelstand_nicht_vorhanden 0 "ï?½lstand vorhanden" 1 "ï?½lstand nicht vorhanden" ;
VAL_ 967 WIV_Oelsystem_aktiv 0 "Anzeige_aus" 1 "Anzeige_aktiv" ;
VAL_ 967 WIV_Schieflage 0 "Fahrzeug_gerade" 1 "Fahrzeug_in_Schieflage" ;
VAL_ 967 WIV_Sensorfehler 0 "in_Ordnung" 1 "Sensor_defekt" ;
VAL_ 967 WIV_Ueberfuell_deaktiv 0 "Ueberfuellwarnung_am_Kombi_aktiv" 1 "Ueberfuellwarnung_am_Kombi_deaktiv" ;
VAL_ 967 WIV_Ueberfuell_Warn 0 "in_Ordnung" 1 "Ueberfuellwarnung" ;
VAL_ 967 WIV_Unterfuell_Warn 0 "in_Ordnung" 1 "Unterfuellwarnung" ;
VAL_ 706 FDR_Warnung_ALR 0 "keine_Anzeige" 1 "Text_Stoerung_Allradverteilung" 2 "Text_Ausfall_Allradverteilung" 3 "reserved" ;
VAL_ 706 MO_ADR_Status 0 "nicht_aktiv" 1 "ADR_angefordert" 2 "ADR_aktiv" 3 "ADR_Fehler" ;
VAL_ 706 MO_AGA_Sound_Texte 0 "keine_Anzeige" 1 "Sound_off" 2 "Sound_on" ;
VAL_ 706 MO_Anz_Kuehlerluefter 0 "Kein_KuehlerluefterNachlauf" 1 "Text_Luefternachlauf_aktiv" 2 "Text_Luefternachlauf_DPF_aktiv" 3 "Platzhalter_weitere_Signale" 4 "Platzhalter_weitere_Signale" 5 "Platzhalter_weitere_Signale" 6 "Platzhalter_weitere_Signale" 7 "Platzhalter_weitere_Signale" ;
VAL_ 706 MO_Anzeige_FMAus_Text 0 "keine_Anzeige" 1 "FMAus_Systemfehler" ;
VAL_ 706 MO_Anzeige_StSt_Symbol 0 "keine_Anzeige" 1 "StSt_aktiv" 2 "Motorlauf_noetig" 3 "Fahrer_temporaer_abwesend" 4 "Fahrer_vielleicht_anwesend" ;
VAL_ 706 MO_Anzeige_StSt_Text 0 "keine_Anzeige" 1 "Systemfehler" 2 "Motor_manuell_starten" 3 "Rueckmeldung_durch_Fahrstufe_einlegen" 4 "Zuendungsabschaltwarnung_Timerstart" 5 "Zum_Motorstart_Bremse_treten" 6 "StSt_Aktivierung_nicht_moeglich_auf_Grund_Fahrprogramm" ;
VAL_ 706 MO_ElAntrieb_Abschleppwarnung 0 "keine_Anzeige" 1 "Abschleppen_nur_vorne_angehoben" 2 "Abschleppen_nur_hinten_angehoben" 3 "Fahrzeug_nicht_abschleppen" ;
VAL_ 706 MO_EM_Ueberhitzungswarnung 0 "keine_Anzeige" 1 "EM_heiss_langsam_Fahren" 2 "EM_heiss_Geschw_begrenzt" 3 "EM_heiss_Anhalten" ;
VAL_ 706 MO_Powermeter_Dauer_Grenze 4094 "Init" 4095 "Fehler" ;
VAL_ 706 MO_Rekuperationsstufe 0 "keine_Anzeige" 1 "Rekuperationsstufe_1" 2 "Rekuperationsstufe_2" 3 "Rekuperationsstufe_3" 4 "Rekuperationsstufe_4" 5 "Rekuperationsstufe_5" 6 "Rekuperationsstufe_auto" 7 "Init" ;
VAL_ 706 PEA_Texte 0 "Keine_Anzeige" 1 "PEA_Fahreruebernahme_noetig" 2 "PEA_Reku_nicht_verfuegbar" ;
VAL_ 706 TSK_Einheit_vMax_FahrerInfo 0 "km_h" 1 "mph" ;
VAL_ 706 TSK_Status_vMax_FahrerInfo 0 "keine_Anzeige" 1 "Anzeige_im_Fahrzeugstatus" 2 "PopUp_ohne_Gong__Eintrag_FhzStat" 3 "PopUp_mit_Gong__Eintrag_FhzStat" ;
VAL_ 706 TSK_Ueberstimmt_vMax_FahrerInfo 0 "nicht_ueberstimmbar" 1 "ueberstimmbar" 2 "ueberstimmt" ;
VAL_ 706 TSK_vMax_FahrerInfo 0 "Init___kein_Wert" ;
VAL_ 267 MO_Entkopplung_Sollschlupf 125 "Notoeffnen_Anfahrelement" 126 "Init" ;
VAL_ 267 MO_Fahrpedalgradient 255 "Fehler" ;
VAL_ 267 MO_Fahrpedalrohwert_01 255 "Fehler" ;
VAL_ 267 MO_Moment_im_Leerlauf 0 "kein_Leergas" 1 "Leergas" ;
VAL_ 267 MO_QBit_Fahrpedalwerte_01 0 "gueltiger_Wert" 1 "Ersatz_Init_oder_Fehlerwert" ;
VAL_ 267 MO_rel_Saugrohrdruck 0 "Init_Ueberdruck" 63 "Fehler" ;
VAL_ 267 MO_rel_Saugrohrdruck_gem_err 0 "errechnet" 1 "gemessen" ;
VAL_ 267 MO_Schubabschaltung 0 "keine_Schubabschaltung" 1 "Schubabschaltung_aktiv" ;
VAL_ 267 MO_Sig_Fahrpedalgradient 0 "Fahrpedalgradient positiv" 1 "Fahrpedalgradient negativ" ;
VAL_ 267 MO_StartStopp_StoppVorbereitung 0 "Motorstopp_nicht_in_Vorbereitung" 1 "Motorstopp_in_Vorbereitung" ;
VAL_ 267 MO_Status_MaxDrzEingriff 0 "kein_Eingriff" 1 "Schalteingriff" 2 "ESP_Eingriff" 3 "Achsdifferenzdrehzahl" 4 "Bauteilschutz" 5 "Rennstart_Fahrbarkeit" ;
VAL_ 267 MO_Status_MaxDrzEingriff_sek 0 "kein_Eingriff" 1 "Schalteingriff" 2 "ESP_Eingriff" 3 "Achsdifferenzdrehzahl" 4 "Bauteilschutz" 5 "Rennstart_Fahrbarkeit" ;
VAL_ 267 MO_Status_MinDrzEingriff 0 "kein_Eingriff" 1 "Schalteingriff" 2 "ESP_Eingriff" 3 "Achsdifferenzdrehzahl" 4 "Bauteilschutz" 5 "Rennstart_Fahrbarkeit" ;
VAL_ 267 MO_Status_MinDrzEingriff_sek 0 "kein_Eingriff" 1 "Schalteingriff" 2 "ESP_Eingriff" 3 "Achsdifferenzdrehzahl" 4 "Bauteilschutz" 5 "Rennstart_Fahrbarkeit" ;
VAL_ 267 MO_temporaere_Fahrerabwesenheit 0 "nicht_erkannt" 1 "erkannt" ;
VAL_ 267 TSK_a_Soll_gradientenbegrenzt 127 "Init_oder_nicht_aktiv" ;
VAL_ 267 TSK_ax_Getriebe_02 511 "Neutralwert" ;
VAL_ 267 TSK_Freig_Verzoeg_Anf 0 "Verzoegerungsanforderung_nicht_freigegeben" 1 "Verzoegerungsanforderung_freigegeben" ;
VAL_ 267 TSK_Hauptschalter_GRA_ACC 0 "Init" 1 "Aus" 2 "Ein" 3 "Fehler" ;
VAL_ 267 TSK_Kategorie_Verzoegerungsfkt 0 "Schnittstelle_nicht_vorhanden" 1 "Kategorie_Fahrerassistenz" 2 "Kategorie_Schubverzoegerung" 3 "reserviert" ;
VAL_ 267 TSK_Limiter_ausgewaehlt 0 "kein_Limiter_ausgewaehlt" 1 "Limiter_ausgewaehlt" ;
VAL_ 267 TSK_Notstopp_Anf 0 "Ueberwachung_aus" 1 "Ueberwachung_ein" 2 "Notstopp_ausloesen" ;
VAL_ 267 TSK_Radsollmoment 65534 "Init" 65535 "Fehler" ;
VAL_ 267 TSK_SRBM_Anf_ASIL 0 "keine_SRBM_Anforderung" 1 "SRBM_Anforderung_in_ASIL_QM" 2 "SRBM_Anforderung_in_ASIL_A" 3 "SRBM_Anforderung_in_ASIL_B" 4 "SRBM_Anforderung_in_ASIL_C" ;
VAL_ 267 TSK_SRBM_max_Gradient 126 "Init" 127 "Fehler" ;
VAL_ 267 TSK_Standby_Anf_ESP 0 "keine_Standby_Anforderung" 1 "Standby_Anforderung" ;
VAL_ 267 TSK_Status 0 "Hauptschalter_aus" 1 "Init" 2 "passiv" 3 "aktiv" 4 "Uebertreten" 5 "brake_only_Mode" 6 "reversibel_aus" 7 "irreversibel_aus" ;
VAL_ 267 TSK_v_Begrenzung_aktiv 0 "inaktiv" 1 "aktiv" ;
VAL_ 267 TSK_Zwangszusch_ESP 0 "keine_ESP_ASR_Beeinflussung" 1 "ESP_ASR_Beeinflussung" ;
VAL_ 330 Ladezustand_02 254 "Init" 255 "Fehler" ;
VAL_ 330 Ladezustand_gering 0 "keine_Anzeige" 1 "Ladezustand_gering" 2 "Batterie_fast_leer" 3 "Batterie_leer" ;
VAL_ 330 MO_Anzeige_Drehmoment 2046 "nicht_verbaut" 2047 "Fehler" ;
VAL_ 330 MO_Anzeige_Leistung 2046 "nicht_verbaut" 2047 "Fehler" ;
VAL_ 330 MO_Anzeige_Verbr_Einheit 0 "l_h" 1 "kg_h" ;
VAL_ 330 MO_Anzeigedrehz 4095 "reserviert" ;
VAL_ 330 MO_Effizienzmodus 0 "nicht_im_Effizienz_Modus" 1 "Effizienz_Modus" ;
VAL_ 330 MO_ePerformance 0 "Init" 254 "Funktion_deaktiv_Anz_ausgegraut" 255 "Fehler" ;
VAL_ 330 MO_ePowermeter 0 "Init_keine_Anzeige" 254 "Funktion_deaktiv_Anzeige_ausgegraut" 255 "Fehler_keine_Anzeige" ;
VAL_ 330 MO_Fehler_Oeldrucksensor 0 "kein_Fehler" 1 "Fehler" ;
VAL_ 330 MO_Hochschaltdrehz 0 "keine_manuelle_Hochschaltung" 4095 "Fehler" ;
VAL_ 330 MO_Istgang 0 "kein_Gang_eingelegt" 1 "Gang_1" 2 "Gang_2" 3 "Gang_3" 4 "Gang_4" 5 "Gang_5" 6 "Gang_6" 7 "Gang_7" 8 "Gang_8" 9 "Gang_9" ;
VAL_ 330 MO_KVS_Ueberlauf 0 "kein Ueberlauf" 1 "Kraftstoffverbrauchsignale mindestens 1x ï?½bergelaufen" ;
VAL_ 330 MO_Ladedruck 511 "Fehler" ;
VAL_ 330 MO_Oeldruck 254 "Init" 255 "Fehler" ;
VAL_ 330 MO_OnePedalDriving_Warnung 0 "keine_Warnung" 1 "Warnstufe_1" ;
VAL_ 330 MO_Powermeter 4093 "Off" ;
VAL_ 330 MO_Powermeter_Elm_02 0 "nicht_verbaut" 4094 "Init" ;
VAL_ 330 MO_rel_Ladedruck 255 "Fehler" ;
VAL_ 330 MO_Schaltblitz_Anz 101 "blinkende_Anzeige" 126 "Init_Funktion_nicht_aktiv" 127 "Fehler" ;
VAL_ 330 MO_Schaltempf_verfbar 0 "nicht_verfuegbar" 1 "verfuegbar" ;
VAL_ 330 MO_Sollgang 0 "keine_Empfehlung" 1 "Gang_1" 2 "Gang_2" 3 "Gang_3" 4 "Gang_4" 5 "Gang_5" 6 "Gang_6" 7 "Gang_7" 8 "Gang_8" 9 "Gang_9" 15 "Neutralgang" ;
VAL_ 330 MO_Zust_Antrieb 0 "VM bzw. Brennstoffz. aktiv" 1 "EM aktiv" 2 "VM bzw. Brennstoffz. u. EM aktiv" 3 "Segeln oder Reku aktiv" ;
VAL_ 330 MO_Zust_Betriebsstrategie 0 "Kein Hybrid" 1 "Depleting" 2 "Soft-Depleting " 3 "Sustaining" 4 "Increasing" 5 "Fremdgesteuert" ;
